VERSION ""

NS_ :

BS_:

BU_: ECM

BO_ 2566832128 SERV: 8 Vector__XXX
 SG_ SPN_0911 : 0|8@1+ (1,0) [0|255] "" Vector__XXX

BO_ 2565800175 HEFSR: 8 Vector__XXX
 SG_ FuelShutoffForHybrid : 0|2@1+ (1,0) [0|3] "unitless" Vector__XXX

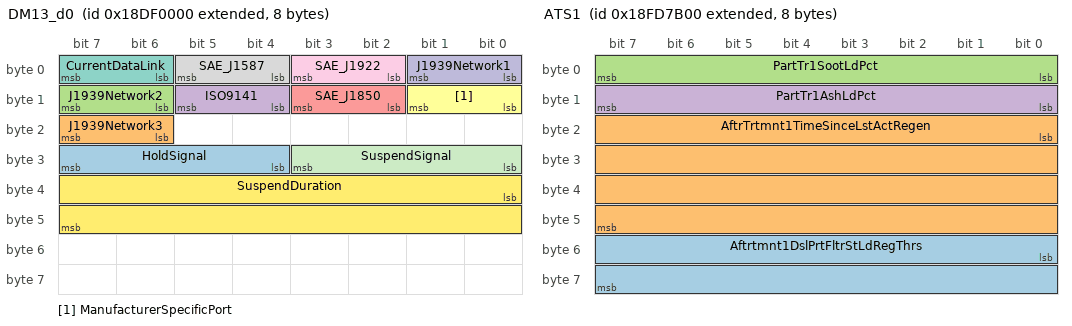
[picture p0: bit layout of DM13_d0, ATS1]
BO_ 2564751360 DM13_d0: 8 Vector__XXX
 SG_ HoldSignal : 28|4@1+ (1,0) [0|15] "" Vector__XXX
 SG_ J1939Network3 : 22|2@1+ (1,0) [0|3] "" Vector__XXX
 SG_ J1939Network2 : 14|2@1+ (1,0) [0|3] "" Vector__XXX
 SG_ ISO9141 : 12|2@1+ (1,0) [0|3] "" Vector__XXX
 SG_ SAE_J1850 : 10|2@1+ (1,0) [0|3] "" Vector__XXX
 SG_ ManufacturerSpecificPort : 8|2@1+ (1,0) [0|3] "" Vector__XXX
 SG_ CurrentDataLink : 6|2@1+ (1,0) [0|3] "" Vector__XXX
 SG_ SAE_J1587 : 4|2@1+ (1,0) [0|3] "" Vector__XXX
 SG_ SAE_J1922 : 2|2@1+ (1,0) [0|3] "" Vector__XXX
 SG_ J1939Network1 : 0|2@1+ (1,0) [0|3] "" Vector__XXX
 SG_ SuspendSignal : 24|4@1+ (1,0) [0|15] "" Vector__XXX
 SG_ SuspendDuration : 32|16@1+ (1,0) [0|64255] "seconds" Vector__XXX

BO_ 2566748416 ATI1: 32 Vector__XXX
 SG_ Aft1TripActiveRegenManRequests : 224|32@1+ (1,0) [0|4211081215] "Counts" Vector__XXX
 SG_ Aftertreatment1TripActiveRegens : 96|32@1+ (1,0) [0|4211081215] "Counts" Vector__XXX
 SG_ Aftertreatment1TripRegenTime : 32|32@1+ (1,0) [0|4211081215] "s" Vector__XXX
 SG_ Aftertreatment1TripFuelUsed : 0|32@1+ (0.5,0) [0|2105540607.5] "L" Vector__XXX

BO_ 2566748928 ATS1: 8 Vector__XXX
 SG_ Aftrtmnt1DslPrtFltrStLdRegThrs : 48|16@1+ (0.0025,0) [0|163.8375] "%" Vector__XXX
 SG_ AftrTrtmnt1TimeSinceLstActRegen : 16|32@1+ (1,0) [0|4211081215] "s" Vector__XXX
 SG_ PartTr1SootLdPct : 0|8@1+ (1,0) [0|250] "%" Vector__XXX
 SG_ PartTr1AshLdPct : 8|8@1+ (1,0) [0|250] "%" Vector__XXX

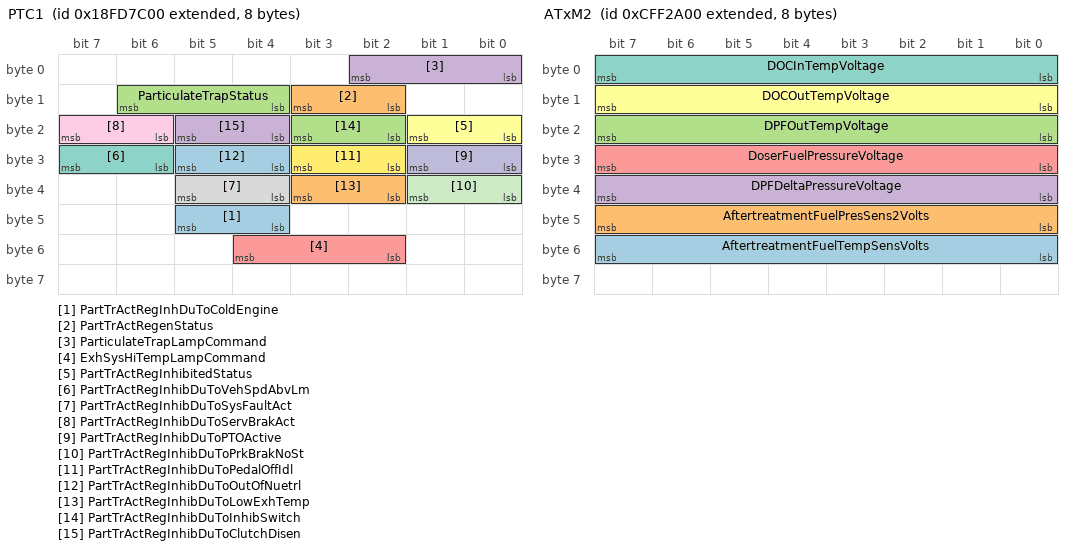
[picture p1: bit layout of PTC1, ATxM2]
BO_ 2566749184 PTC1: 8 Vector__XXX
 SG_ PartTrActRegInhDuToColdEngine : 44|2@1+ (1,0) [0|3] "" Vector__XXX
 SG_ PartTrActRegenStatus : 10|2@1+ (1,0) [0|3] "" Vector__XXX
 SG_ ParticulateTrapStatus : 12|3@1+ (1,0) [0|7] "" Vector__XXX
 SG_ ParticulateTrapLampCommand : 0|3@1+ (1,0) [0|7] "" Vector__XXX
 SG_ ExhSysHiTempLampCommand : 50|3@1+ (1,0) [0|7] "" Vector__XXX
 SG_ PartTrActRegInhibitedStatus : 16|2@1+ (1,0) [0|3] "" Vector__XXX
 SG_ PartTrActRegInhibDuToVehSpdAbvLm : 30|2@1+ (1,0) [0|3] "" Vector__XXX
 SG_ PartTrActRegInhibDuToSysFaultAct : 36|2@1+ (1,0) [0|3] "" Vector__XXX
 SG_ PartTrActRegInhibDuToServBrakAct : 22|2@1+ (1,0) [0|3] "" Vector__XXX
 SG_ PartTrActRegInhibDuToPTOActive : 24|2@1+ (1,0) [0|3] "" Vector__XXX
 SG_ PartTrActRegInhibDuToPrkBrakNoSt : 32|2@1+ (1,0) [0|3] "" Vector__XXX
 SG_ PartTrActRegInhibDuToPedalOffIdl : 26|2@1+ (1,0) [0|3] "" Vector__XXX
 SG_ PartTrActRegInhibDuToOutOfNuetrl : 28|2@1+ (1,0) [0|3] "" Vector__XXX
 SG_ PartTrActRegInhibDuToLowExhTemp : 34|2@1+ (1,0) [0|3] "" Vector__XXX
 SG_ PartTrActRegInhibDuToInhibSwitch : 18|2@1+ (1,0) [0|3] "" Vector__XXX
 SG_ PartTrActRegInhibDuToClutchDisen : 20|2@1+ (1,0) [0|3] "" Vector__XXX

BO_ 2565406464 ACKM_dall: 8 Vector__XXX
 SG_ AddressBusy m3 : 32|8@1+ (1,0) [0|255] "" Vector__XXX
 SG_ ParameterGroupNumber : 40|24@1+ (1,0) [0|16777215] "" Vector__XXX
 SG_ GroupFunctionValue : 8|8@1+ (1,0) [0|255] "" Vector__XXX
 SG_ ControlByte M : 0|8@1+ (1,0) [0|255] "" Vector__XXX
 SG_ AddressAccessDenied m2 : 32|8@1+ (1,0) [0|255] "" Vector__XXX
 SG_ AddressNegativeAcknowledgement m1 : 32|8@1+ (1,0) [0|255] "" Vector__XXX
 SG_ AddressAcknowledged m0 : 32|8@1+ (1,0) [0|255] "" Vector__XXX

BO_ 2365532672 ATxM2: 8 Vector__XXX
 SG_ AftertreatmentFuelTempSensVolts : 48|8@1+ (0.02,0) [0|5] "Volts" Vector__XXX
 SG_ AftertreatmentFuelPresSens2Volts : 40|8@1+ (0.02,0) [0|5] "Volts" Vector__XXX
 SG_ DPFOutTempVoltage : 16|8@1+ (0.02,0) [0|5] "Volts" Vector__XXX
 SG_ DPFDeltaPressureVoltage : 32|8@1+ (0.02,0) [0|5] "Volts" Vector__XXX
 SG_ DoserFuelPressureVoltage : 24|8@1+ (0.02,0) [0|5] "Volts" Vector__XXX
 SG_ DOCOutTempVoltage : 8|8@1+ (0.02,0) [0|5] "Volts" Vector__XXX
 SG_ DOCInTempVoltage : 0|8@1+ (0.02,0) [0|5] "Volts" Vector__XXX

BO_ 2566842624 LFC_s0: 8 Vector__XXX
 SG_ EngTotalFuelUsed : 32|32@1+ (0.5,0) [0|2105540607.5] "L" Vector__XXX
 SG_ EngTripFuel : 0|32@1+ (0.5,0) [0|2105540607.5] "L" Vector__XXX

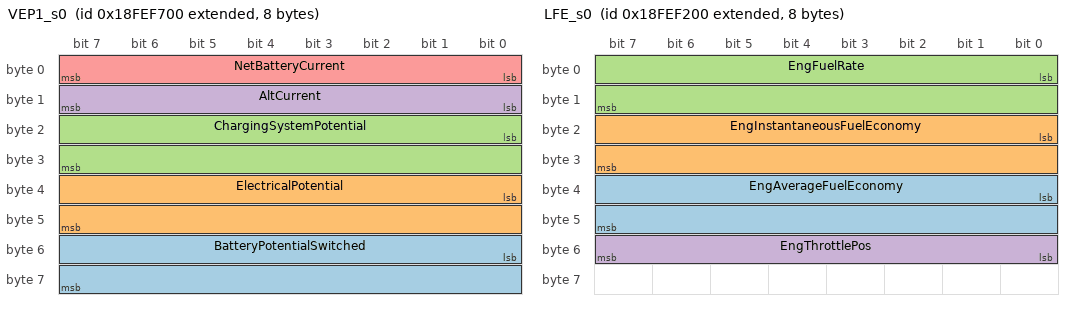
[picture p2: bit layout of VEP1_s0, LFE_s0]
BO_ 2566846208 VEP1_s0: 8 Vector__XXX
 SG_ BatteryPotentialSwitched : 48|16@1+ (0.05,0) [0|3212.75] "V" Vector__XXX
 SG_ ElectricalPotential : 32|16@1+ (0.05,0) [0|3212.75] "V" Vector__XXX
 SG_ ChargingSystemPotential : 16|16@1+ (0.05,0) [0|3212.75] "V" Vector__XXX
 SG_ AltCurrent : 8|8@1+ (1,0) [0|250] "A" Vector__XXX
 SG_ NetBatteryCurrent : 0|8@1+ (1,-125) [-125|125] "A" Vector__XXX

BO_ 2566844928 LFE_s0: 8 Vector__XXX
 SG_ EngAverageFuelEconomy : 32|16@1+ (0.001953125,0) [0|125.5] "km/L" Vector__XXX
 SG_ EngInstantaneousFuelEconomy : 16|16@1+ (0.001953125,0) [0|125.5] "km/L" Vector__XXX
 SG_ EngFuelRate : 0|16@1+ (0.05,0) [0|3212.75] "L/h" Vector__XXX
 SG_ EngThrottlePos : 48|8@1+ (0.4,0) [0|100] "%" Vector__XXX

BO_ 2566834688 DM1_s0: 22 Vector__XXX
 SG_ SPN5 : 144|16@1+ (1,0) [0|65536] "" Vector__XXX
 SG_ SPN4 : 112|16@1+ (1,0) [0|65536] "" Vector__XXX
 SG_ SPN3 : 80|16@1+ (1,0) [0|65536] "" Vector__XXX
 SG_ SPN2 : 48|16@1+ (1,0) [0|65536] "" Vector__XXX
 SG_ FailureModeIdentifier5 : 160|5@1+ (1,0) [0|0] "" Vector__XXX
 SG_ FailureModeIdentifier4 : 128|5@1+ (1,0) [0|0] "" Vector__XXX
 SG_ FailureModeIdentifier3 : 96|5@1+ (1,0) [0|0] "" Vector__XXX
 SG_ FlashRedStopLamp : 12|2@1+ (1,0) [0|3] "" Vector__XXX
 SG_ FlashProtectLamp : 8|2@1+ (1,0) [0|3] "" Vector__XXX
 SG_ FlashMalfuncIndicatorLamp : 14|2@1+ (1,0) [0|3] "" Vector__XXX
 SG_ FlashAmberWarningLamp : 10|2@1+ (1,0) [0|3] "" Vector__XXX
 SG_ MalfunctionIndicatorLampStatus : 6|2@1+ (1,0) [0|3] "" Vector__XXX
 SG_ AmberWarningLampStatus : 2|2@1+ (1,0) [0|3] "" Vector__XXX
 SG_ OccurenceCount1 : 40|7@1+ (1,0) [0|126] "" Vector__XXX
 SG_ SPNConversionMethod1 : 47|1@1+ (1,0) [0|1] "" Vector__XXX
 SG_ FailureModeIdentifier1 : 32|5@1+ (1,0) [0|0] "" Vector__XXX
 SG_ SPN1 : 16|16@1+ (1,0) [0|65536] "" Vector__XXX
 SG_ RedStopLampStatus : 4|2@1+ (1,0) [0|3] "" Vector__XXX
 SG_ ProtectLampStatus : 0|2@1+ (1,0) [0|3] "" Vector__XXX
 SG_ FailureModeIdentifier2 : 64|5@1+ (1,0) [0|0] "" Vector__XXX
 SG_ SPNConversionMethod5 : 175|1@1+ (1,0) [0|1] "" Vector__XXX
 SG_ SPNConversionMethod4 : 143|1@1+ (1,0) [0|1] "" Vector__XXX
 SG_ SPNConversionMethod3 : 111|1@1+ (1,0) [0|1] "" Vector__XXX
 SG_ SPNConversionMethod2 : 79|1@1+ (1,0) [0|1] "" Vector__XXX
 SG_ OccurenceCount5 : 168|7@1+ (1,0) [0|126] "" Vector__XXX
 SG_ OccurenceCount4 : 136|7@1+ (1,0) [0|126] "" Vector__XXX
 SG_ OccurenceCount3 : 104|7@1+ (1,0) [0|126] "" Vector__XXX
 SG_ OccurenceCount2 : 72|7@1+ (1,0) [0|126] "" Vector__XXX
 SG_ SPN5High : 165|3@1+ (1,0) [0|7] "" Vector__XXX
 SG_ SPN4High : 133|3@1+ (1,0) [0|7] "" Vector__XXX
 SG_ SPN3High : 101|3@1+ (1,0) [0|7] "" Vector__XXX
 SG_ SPN2High : 69|3@1+ (1,0) [0|7] "" Vector__XXX
 SG_ SPN1High : 37|3@1+ (1,0) [0|7] "" Vector__XXX

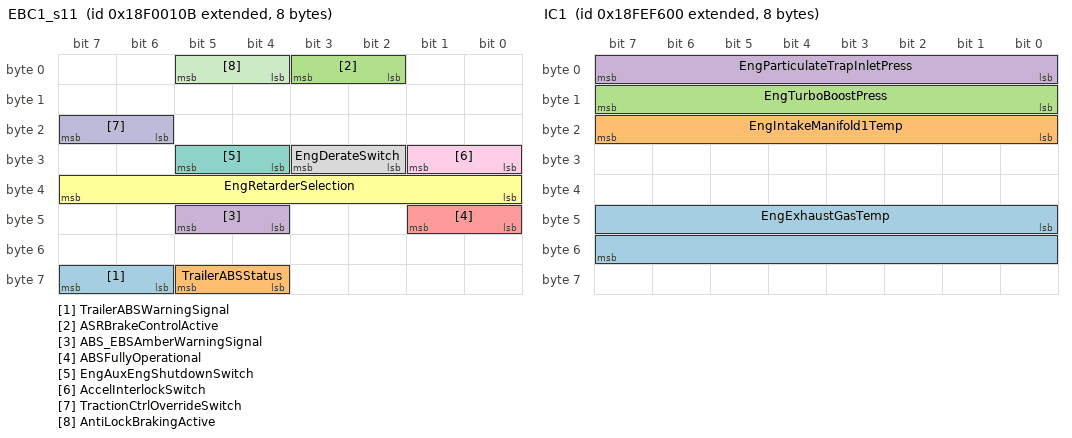
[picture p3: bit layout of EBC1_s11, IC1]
BO_ 2565865739 EBC1_s11: 8 Vector__XXX
 SG_ TrailerABSWarningSignal : 62|2@1+ (1,0) [0|3] "" Vector__XXX
 SG_ TrailerABSStatus : 60|2@1+ (1,0) [0|3] "" Vector__XXX
 SG_ ASRBrakeControlActive : 2|2@1+ (1,0) [0|3] "" Vector__XXX
 SG_ ABS_EBSAmberWarningSignal : 44|2@1+ (1,0) [0|3] "" Vector__XXX
 SG_ ABSFullyOperational : 40|2@1+ (1,0) [0|3] "" Vector__XXX
 SG_ EngRetarderSelection : 32|8@1+ (0.4,0) [0|100] "%" Vector__XXX
 SG_ EngAuxEngShutdownSwitch : 28|2@1+ (1,0) [0|3] "" Vector__XXX
 SG_ EngDerateSwitch : 26|2@1+ (1,0) [0|3] "" Vector__XXX
 SG_ AccelInterlockSwitch : 24|2@1+ (1,0) [0|3] "" Vector__XXX
 SG_ TractionCtrlOverrideSwitch : 22|2@1+ (1,0) [0|3] "" Vector__XXX
 SG_ AntiLockBrakingActive : 4|2@1+ (1,0) [0|3] "" Vector__XXX

BO_ 2565668608 TPCM_s0: 8 Vector__XXX
 SG_ TotalNumberOfPacketsEoMA m19 : 24|8@1+ (1,0) [0|255] "" Vector__XXX
 SG_ TotalMessageSizeEoMA m19 : 8|16@1+ (1,0) [0|64255] "counts" Vector__XXX
 SG_ TotalMessageSizeBAM m32 : 8|16@1+ (1,0) [0|64255] "counts" Vector__XXX
 SG_ TotalNumberOfPacketsBAM m32 : 24|8@1+ (1,0) [0|255] "" Vector__XXX
 SG_ ConnectionAbortReason m255 : 8|8@1+ (1,0) [0|255] "" Vector__XXX
 SG_ NextPacketNumberToBeSent m17 : 16|8@1+ (1,0) [0|255] "" Vector__XXX
 SG_ NumberOfPacketsThatCanBeSent m17 : 8|8@1+ (1,0) [0|255] "" Vector__XXX
 SG_ PGNumber : 40|24@1+ (1,0) [0|16777200] "" Vector__XXX
 SG_ MaximumNumberOfPackets m16 : 32|8@1+ (1,0) [0|255] "" Vector__XXX
 SG_ TotalNumberOfPackets m16 : 24|8@1+ (1,0) [0|255] "" Vector__XXX
 SG_ TotalMessageSize m16 : 8|16@1+ (1,0) [0|64255] "counts" Vector__XXX
 SG_ ControlByte M : 0|8@1+ (1,0) [0|255] "" Vector__XXX

BO_ 2565472279 RQST_d0: 3 Vector__XXX
 SG_ ParameterGroupNumber : 0|24@1+ (1,0) [0|16777215] "" Vector__XXX

BO_ 2566839296 IO: 8 Vector__XXX
 SG_ EngTotalIdleHours : 32|32@1+ (0.05,0) [0|210554060.75] "hr" Vector__XXX
 SG_ EngTotalIdleFuelUsed : 0|32@1+ (0.5,0) [0|2105540607.5] "L" Vector__XXX

BO_ 2566845952 IC1: 8 Vector__XXX
 SG_ EngExhaustGasTemp : 40|16@1+ (0.03125,-273) [-273|1735] "°C" Vector__XXX
 SG_ EngIntakeManifold1Temp : 16|8@1+ (1,-40) [-40|210] "°C" Vector__XXX
 SG_ EngTurboBoostPress : 8|8@1+ (2,0) [0|500] "kPa" Vector__XXX
 SG_ EngParticulateTrapInletPress : 0|8@1+ (0.5,0) [0|125] "kPa" Vector__XXX

BO_ 2565867774 HPG: 8 Vector__XXX
 SG_ FireApparatusPumpEngagement : 20|2@1+ (1,0) [0|3] "" Vector__XXX
 SG_ EngHydPressGovernorSwitch : 18|2@1+ (1,0) [0|3] "" Vector__XXX

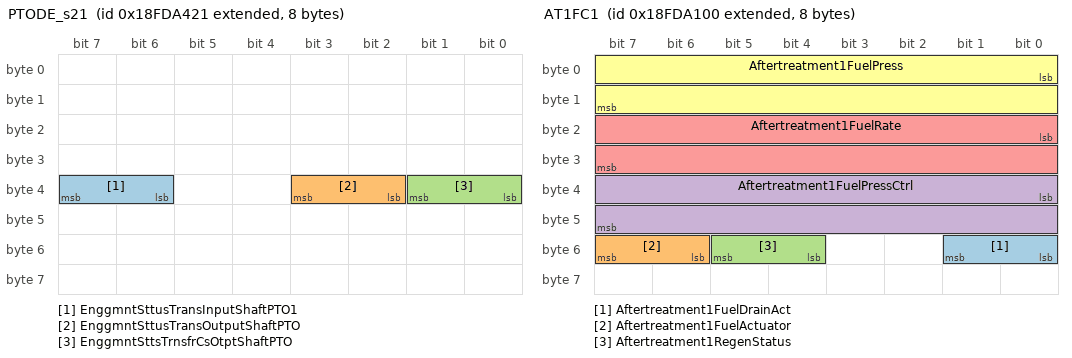
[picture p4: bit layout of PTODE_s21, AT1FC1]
BO_ 2566759457 PTODE_s21: 8 Vector__XXX
 SG_ EnggmntSttusTransInputShaftPTO1 : 38|2@1+ (1,0) [0|3] "" Vector__XXX
 SG_ EnggmntSttusTransOutputShaftPTO : 34|2@1+ (1,0) [0|3] "" Vector__XXX
 SG_ EnggmntSttsTrnsfrCsOtptShaftPTO : 32|2@1+ (1,0) [0|3] "" Vector__XXX

BO_ 2566758656 AT1FC1: 8 Vector__XXX
 SG_ Aftertreatment1FuelDrainAct : 48|2@1+ (1,0) [0|3] "none" Vector__XXX
 SG_ Aftertreatment1FuelActuator : 54|2@1+ (1,0) [0|3] "" Vector__XXX
 SG_ Aftertreatment1RegenStatus : 52|2@1+ (1,0) [0|3] "" Vector__XXX
 SG_ Aftertreatment1FuelPressCtrl : 32|16@1+ (0.0025,0) [0|160.6375] "%" Vector__XXX
 SG_ Aftertreatment1FuelRate : 16|16@1+ (0.05,0) [0|3212.75] "L/h" Vector__XXX
 SG_ Aftertreatment1FuelPress : 0|16@1+ (0.1,0) [0|6425.5] "kPa" Vector__XXX

BO_ 2566756352 AHI1: 32 Vector__XXX
 SG_ Aftertreatment1AvgTimeBetRegn : 256|32@1+ (1,0) [0|4211081215] "s" Vector__XXX
 SG_ AftrTrtmnt1TtlActvRgnInhRqsts : 192|32@1+ (1,0) [0|4211081215] "s" Vector__XXX
 SG_ AftrTrtmnt1TtlActvRgnMnlRqsts : 224|32@1+ (1,0) [0|4211081215] "s" Vector__XXX
 SG_ Aftertreatment1TotalNumActRegens : 96|32@1+ (1,0) [0|4294967295] "counts" Vector__XXX
 SG_ Aftertreatment1TotalRegenTime : 32|32@1+ (1,0) [0|4211081215] "s" Vector__XXX
 SG_ Aftertreatment1TotalDisabledTime : 64|32@1+ (1,0) [0|4211081215] "s" Vector__XXX
 SG_ Aftertreatment1TotalFuelUsed : 0|32@1+ (0.5,0) [0|2105540607.5] "L" Vector__XXX

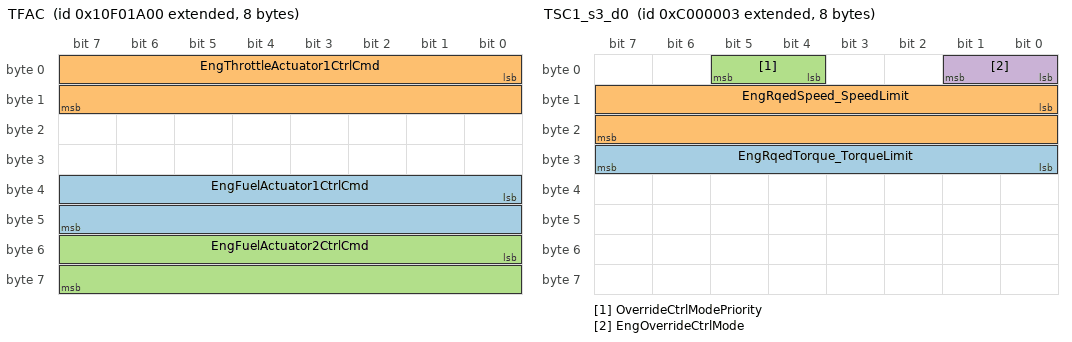
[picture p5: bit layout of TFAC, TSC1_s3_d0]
BO_ 2431654400 TFAC: 8 Vector__XXX
 SG_ EngFuelActuator1CtrlCmd : 32|16@1+ (0.0025,0) [0|160.6375] "%" Vector__XXX
 SG_ EngThrottleActuator1CtrlCmd : 0|16@1+ (0.0025,0) [0|160.6375] "%" Vector__XXX
 SG_ EngFuelActuator2CtrlCmd : 48|16@1+ (0.0025,0) [0|160.6375] "%" Vector__XXX

BO_ 2566764544 DM26: 8 Vector__XXX
 SG_ PMFilterMonComplete : 58|1@1+ (1,0) [0|1] "" Vector__XXX
 SG_ NOxCnvrtctlystMonComplete : 59|1@1+ (1,0) [0|1] "" Vector__XXX
 SG_ NHMCCnvrtctlystMonComplete : 60|1@1+ (1,0) [0|1] "" Vector__XXX
 SG_ BstPressCtrlSystemMoncomplete : 57|1@1+ (1,0) [0|1] "" Vector__XXX
 SG_ NHMCCnvrtctlystMonEnabled : 44|1@1+ (1,0) [0|1] "" Vector__XXX
 SG_ NOxCnvrtctlystMonEnabled : 43|1@1+ (1,0) [0|1] "" Vector__XXX
 SG_ PMFilterMonEnabled : 42|1@1+ (1,0) [0|1] "" Vector__XXX
 SG_ BstPressCtrlSystemMonEnabled : 41|1@1+ (1,0) [0|1] "" Vector__XXX
 SG_ MisfireMonitoringComplete : 28|1@1+ (1,0) [0|0] "" Vector__XXX
 SG_ MisfireMonitoringEnabled : 24|1@1+ (1,0) [0|0] "" Vector__XXX
 SG_ FuelSystemMonitoringEnabled : 25|1@1+ (1,0) [0|1] "" Vector__XXX
 SG_ ComprehensiveComptMonComplete : 30|1@1+ (1,0) [0|0] "" Vector__XXX
 SG_ ComprehensiveCompMonEnabled : 26|1@1+ (1,0) [0|1] "" Vector__XXX
 SG_ SecondAirSystemMonComplete : 51|1@1+ (1,0) [0|1] "" Vector__XXX
 SG_ SecondAirSystemMonEnabled : 35|1@1+ (1,0) [0|1] "" Vector__XXX
 SG_ OxygenSensorMonComplete : 53|1@1+ (1,0) [0|1] "" Vector__XXX
 SG_ OxygenSensorMonEnabled : 37|1@1+ (1,0) [0|1] "" Vector__XXX
 SG_ OxygenSensorHeaterMonComplete : 54|1@1+ (1,0) [0|1] "" Vector__XXX
 SG_ OxygenSensorHeaterMonEnabled : 38|1@1+ (1,0) [0|1] "" Vector__XXX
 SG_ HeatedCatalystMonComplete : 49|1@1+ (1,0) [0|0] "" Vector__XXX
 SG_ HeatedCatalystMonEnabled : 33|1@1+ (1,0) [0|0] "" Vector__XXX
 SG_ EvaporativeSystemMonComplete : 50|1@1+ (1,0) [0|1] "" Vector__XXX
 SG_ EvaporativeSystemMonEnabled : 34|1@1+ (1,0) [0|1] "" Vector__XXX
 SG_ EGRSystemMonitoringComplete : 55|1@1+ (1,0) [0|1] "" Vector__XXX
 SG_ EGRSystemMonitoringEnabled : 39|1@1+ (1,0) [0|1] "" Vector__XXX
 SG_ ColdStartAidSystemMonComplete : 56|1@1+ (1,0) [0|1] "" Vector__XXX
 SG_ ColdStartAidSystemMonEnabled : 40|1@1+ (1,0) [0|1] "" Vector__XXX
 SG_ CatalystMonComplete : 48|1@1+ (1,0) [0|1] "" Vector__XXX
 SG_ CatalystMonEnabled : 32|1@1+ (1,0) [0|1] "" Vector__XXX
 SG_ ACSystemRefrigerantMonComplete : 52|1@1+ (1,0) [0|1] "" Vector__XXX
 SG_ ACSystemRefrigerantMonEnabled : 36|1@1+ (1,0) [0|1] "" Vector__XXX
 SG_ FuelSystemMonitoringComplete : 29|1@1+ (1,0) [0|1] "" Vector__XXX
 SG_ NumOfWarmUpsSinceDTCsCleared : 16|8@1+ (1,0) [0|250] "" Vector__XXX
 SG_ TimeSinceEngineStart : 0|16@1+ (1,0) [0|64255] "seconds" Vector__XXX

BO_ 2566843392 VI: 18 Vector__XXX
 SG_ VI_Delimiter : 136|8@1+ (1,0) [0|0] "ASCII" Vector__XXX
 SG_ VIN_B17 : 128|8@1+ (1,0) [0|0] "ASCII" Vector__XXX
 SG_ VIN_B09_B016 : 64|64@1+ (1,0) [0|0] "ASCII" Vector__XXX
 SG_ VIN_B01_B08 : 0|64@1+ (1,0) [0|0] "ASCII" Vector__XXX

BO_ 2566842112 VH: 8 Vector__XXX
 SG_ TotalPowerTakeoffHours : 32|32@1+ (0.05,0) [0|210554060.75] "hr" Vector__XXX
 SG_ TotalVehicleHours : 0|32@1+ (0.05,0) [0|210554060.75] "hr" Vector__XXX

BO_ 2566832384 VDHR: 8 Vector__XXX
 SG_ HighResolutionTripDistance : 32|32@1+ (0.005,0) [0|21474836.475] "km" Vector__XXX
 SG_ HghRslutionTotalVehicleDistance : 0|32@1+ (0.005,0) [0|21055406] "km" Vector__XXX

BO_ 2348810243 TSC1_s3_d0: 8 Vector__XXX
 SG_ EngRqedTorque_TorqueLimit : 24|8@1+ (1,-125) [-125|125] "%" Vector__XXX
 SG_ EngRqedSpeed_SpeedLimit : 8|16@1+ (0.125,0) [0|8031.875] "rpm" Vector__XXX
 SG_ OverrideCtrlModePriority : 4|2@1+ (1,0) [0|3] "" Vector__XXX
 SG_ EngOverrideCtrlMode : 0|2@1+ (1,0) [0|3] "" Vector__XXX

BO_ 2633939712 TFI: 16 Vector__XXX
 SG_ TripFanOnTime : 0|32@1+ (0.05,0) [0|210554060.75] "hr" Vector__XXX

BO_ 2566821376 TCW: 8 Vector__XXX
 SG_ EngTurbo2WastegateDrive : 8|8@1+ (0.4,0) [0|100] "%" Vector__XXX
 SG_ EngTurbo1WastegateDrive : 0|8@1+ (0.4,0) [0|100] "%" Vector__XXX

BO_ 2566822400 TCI2: 8 Vector__XXX
 SG_ EngTurbo2CompressorInletTemp : 16|16@1+ (0.03125,-273) [-273|1735] "°C" Vector__XXX

BO_ 2566802179 TCFG2: 8 Vector__XXX
 SG_ TransTorqueLimit : 0|16@1+ (1,0) [0|64255] "Nm" Vector__XXX

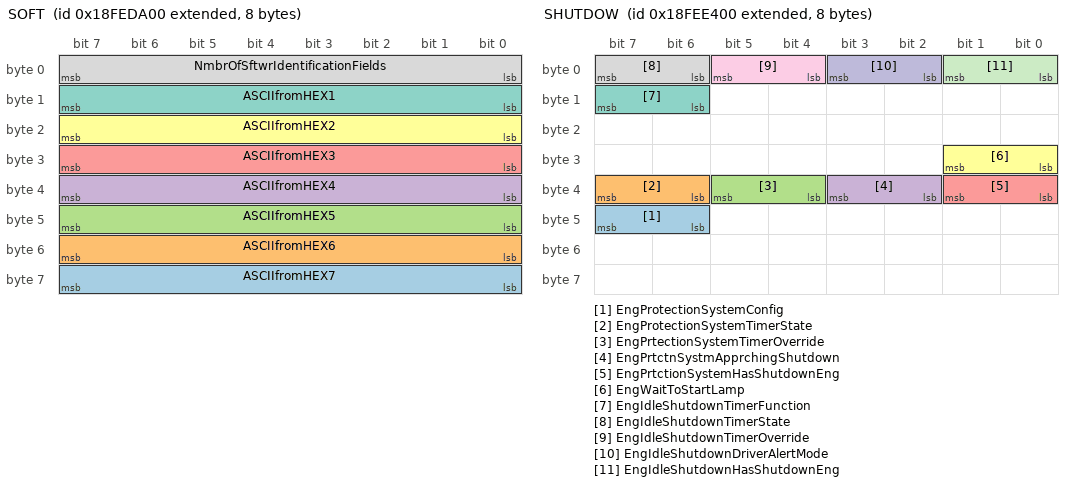
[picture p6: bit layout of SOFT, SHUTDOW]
BO_ 2566838784 SOFT: 8 Vector__XXX
 SG_ ASCIIfromHEX7 : 56|8@1+ (1,0) [0|0] "ASCII" Vector__XXX
 SG_ ASCIIfromHEX6 : 48|8@1+ (1,0) [0|0] "ASCII" Vector__XXX
 SG_ ASCIIfromHEX5 : 40|8@1+ (1,0) [0|0] "ASCII" Vector__XXX
 SG_ ASCIIfromHEX4 : 32|8@1+ (1,0) [0|0] "ASCII" Vector__XXX
 SG_ ASCIIfromHEX3 : 24|8@1+ (1,0) [0|0] "ASCII" Vector__XXX
 SG_ ASCIIfromHEX2 : 16|8@1+ (1,0) [0|0] "ASCII" Vector__XXX
 SG_ ASCIIfromHEX1 : 8|8@1+ (1,0) [0|0] "ASCII" Vector__XXX
 SG_ NmbrOfSftwrIdentificationFields : 0|8@1+ (1,0) [0|250] "steps" Vector__XXX

BO_ 2566841344 SHUTDOW: 8 Vector__XXX
 SG_ EngProtectionSystemConfig : 46|2@1+ (1,0) [0|3] "" Vector__XXX
 SG_ EngProtectionSystemTimerState : 38|2@1+ (1,0) [0|3] "" Vector__XXX
 SG_ EngPrtectionSystemTimerOverride : 36|2@1+ (1,0) [0|3] "" Vector__XXX
 SG_ EngPrtctnSystmApprchingShutdown : 34|2@1+ (1,0) [0|3] "" Vector__XXX
 SG_ EngPrtctionSystemHasShutdownEng : 32|2@1+ (1,0) [0|3] "" Vector__XXX
 SG_ EngWaitToStartLamp : 24|2@1+ (1,0) [0|3] "" Vector__XXX
 SG_ EngIdleShutdownTimerFunction : 14|2@1+ (1,0) [0|3] "" Vector__XXX
 SG_ EngIdleShutdownTimerState : 6|2@1+ (1,0) [0|3] "" Vector__XXX
 SG_ EngIdleShutdownTimerOverride : 4|2@1+ (1,0) [0|3] "" Vector__XXX
 SG_ EngIdleShutdownDriverAlertMode : 2|2@1+ (1,0) [0|3] "" Vector__XXX
 SG_ EngIdleShutdownHasShutdownEng : 0|2@1+ (1,0) [0|3] "" Vector__XXX

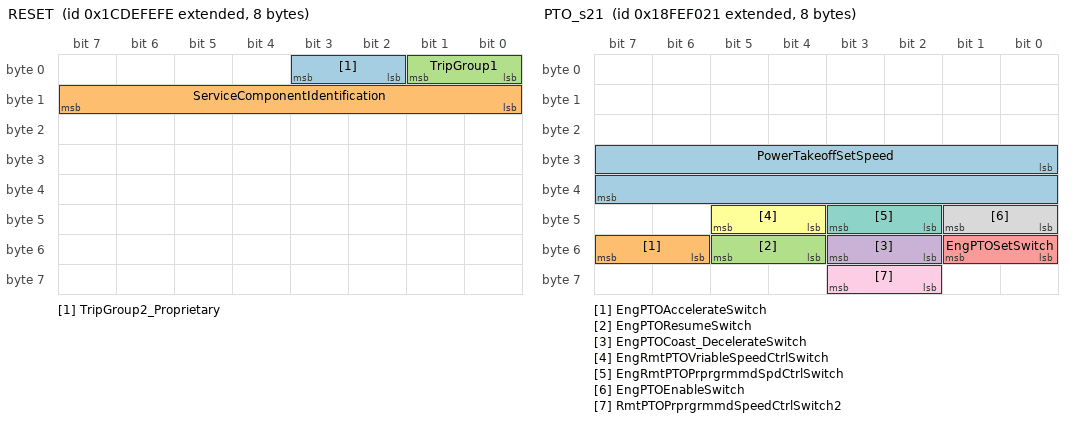
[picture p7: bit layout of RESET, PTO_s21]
BO_ 2631859966 RESET: 8 Vector__XXX
 SG_ TripGroup2_Proprietary : 2|2@1+ (1,0) [0|3] "" Vector__XXX
 SG_ ServiceComponentIdentification : 8|8@1+ (1,0) [0|250] "ID" Vector__XXX
 SG_ TripGroup1 : 0|2@1+ (1,0) [0|3] "" Vector__XXX

BO_ 2566840591 RC: 19 Vector__XXX
 SG_ PercentTorqueAtPeakTorquePoint5 : 144|8@1+ (1,-125) [-125|125] "%" Vector__XXX
 SG_ ReferenceRetarderTorque : 128|16@1+ (1,0) [0|64255] "Nm" Vector__XXX
 SG_ RetarderSpeedAtPeakTorquePoint5 : 112|16@1+ (0.125,0) [0|8031.875] "rpm" Vector__XXX
 SG_ PercentTorqueAtPoint4 : 104|8@1+ (1,-125) [-125|125] "%" Vector__XXX
 SG_ RetarderSpeedAtPoint4 : 88|16@1+ (0.125,0) [0|8031.875] "rpm" Vector__XXX
 SG_ PercentTorqueAtPoint3 : 80|8@1+ (1,-125) [-125|125] "%" Vector__XXX
 SG_ RetarderSpeedAtPoint3 : 64|16@1+ (0.125,0) [0|8031.875] "rpm" Vector__XXX
 SG_ PercentTorqueAtMaxSpeedPoint2 : 56|8@1+ (1,-125) [-125|125] "%" Vector__XXX
 SG_ MaxRetarderSpeedPoint2 : 40|16@1+ (0.125,0) [0|8031.875] "rpm" Vector__XXX
 SG_ PercentTorqueAtIdlePoint1 : 32|8@1+ (1,-125) [-125|125] "%" Vector__XXX
 SG_ RetarderSpeedAtIdlePoint1 : 16|16@1+ (0.125,0) [0|8031.875] "rpm" Vector__XXX
 SG_ RetarderLocation : 4|4@1+ (1,0) [0|15] "" Vector__XXX
 SG_ RetarderType : 0|4@1+ (1,0) [0|15] "" Vector__XXX

BO_ 2566844449 PTO_s21: 8 Vector__XXX
 SG_ PowerTakeoffSetSpeed : 24|16@1+ (0.125,0) [0|8031.875] "rpm" Vector__XXX
 SG_ EngPTOAccelerateSwitch : 54|2@1+ (1,0) [0|3] "" Vector__XXX
 SG_ EngPTOResumeSwitch : 52|2@1+ (1,0) [0|3] "" Vector__XXX
 SG_ EngPTOCoast_DecelerateSwitch : 50|2@1+ (1,0) [0|3] "" Vector__XXX
 SG_ EngPTOSetSwitch : 48|2@1+ (1,0) [0|3] "" Vector__XXX
 SG_ EngRmtPTOVriableSpeedCtrlSwitch : 44|2@1+ (1,0) [0|3] "" Vector__XXX
 SG_ EngRmtPTOPrprgrmmdSpdCtrlSwitch : 42|2@1+ (1,0) [0|3] "" Vector__XXX
 SG_ EngPTOEnableSwitch : 40|2@1+ (1,0) [0|3] "" Vector__XXX
 SG_ RmtPTOPrprgrmmdSpeedCtrlSwitch2 : 58|2@1+ (1,0) [0|3] "" Vector__XXX

BO_ 2633937664 LFI: 8 Vector__XXX
 SG_ TripAverageFuelRate : 32|16@1+ (0.05,0) [0|3212.75] "L/h" Vector__XXX
 SG_ TotalEngPTOFuelUsed : 0|32@1+ (0.5,0) [0|2105540607.5] "L" Vector__XXX

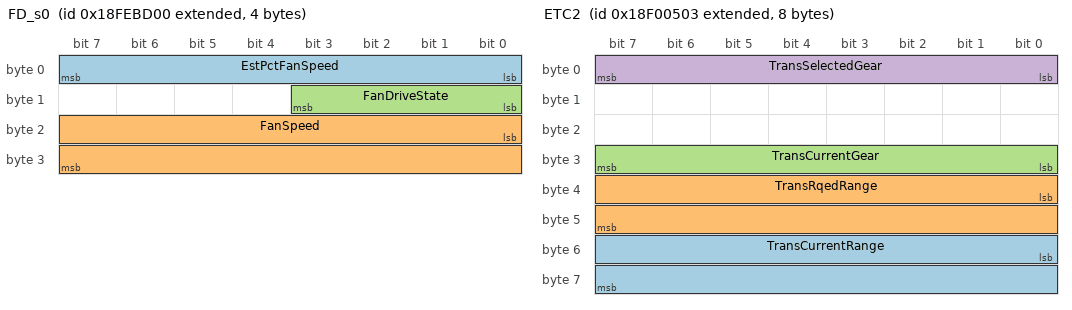
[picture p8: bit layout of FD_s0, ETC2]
BO_ 2566831360 FD_s0: 4 Vector__XXX
 SG_ EstPctFanSpeed : 0|8@1+ (0.4,0) [0|100] "%" Vector__XXX
 SG_ FanSpeed : 16|16@1+ (0.125,0) [0|8031.875] "rpm" Vector__XXX
 SG_ FanDriveState : 8|4@1+ (1,0) [0|15] "" Vector__XXX

BO_ 2565866755 ETC2: 8 Vector__XXX
 SG_ TransCurrentRange : 48|16@1+ (1,0) [0|255] "" Vector__XXX
 SG_ TransRqedRange : 32|16@1+ (1,0) [0|255] "" Vector__XXX
 SG_ TransCurrentGear : 24|8@1+ (1,-125) [-125|125] "" Vector__XXX
 SG_ TransSelectedGear : 0|8@1+ (1,-125) [-125|125] "" Vector__XXX

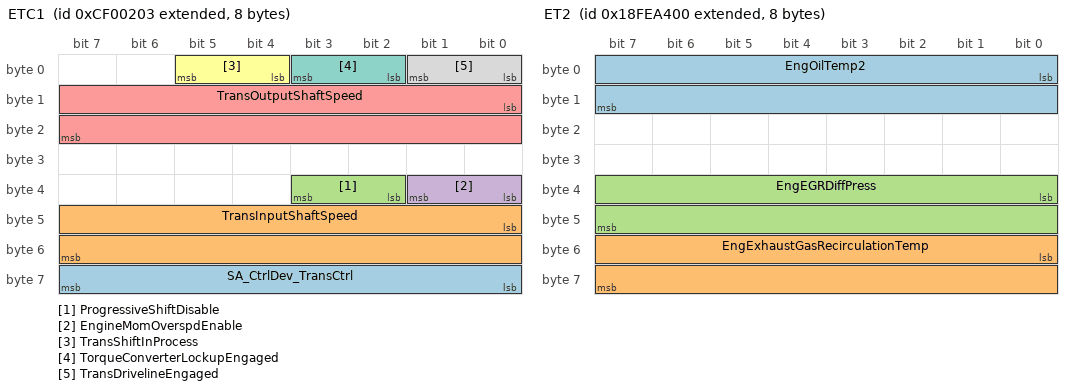
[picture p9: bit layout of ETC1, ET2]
BO_ 2364539395 ETC1: 8 Vector__XXX
 SG_ SA_CtrlDev_TransCtrl : 56|8@1+ (1,0) [0|255] "" Vector__XXX
 SG_ TransInputShaftSpeed : 40|16@1+ (0.125,0) [0|8031.875] "rpm" Vector__XXX
 SG_ ProgressiveShiftDisable : 34|2@1+ (1,0) [0|3] "" Vector__XXX
 SG_ EngineMomOverspdEnable : 32|2@1+ (1,0) [0|3] "" Vector__XXX
 SG_ TransOutputShaftSpeed : 8|16@1+ (0.125,0) [0|8031.875] "rpm" Vector__XXX
 SG_ TransShiftInProcess : 4|2@1+ (1,0) [0|3] "" Vector__XXX
 SG_ TorqueConverterLockupEngaged : 2|2@1+ (1,0) [0|3] "" Vector__XXX
 SG_ TransDrivelineEngaged : 0|2@1+ (1,0) [0|3] "" Vector__XXX

BO_ 2566809856 ET3: 8 Vector__XXX
 SG_ EngChargeAirCoolerOutletTemp : 48|16@1+ (0.03125,-273) [-273|1735] "°C" Vector__XXX
 SG_ EngIntakeManifold1AirTemp : 0|16@1+ (0.03125,-273) [-273|1735] "°C" Vector__XXX

BO_ 2566824960 ET2: 8 Vector__XXX
 SG_ EngOilTemp2 : 0|16@1+ (0.03125,-273) [-273|1735] "°C" Vector__XXX
 SG_ EngExhaustGasRecirculationTemp : 48|16@1+ (0.03125,-273) [-273|1735] "°C" Vector__XXX
 SG_ EngEGRDiffPress : 32|16@1+ (0.0078125,-250) [-250|251.99] "kPa" Vector__XXX

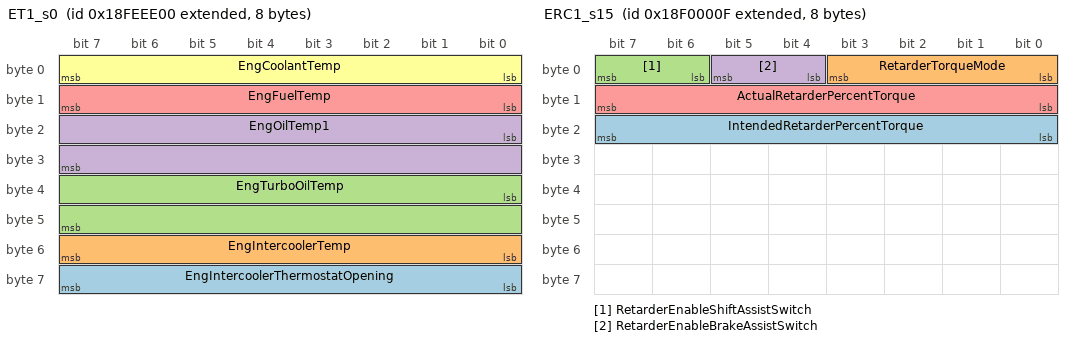
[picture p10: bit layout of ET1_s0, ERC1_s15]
BO_ 2566843904 ET1_s0: 8 Vector__XXX
 SG_ EngIntercoolerThermostatOpening : 56|8@1+ (0.4,0) [0|100] "%" Vector__XXX
 SG_ EngIntercoolerTemp : 48|8@1+ (1,-40) [-40|210] "°C" Vector__XXX
 SG_ EngTurboOilTemp : 32|16@1+ (0.03125,-273) [-273|1735] "°C" Vector__XXX
 SG_ EngOilTemp1 : 16|16@1+ (0.03125,-273) [-273|1735] "°C" Vector__XXX
 SG_ EngFuelTemp : 8|8@1+ (1,-40) [-40|210] "°C" Vector__XXX
 SG_ EngCoolantTemp : 0|8@1+ (1,-40) [-40|210] "°C" Vector__XXX

BO_ 2565865487 ERC1_s15: 8 Vector__XXX
 SG_ IntendedRetarderPercentTorque : 16|8@1- (1,-125) [-125|125] "" Vector__XXX
 SG_ RetarderTorqueMode : 0|4@1- (1,0) [0|15] "" Vector__XXX
 SG_ RetarderEnableShiftAssistSwitch : 6|2@1+ (1,0) [0|3] "" Vector__XXX
 SG_ RetarderEnableBrakeAssistSwitch : 4|2@1+ (1,0) [0|3] "" Vector__XXX
 SG_ ActualRetarderPercentTorque : 8|8@1+ (1,-125) [-125|125] "%" Vector__XXX

BO_ 2633937152 EH: 8 Vector__XXX
 SG_ TotalECURunTime : 32|32@1+ (0.05,0) [0|210554060.75] "hr" Vector__XXX
 SG_ TotalECUDistance : 0|32@1+ (0.125,0) [0|526385151.9] "km" Vector__XXX

BO_ 2364541440 EGF1: 8 Vector__XXX
 SG_ EngInletAirMassFlowRate : 16|16@1+ (0.05,0) [0|3212.75] "kg/h" Vector__XXX
 SG_ EngExhstGsRcrcltionMassFlowRate : 0|16@1+ (0.05,0) [0|3212.75] "kg/h" Vector__XXX

BO_ 2566839040 EFL_P2: 8 Vector__XXX
 SG_ EngInjectorMeteringRail1Press : 16|16@1+ (0.00390625,0) [0|251] "MPa" Vector__XXX

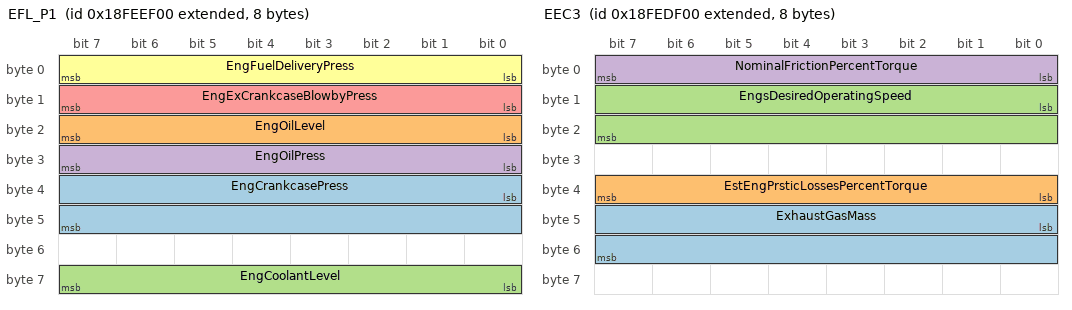
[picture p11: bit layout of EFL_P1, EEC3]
BO_ 2566844160 EFL_P1: 8 Vector__XXX
 SG_ EngCrankcasePress : 32|16@1+ (0.0078125,-250) [-250|261.9921875] "kPa" Vector__XXX
 SG_ EngOilLevel : 16|8@1+ (0.4,0) [0|102] "%" Vector__XXX
 SG_ EngCoolantLevel : 56|8@1+ (0.4,0) [0|100] "%" Vector__XXX
 SG_ EngOilPress : 24|8@1+ (4,0) [0|1000] "kPa" Vector__XXX
 SG_ EngExCrankcaseBlowbyPress : 8|8@1+ (0.05,0) [0|12.5] "kPa" Vector__XXX
 SG_ EngFuelDeliveryPress : 0|8@1+ (4,0) [0|1000] "kPa" Vector__XXX

BO_ 2566771968 EEC5: 8 Vector__XXX
 SG_ EngFuelControlStatus : 50|2@1+ (1,0) [0|3] "" Vector__XXX
 SG_ EngExhstGsRcirculationValveCtrl : 32|16@1+ (0.0025,0) [0|160.6375] "%" Vector__XXX

BO_ 2566840064 EEC3: 8 Vector__XXX
 SG_ ExhaustGasMass : 40|16@1+ (0.2,0) [0|13107] "kg/hr" Vector__XXX
 SG_ EstEngPrsticLossesPercentTorque : 32|8@1+ (1,-125) [-125|125] "%" Vector__XXX
 SG_ EngsDesiredOperatingSpeed : 8|16@1+ (0.125,0) [0|8031.875] "rpm" Vector__XXX
 SG_ NominalFrictionPercentTorque : 0|8@1+ (1,-125) [-125|125] "%" Vector__XXX

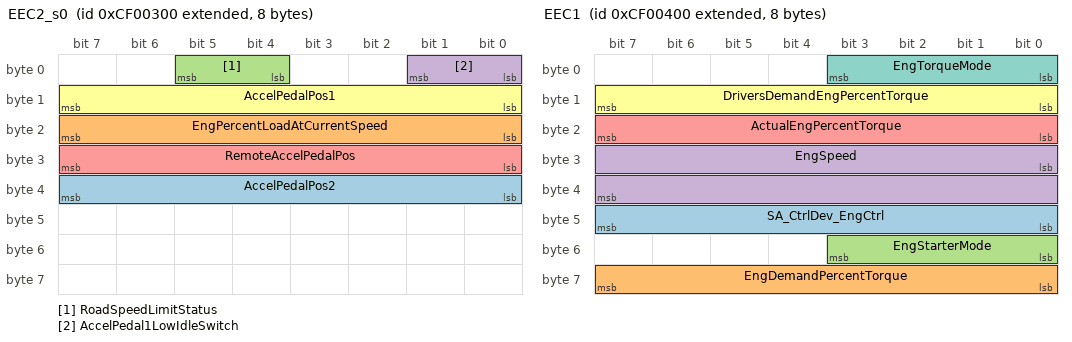
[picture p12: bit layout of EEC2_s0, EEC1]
BO_ 2364539648 EEC2_s0: 8 Vector__XXX
 SG_ AccelPedalPos2 : 32|8@1+ (0.4,0) [0|100] "%" Vector__XXX
 SG_ EngPercentLoadAtCurrentSpeed : 16|8@1+ (1,0) [0|250] "%" Vector__XXX
 SG_ RoadSpeedLimitStatus : 4|2@1+ (1,0) [0|3] "" Vector__XXX
 SG_ AccelPedal1LowIdleSwitch : 0|2@1+ (1,0) [0|3] "" Vector__XXX
 SG_ RemoteAccelPedalPos : 24|8@1+ (0.4,0) [0|100] "%" Vector__XXX
 SG_ AccelPedalPos1 : 8|8@1+ (0.4,0) [0|100] "%" Vector__XXX

BO_ 2364539904 EEC1: 8 Vector__XXX
 SG_ SA_CtrlDev_EngCtrl : 40|8@1+ (1,0) [0|255] "" Vector__XXX
 SG_ EngDemandPercentTorque : 56|8@1+ (1,-125) [-125|125] "%" Vector__XXX
 SG_ EngStarterMode : 48|4@1+ (1,0) [0|15] "" Vector__XXX
 SG_ EngSpeed : 24|16@1+ (0.125,0) [0|8031.875] "rpm" Vector__XXX
 SG_ ActualEngPercentTorque : 16|8@1+ (1,-125) [-125|125] "%" Vector__XXX
 SG_ DriversDemandEngPercentTorque : 8|8@1+ (1,-125) [-125|125] "%" Vector__XXX
 SG_ EngTorqueMode : 0|4@1+ (1,0) [0|15] "" Vector__XXX

CM_ BO_ 2566832128 "Service Information";
CM_ BO_ 2564751360 "Stop start broadcast";
CM_ SG_ 2564751360 HoldSignal "Indicator to all nodes that the communication ports that have been acted upon by the 'Stop start broadcast'
PGN are remaining in the modified state.";
CM_ SG_ 2564751360 J1939Network3 "Identifies the action to be performed on the SAE J1939 Network #3.";
CM_ SG_ 2564751360 J1939Network2 "Identifies the action to be performed on the SAE J1939 Network #2.";
CM_ SG_ 2564751360 ISO9141 "Identifies the action to be performed on the ISO9141 communications port.";
CM_ SG_ 2564751360 SAE_J1850 "Identifies the action to be performed on the SAE J1850 communications port.";
CM_ SG_ 2564751360 ManufacturerSpecificPort "Identifies the action to be performed on 'Other, manufacturer specific port' communications port.";
CM_ SG_ 2564751360 CurrentDataLink "Identifies the action to be performed on the communications port that this parameter was received.";
CM_ SG_ 2564751360 SAE_J1587 "Identifies the action to be performed on the SAE J1587 communications port.";
CM_ SG_ 2564751360 SAE_J1922 "Identifies the action to be performed on the SAE J1922 communications port.";
CM_ SG_ 2564751360 J1939Network1 "Identifies the action to be performed on the SAE J1939 Network #1, Primary vehicle communications port.";
CM_ SG_ 2566748416 Aft1TripActiveRegenManRequests "Total number of Aftertreatment device 1 active regeneration manual requests by the operator during the current trip period.";
CM_ SG_ 2566748416 Aftertreatment1TripRegenTime "Total amount of fuel used by aftertreatment device 1 during the current trip period.";
CM_ SG_ 2566748416 Aftertreatment1TripFuelUsed "Total amount of fuel used by aftertreatment device 1 during the current trip period.";
CM_ SG_ 2566748928 Aftrtmnt1DslPrtFltrStLdRegThrs "the value that will first cause DPF regeneration in aftertreatment 1";
CM_ SG_ 2566748928 AftrTrtmnt1TimeSinceLstActRegen "Newly added the message in the ver1";
CM_ SG_ 2566748928 PartTr1SootLdPct "corrected the db  version1 spn 3720";
CM_ SG_ 2566748928 PartTr1AshLdPct "corrected the db  version1 spn 3719";
CM_ SG_ 2566749184 PartTrActRegenStatus "corrected the db  version1 spn 3700";
CM_ SG_ 2566749184 ParticulateTrapStatus "corrected the db  version1 spn 3701";
CM_ SG_ 2566749184 ParticulateTrapLampCommand "corrected the db  version1 from 0* to  spn 3697";
CM_ SG_ 2566749184 ExhSysHiTempLampCommand "corrected the db  version1 from 0* to  spn 3698";
CM_ SG_ 2566749184 PartTrActRegInhibitedStatus "corrected the db  version1 from 0* to  spn 3702";
CM_ SG_ 2566749184 PartTrActRegInhibDuToVehSpdAbvLm "corrected the db  version1 from 0* to  spn 3709";
CM_ SG_ 2566749184 PartTrActRegInhibDuToSysFaultAct "corrected the db  version1 from 0* to  spn 3712";
CM_ SG_ 2566749184 PartTrActRegInhibDuToServBrakAct "corrected the db  version1 from 0* to  spn 3705";
CM_ SG_ 2566749184 PartTrActRegInhibDuToPTOActive "corrected the db  version1 from 0* to  spn 3706";
CM_ SG_ 2566749184 PartTrActRegInhibDuToPrkBrakNoSt "corrected the db  version1 from 0* to  spn 3710";
CM_ SG_ 2566749184 PartTrActRegInhibDuToPedalOffIdl "corrected the db  version1 from 0* to  spn 3707";
CM_ SG_ 2566749184 PartTrActRegInhibDuToOutOfNuetrl "corrected the db  version1 from 0* to  spn 3708";
CM_ SG_ 2566749184 PartTrActRegInhibDuToLowExhTemp "corrected the db  version1 from 0* to  spn 3711";
CM_ SG_ 2566749184 PartTrActRegInhibDuToInhibSwitch "corrected the db  version1 spn 3703";
CM_ SG_ 2566749184 PartTrActRegInhibDuToClutchDisen "corrected the db  version1 spn 3704";
CM_ BO_ 2565406464 "Acknowledgment Message";
CM_ SG_ 2565406464 ParameterGroupNumber "PGN which is requested by Request2 message";
CM_ SG_ 2565406464 GroupFunctionValue "Indicates the acknowledgement response.Indicates the acknowledgement response.Negative Acknowledgement Group Function valuePositive Acknowledgement Group Function value";
CM_ SG_ 2365532672 AftertreatmentFuelTempSensVolts "Aftertreatment Fuel Temperature Sensor Voltage

15-Aug-2008: SPN needs to be defined
AftertreatmentFuelTempSensVolts	0	FF2A	520199

";
CM_ SG_ 2365532672 AftertreatmentFuelPresSens2Volts "Aftertreatment Fuel Pressure 2 Sensor Voltage

15-Aug-2008: SPN needs to be defined
AftertreatmentFuelPresSens2Volts	0	FF2A	520198
";
CM_ SG_ 2365532672 DPFOutTempVoltage "corrected the spn from 0 to spn 8404 in ver1 db
DPFOutTempVoltage	8404	FF2A	520195
";
CM_ SG_ 2365532672 DPFDeltaPressureVoltage "corrected the spn from 0 to spn 8406  in ver1 db
DPFDeltaPressureVoltage	8406	FF2A	520197
";
CM_ SG_ 2365532672 DoserFuelPressureVoltage "corrected the spn from 0 to spn 8405 in ver1 db
DoserFuelPressureVoltage	8405	FF2A	520196
";
CM_ SG_ 2365532672 DOCOutTempVoltage "corrected the spn from 0 to spn 8403 in ver1 db
DOCOutTempVoltage	8403	FF2A	520194
";
CM_ SG_ 2365532672 DOCInTempVoltage "corrected the spn from 0 to 8402 in db version 1
DOCInTempVoltage	8402	FF2A	520193
";
CM_ BO_ 2566842624 "Fuel Consumption (Liquid)";
CM_ SG_ 2566842624 EngTotalFuelUsed "Accumulated amount of fuel used during vehicle operation.";
CM_ SG_ 2566842624 EngTripFuel "Fuel consumed during all or part of a journey.";
CM_ BO_ 2566846208 "Vehicle Electrical Power #1";
CM_ SG_ 2566846208 BatteryPotentialSwitched "Electrical potential measured at the input of the electronic control unit supplied through a switching device.";
CM_ SG_ 2566846208 ElectricalPotential "Measured electrical potential of the battery.";
CM_ SG_ 2566846208 ChargingSystemPotential "Electrical potential measured at the charging system output.";
CM_ SG_ 2566846208 AltCurrent "Measure of electrical current flow from the alternator.";
CM_ SG_ 2566846208 NetBatteryCurrent "Net flow of electrical current into/out of the battery or batteries.";
CM_ BO_ 2566844928 "Fuel Economy (Liquid)";
CM_ SG_ 2566844928 EngAverageFuelEconomy "Average of instantaneous fuel economy for that segment of vehicle operation of interest.";
CM_ SG_ 2566844928 EngInstantaneousFuelEconomy "Current fuel economy at current vehicle velocity.";
CM_ SG_ 2566844928 EngFuelRate "Amount of fuel consumed by engine per unit of time.";
CM_ SG_ 2566844928 EngThrottlePos "The position of the valve used to regulate the supply of a fluid, usually air or fuel/air mixture, to an engine.";
CM_ BO_ 2566834688 "Active diagnostic trouble codes";
CM_ SG_ 2566834688 SPN5 "SPN #5 (Conversion Version 4)";
CM_ SG_ 2566834688 SPN4 "SPN #4 (Conversion Version 4)";
CM_ SG_ 2566834688 SPN3 "SPN #3 (Conversion Version 4)";
CM_ SG_ 2566834688 SPN2 "SPN #2 (Conversion Version 4)";
CM_ SG_ 2566834688 FailureModeIdentifier5 "The FMI defines the type of failure detected in the subsystem identified by an SPN.";
CM_ SG_ 2566834688 FailureModeIdentifier4 "The FMI defines the type of failure detected in the subsystem identified by an SPN.";
CM_ SG_ 2566834688 FailureModeIdentifier3 "The FMI defines the type of failure detected in the subsystem identified by an SPN.";
CM_ SG_ 2566834688 FlashRedStopLamp "This parameter provides the capability to flash the RSL (SPN 3039).";
CM_ SG_ 2566834688 FlashProtectLamp "This parameter provides the capability to flash the engine protect lamp (SPN 3041).";
CM_ SG_ 2566834688 FlashMalfuncIndicatorLamp "This parameter provides the capability to flash the MIL (SPN 3038).";
CM_ SG_ 2566834688 FlashAmberWarningLamp "This parameter provides the capability to flash the AWL (SPN 3040). ";
CM_ SG_ 2566834688 MalfunctionIndicatorLampStatus "A lamp used to relay only emissions-related trouble code information.";
CM_ SG_ 2566834688 AmberWarningLampStatus "This lamp is used to relay trouble code information that is reporting a problem with the vehicle system but the vehicle need
not be immediately stopped.";
CM_ SG_ 2566834688 OccurenceCount1 "The 7 bit occurence count field contains the number of times a fault has gone from active to previously active.";
CM_ SG_ 2566834688 FailureModeIdentifier1 "The FMI defines the type of failure detected in the subsystem identified by an SPN.";
CM_ SG_ 2566834688 SPN1 "SPN #1 (Conversion Version 4)";
CM_ SG_ 2566834688 RedStopLampStatus "This lamp is uesed to relay trouble code information that is of a severe enought condition that it warrants stopping the vehicle.";
CM_ SG_ 2566834688 ProtectLampStatus "This lamp is used to relay trouble code informatio that is reporting a problem with a vehicle system that is most
probably not electronic subsystem related.";
CM_ SG_ 2566834688 FailureModeIdentifier2 "The FMI defines the type of failure detected in the subsystem identified by an SPN.";
CM_ SG_ 2566834688 OccurenceCount5 "The 7 bit occurence count field contains the number of times a fault has gone from active to previously active.";
CM_ SG_ 2566834688 OccurenceCount4 "The 7 bit occurence count field contains the number of times a fault has gone from active to previously active.";
CM_ SG_ 2566834688 OccurenceCount3 "The 7 bit occurence count field contains the number of times a fault has gone from active to previously active.";
CM_ SG_ 2566834688 OccurenceCount2 "The 7 bit occurence count field contains the number of times a fault has gone from active to previously active.";
CM_ SG_ 2566834688 SPN5High "SPN #5 (Conversion Version 4)";
CM_ SG_ 2566834688 SPN4High "SPN #4 (Conversion Version 4)";
CM_ SG_ 2566834688 SPN3High "SPN #3 (Conversion Version 4)";
CM_ SG_ 2566834688 SPN2High "SPN #2 (Conversion Version 4)";
CM_ SG_ 2566834688 SPN1High "SPN #1 (Conversion Version 4)";
CM_ BO_ 2565865739 "Electronic Brake Controller 1";
CM_ SG_ 2565865739 TrailerABSWarningSignal "This parameter commands the tractor-mounted trailer ABS optical warning signal.";
CM_ SG_ 2565865739 TrailerABSStatus "State signal which indicates that ABS in the trailer is actively controlling the brakes.";
CM_ SG_ 2565865739 ASRBrakeControlActive "State signal which indicates that ASR brake control is active. Active means that ASR actually controls wheel brake pressure at one or more wheels of the driven
axle(s).";
CM_ SG_ 2565865739 ABS_EBSAmberWarningSignal "This parameter commands the ABS/EBS amber/yellow optical warning signal.";
CM_ SG_ 2565865739 EngAuxEngShutdownSwitch "Switch signal which requests that all engine fueling stop.";
CM_ SG_ 2565865739 EngDerateSwitch "Switch signal used to activate the torque limiting feature of the engine.";
CM_ SG_ 2565865739 AccelInterlockSwitch "Switch signal used to disable the accelerator and remote accelerator inputs, causing the engine to return to idle.";
CM_ SG_ 2565865739 TractionCtrlOverrideSwitch "Switch signal which indicates the position of the traction control override switch.";
CM_ SG_ 2565865739 AntiLockBrakingActive "State signal which indicates that the ABS is active.";
CM_ BO_ 2565668608 "Transport Protocol - Connection Management";
CM_ SG_ 2565668608 TotalNumberOfPacketsEoMA "Total number of packets for BAM message.Total number of packets received for RTS/CTS message.Total number of packets for RTS/CTS message.";
CM_ SG_ 2565668608 TotalMessageSizeEoMA "Total message size (in bytes) for BAM message.Total message size (in bytes) for RTS/CTS message.Total message size (in bytes) for RTS/CTS message.";
CM_ SG_ 2565668608 TotalMessageSizeBAM "Total message size (in bytes) for BAM message.Total message size (in bytes) for RTS/CTS message.Total message size (in bytes) for RTS/CTS message.";
CM_ SG_ 2565668608 TotalNumberOfPacketsBAM "Total number of packets for BAM message.Total number of packets received for RTS/CTS message.Total number of packets for RTS/CTS message.";
CM_ SG_ 2565668608 ConnectionAbortReason "Reason for connection abort message.";
CM_ SG_ 2565668608 NextPacketNumberToBeSent "Next Packet Number to be sent (TP.CM_CTS)";
CM_ SG_ 2565668608 NumberOfPacketsThatCanBeSent "Number of Packets that can be sent (TP.CM_CTS)";
CM_ SG_ 2565668608 MaximumNumberOfPackets "Maximum number of packets for RTS/CTS message.";
CM_ SG_ 2565668608 TotalNumberOfPackets "Total number of packets for BAM message.Total number of packets received for RTS/CTS message.Total number of packets for RTS/CTS message.";
CM_ SG_ 2565668608 TotalMessageSize "Total message size (in bytes) for BAM message.Total message size (in bytes) for RTS/CTS message.Total message size (in bytes) for RTS/CTS message.";
CM_ BO_ 2565472279 "Request";
CM_ SG_ 2565472279 ParameterGroupNumber "PGN which is requested by RQST
changed the spn from 2547 to 2540 in db vers2
";
CM_ BO_ 2566839296 "Idle Operation";
CM_ SG_ 2566839296 EngTotalIdleHours "Accumulated time of operation of the engine while under idle conditions.";
CM_ SG_ 2566839296 EngTotalIdleFuelUsed "Accumulated amount of fuel used during vehicle operation while under idle conditions.";
CM_ BO_ 2566845952 "Inlet/Exhaust Conditions 1";
CM_ SG_ 2566845952 EngExhaustGasTemp "Temperature of combustion byproducts leaving the engine.";
CM_ SG_ 2566845952 EngIntakeManifold1Temp "Temperature of pre-combustion air found in intake manifold of engine air supply system.";
CM_ SG_ 2566845952 EngTurboBoostPress "Gage pressure of air measured downstream on the compressor discharge side of the turbocharger.";
CM_ SG_ 2566845952 EngParticulateTrapInletPress "Exhaust back pressure as a result of particle accumulation on filter media placed in the exhaust stream.";
CM_ BO_ 2565867774 "Hydraulic Pressure Governor Info";
CM_ BO_ 2566759457 "PTO Drive Engagement";
CM_ SG_ 2566759457 EnggmntSttusTransInputShaftPTO1 "Reports if this specific PTO drive is engaged.";
CM_ SG_ 2566759457 EnggmntSttusTransOutputShaftPTO "Reports if this specific PTO drive is engaged.";
CM_ SG_ 2566759457 EnggmntSttsTrnsfrCsOtptShaftPTO "Reports if this specific PTO drive is engaged.";
CM_ BO_ 2566758656 "After Treatment Fuel Control #1";
CM_ SG_ 2566758656 Aftertreatment1FuelDrainAct "Added newly to the db ver1";
CM_ SG_ 2566758656 Aftertreatment1FuelPressCtrl "Position that the controller is commanding the aftertreatment #1 fuel pressure control to maintain.";
CM_ SG_ 2566758656 Aftertreatment1FuelPress "Pressure of the fuel for Aftertreatment #1.";
CM_ BO_ 2566756352 "After Treatment Historical Information #1
corrected the consistency/overlapping of the signals in the db version5";
CM_ SG_ 2566756352 Aftertreatment1AvgTimeBetRegn "Average time between active regenerations";
CM_ SG_ 2566756352 AftrTrtmnt1TtlActvRgnInhRqsts "Newly added the message in the ver1
Aftertreatment ` total number of Active rengeneration Inhibit Requests.";
CM_ SG_ 2566756352 AftrTrtmnt1TtlActvRgnMnlRqsts "Newly added the message in the ver1";
CM_ SG_ 2566756352 Aftertreatment1TotalNumActRegens "Total number of active regenerations by after treatment device 1 over the lifetime of the device.
";
CM_ SG_ 2566756352 Aftertreatment1TotalRegenTime "Total amount of time that after treatment device 1 has been regenerating over the lifetime of the device.";
CM_ SG_ 2566756352 Aftertreatment1TotalDisabledTime "Total amount of time that after treatment 1 regeneration has been manually disabled.";
CM_ SG_ 2566756352 Aftertreatment1TotalFuelUsed "Total amount of fuel used by after treatment device 1 over the lifetime of the device.";
CM_ BO_ 2431654400 "Engine Throttle / Fuel Actuator Control Command";
CM_ SG_ 2431654400 EngFuelActuator1CtrlCmd "Engine Fuel Actuator 1 Control Command

Note: On I783, this should be mapped to the MEU output.

";
CM_ SG_ 2431654400 EngFuelActuator2CtrlCmd "Engine Fuel Actuator 2 Control Command

Note: On I783, this should be mapped to the PCV output.
";
CM_ BO_ 2566764544 "Diagnostic readiness 3";
CM_ SG_ 2566764544 PMFilterMonComplete "Newly added bit to the spn 3305
";
CM_ SG_ 2566764544 NOxCnvrtctlystMonComplete "Newly added bit to the spn 3305
";
CM_ SG_ 2566764544 NHMCCnvrtctlystMonComplete "Newly added bit to the spn 3305
";
CM_ SG_ 2566764544 BstPressCtrlSystemMoncomplete "Newly added bit to the spn 3305
";
CM_ SG_ 2566764544 NHMCCnvrtctlystMonEnabled "Newly added bit to the spn 3304 
";
CM_ SG_ 2566764544 NOxCnvrtctlystMonEnabled "Newly added bit to the spn 3304 
";
CM_ SG_ 2566764544 PMFilterMonEnabled "Newly added bit to the spn 3304 
";
CM_ SG_ 2566764544 BstPressCtrlSystemMonEnabled "Newly added bit to the spn 3304 
";
CM_ SG_ 2566764544 MisfireMonitoringComplete "corrected the spn from 3152 to 3303";
CM_ SG_ 2566764544 MisfireMonitoringEnabled "corrected the spn from 3152 to 3303";
CM_ SG_ 2566764544 FuelSystemMonitoringEnabled "corrected the spn from 3152 to 3303";
CM_ SG_ 2566764544 ComprehensiveComptMonComplete "corrected the spn from 3152 to 3303";
CM_ SG_ 2566764544 ComprehensiveCompMonEnabled "corrected the spn from 3152 to 3303";
CM_ SG_ 2566764544 SecondAirSystemMonComplete "corrected the spn from 3154 to 3305";
CM_ SG_ 2566764544 SecondAirSystemMonEnabled "corrected the spn from 3153 to 3304";
CM_ SG_ 2566764544 OxygenSensorMonComplete "corrected the spn from 3154 to 3305";
CM_ SG_ 2566764544 OxygenSensorMonEnabled "corrected the spn from 3154 to 3304";
CM_ SG_ 2566764544 OxygenSensorHeaterMonComplete "corrected the spn from 3154 to 3305";
CM_ SG_ 2566764544 OxygenSensorHeaterMonEnabled "corrected the spn from 3154 to 3304";
CM_ SG_ 2566764544 HeatedCatalystMonComplete "corrected the spn from 3154 to 3305";
CM_ SG_ 2566764544 HeatedCatalystMonEnabled "corrected the spn from 3153 to 3304";
CM_ SG_ 2566764544 EvaporativeSystemMonComplete "corrected the spn from 3154 to 3305";
CM_ SG_ 2566764544 EvaporativeSystemMonEnabled "corrected the spn from 3153 to 3304";
CM_ SG_ 2566764544 EGRSystemMonitoringComplete "corrected the spn from 3154 to 3305";
CM_ SG_ 2566764544 EGRSystemMonitoringEnabled "corrected the spn from 3154 to 3304";
CM_ SG_ 2566764544 ColdStartAidSystemMonComplete "corrected the spn from 3154 to 3305";
CM_ SG_ 2566764544 ColdStartAidSystemMonEnabled "corrected the spn from 3153 to 3304";
CM_ SG_ 2566764544 CatalystMonComplete "corrected the spn from 3154 to 3305";
CM_ SG_ 2566764544 CatalystMonEnabled "corrected the spn from 3153 to 3304";
CM_ SG_ 2566764544 ACSystemRefrigerantMonComplete "corrected the spn from 3154 to 3305";
CM_ SG_ 2566764544 ACSystemRefrigerantMonEnabled "corrected the spn from 3154 to 3304";
CM_ SG_ 2566764544 FuelSystemMonitoringComplete "corrected the spn from 3152 to 3303";
CM_ SG_ 2566764544 NumOfWarmUpsSinceDTCsCleared "corrected the SPN from 3151 to 3302";
CM_ SG_ 2566764544 TimeSinceEngineStart "corrected the spn from 3150 to 3301 version1 database 
";
CM_ BO_ 2566843392 "Vehicle Identification";
CM_ SG_ 2566843392 VI_Delimiter "This represents the field delimiter * in the VI message.";
CM_ SG_ 2566843392 VIN_B17 "VIN is 17 bytes long.  This represents the last byte.";
CM_ SG_ 2566843392 VIN_B09_B016 "VIN is 17 bytes long.  This represents the middle 8 bytes.";
CM_ SG_ 2566843392 VIN_B01_B08 "VIN is 17 bytes long.  This represents the first 8 bytes.";
CM_ BO_ 2566842112 "Vehicle Hours";
CM_ SG_ 2566842112 TotalPowerTakeoffHours "Accumulated time of operation of power takeoff device.";
CM_ SG_ 2566842112 TotalVehicleHours "Accumulated time of operation of vehicle.";
CM_ BO_ 2566832384 "High Resolution Vehicle Distance";
CM_ SG_ 2566832384 HighResolutionTripDistance "Distance traveled during all or part of a journey.";
CM_ SG_ 2566832384 HghRslutionTotalVehicleDistance "Accumulated distance traveled by the vehicle during its operation.";
CM_ BO_ 2348810243 "Torque/Speed Control 1";
CM_ SG_ 2348810243 EngRqedTorque_TorqueLimit "Parameter provided to the engine or retarder in the torque/speed control message for controlling or limiting the output torque.";
CM_ SG_ 2348810243 EngRqedSpeed_SpeedLimit "Parameter provided to the engine from external sources in the torque/speed control message.";
CM_ BO_ 2633939712 "Trip Fan Information";
CM_ SG_ 2633939712 TripFanOnTime "Total time the fan has been on (due to an automatic trigger or manual trigger) since the last trip reset.";
CM_ BO_ 2566821376 "Turbocharger Wastegate";
CM_ SG_ 2566821376 EngTurbo2WastegateDrive "Position of the wastegate drive.";
CM_ SG_ 2566821376 EngTurbo1WastegateDrive "Position of the wastegate drive.";
CM_ BO_ 2566822400 "Turbocharger Information 2";
CM_ SG_ 2566822400 EngTurbo2CompressorInletTemp "Temperature of the air entering the compressor side of the turbocharger.";
CM_ BO_ 2566802179 "Transmission Configuration 2";
CM_ BO_ 2566838784 "Software Identification";
CM_ SG_ 2566838784 NmbrOfSftwrIdentificationFields "Number of software identification designators represented in the software identification parameter group.";
CM_ BO_ 2566841344 "Shutdown";
CM_ SG_ 2566841344 EngProtectionSystemConfig "Parameter which indicates the configuration of the engine shutdown system.";
CM_ SG_ 2566841344 EngProtectionSystemTimerState "Status signal which indicates the current mode of the engine protection system timer system.";
CM_ SG_ 2566841344 EngPrtectionSystemTimerOverride "Status signal which indicates the status of the override feature of the engine protection system timer.";
CM_ SG_ 2566841344 EngPrtctnSystmApprchingShutdown "Status signal which indicates that engine shutdown is imminent.";
CM_ SG_ 2566841344 EngPrtctionSystemHasShutdownEng "Status signal which indicates whether or not the engine protection system has shutdown the engine.";
CM_ SG_ 2566841344 EngIdleShutdownTimerFunction "Parameter which indicates the configuration of the idle shutdown timer system.";
CM_ SG_ 2566841344 EngIdleShutdownTimerState "Status signal which indicates the current mode of operation of the idle shutdown timer system.";
CM_ SG_ 2566841344 EngIdleShutdownTimerOverride "Status signal which indicates the status of the override feature of the idle shutdown timer system.";
CM_ SG_ 2566841344 EngIdleShutdownDriverAlertMode "Status signal which indicates the status of the driver alert mode of the idle shutdown timer system.";
CM_ SG_ 2566841344 EngIdleShutdownHasShutdownEng "Status signal which identifies whether or not the engine has been shutdown by the idle shutdown timer system.";
CM_ BO_ 2631859966 "Reset";
CM_ SG_ 2631859966 TripGroup2_Proprietary "Command signal used to reset proprietary parameters associated with a trip but not defined within J1939-71.
";
CM_ SG_ 2631859966 ServiceComponentIdentification "Identification of component needing service.";
CM_ SG_ 2631859966 TripGroup1 "Command signal used to reset the PGNs and parameters as defined in Table SPN988_A.";
CM_ BO_ 2566840591 "Retarder Configuration";
CM_ SG_ 2566840591 ReferenceRetarderTorque "This parameter is the 100% reference value for all defined indicated retarder torque parameters.";
CM_ SG_ 2566840591 RetarderSpeedAtPoint4 "Retarder speed of point 4 of the engine retarder torque map.";
CM_ SG_ 2566840591 RetarderSpeedAtPoint3 "Retarder speed of point 3 of the engine retarder torque map.";
CM_ SG_ 2566840591 PercentTorqueAtMaxSpeedPoint2 "The torque limit that indicates the available retarder torque which can be provided by the retarder at its maximum speed.";
CM_ SG_ 2566840591 MaxRetarderSpeedPoint2 "Maximum speed of retarder (Please reference PGN 65249).";
CM_ SG_ 2566840591 PercentTorqueAtIdlePoint1 "The torque limit that indicates the available retarder torque which can be provided by the retarder at idle speed.";
CM_ SG_ 2566840591 RetarderType "A vehicle retarder is a supplementary device to the wheel brakes for the driver to better control the vehicle.";
CM_ BO_ 2566844449 "Power Takeoff Information";
CM_ SG_ 2566844449 PowerTakeoffSetSpeed "Rotational Velocity selected by operator for device used to transmit engine power to auxillary equipment.
Newly added to the db version1";
CM_ SG_ 2566844449 EngPTOAccelerateSwitch "Switch signal of the PTO control activator which indicates that the activator is in the position \"accelerate\".";
CM_ SG_ 2566844449 EngPTOResumeSwitch "Switch signal of the PTO control activator which indicates that the activator is in the position \"resume\".";
CM_ SG_ 2566844449 EngPTOCoast_DecelerateSwitch "Switch signal of the PTO control activator which indicates that the activator is in the position \"coast/decelerate\".";
CM_ SG_ 2566844449 EngPTOSetSwitch "Switch signal of the PTO control activator which indicates that the activator is in the position \"set\".";
CM_ SG_ 2566844449 EngRmtPTOVriableSpeedCtrlSwitch "Switch signal which indicates that the remote PTO toggle switch is in the enabled (ON) position.";
CM_ SG_ 2566844449 EngRmtPTOPrprgrmmdSpdCtrlSwitch "Switch signal which indicates that the remote PTO toggle switch is in the enabled (ON) position.";
CM_ SG_ 2566844449 RmtPTOPrprgrmmdSpeedCtrlSwitch2 "Switch signal which indicates that the remote PTO toggle switch #2 is in the enabled (ON) position.";
CM_ BO_ 2633937664 "Fuel Information (Liquid)";
CM_ SG_ 2633937664 TripAverageFuelRate "Average fuel rate, equal to trip fuel divided by trip time while the engine speed is above zero, since the last trip reset.";
CM_ SG_ 2633937664 TotalEngPTOFuelUsed "Total fuel used while the PTO or remote PTO is in the hold state and engine speed is above zero, over the life of the engine.";
CM_ BO_ 2566831360 "Fan Drive

removed the desired fan speed out of the pgn and moved it to ADV
reason: Prop spn being clubbed along the standard pgn/spn's";
CM_ SG_ 2566831360 FanSpeed "The speed of the fan associated with engine coolant system.";
CM_ SG_ 2566831360 FanDriveState "This parameter is used to indicate the current state or mode of operation by the fan drive.";
CM_ BO_ 2565866755 "Electronic Transmission Controller 2";
CM_ SG_ 2565866755 TransCurrentRange "Range currently being commanded by the transmission control system.";
CM_ SG_ 2565866755 TransRqedRange "Range selected by the operator.";
CM_ BO_ 2364539395 "Electronic Transmission Controller 1";
CM_ SG_ 2364539395 SA_CtrlDev_TransCtrl "This parameter identfies the compoent system that will be tested.
Added to the ver1 db";
CM_ SG_ 2364539395 TransInputShaftSpeed "Rotational velocity of the primary shaft transferring power into the transmission. When a torque converter is present, it is the output of the torque converter.";
CM_ SG_ 2364539395 TransOutputShaftSpeed "Calculated speed of the transmission output shaft.";
CM_ SG_ 2364539395 TransShiftInProcess "Indicates that the transmission is in process of shifting from the current gear to the selected gear.";
CM_ SG_ 2364539395 TorqueConverterLockupEngaged "State signal which indicates whether the torque converter lockup is engaged.";
CM_ BO_ 2566809856 "Engine Temperature 3";
CM_ SG_ 2566809856 EngChargeAirCoolerOutletTemp "Temperature of combustion air after it exits from the Charge Air Cooler but before any mixing of Recirculated Exhaust Gas.";
CM_ SG_ 2566809856 EngIntakeManifold1AirTemp "Temperature of pre-combustion air found in intake manifold of engine air supply system.";
CM_ BO_ 2566824960 "Engine Temperature 2";
CM_ SG_ 2566824960 EngOilTemp2 "Temperature of the engine lubricant.";
CM_ BO_ 2566843904 "Engine Temperature 1";
CM_ SG_ 2566843904 EngIntercoolerThermostatOpening "The current position of the thermostat used to regulate the temperature of the engine intercooler.";
CM_ SG_ 2566843904 EngIntercoolerTemp "Temperature of liquid found in the intercooler located after the turbocharger.";
CM_ SG_ 2566843904 EngTurboOilTemp "Temperature of the turbocharger lubricant.";
CM_ SG_ 2566843904 EngOilTemp1 "Temperature of the engine lubricant.";
CM_ SG_ 2566843904 EngFuelTemp "Temperature of fuel entering injectors.";
CM_ SG_ 2566843904 EngCoolantTemp "Temperature of liquid found in engine cooling system.";
CM_ BO_ 2565865487 "Electronic Retarder Controller 1";
CM_ SG_ 2565865487 RetarderTorqueMode "State signal which indicates which retarder torque mode is currently generating,limiting or controlling the torque.
New message added the db ver1";
CM_ SG_ 2565865487 RetarderEnableShiftAssistSwitch "Newly added to the db ver1
";
CM_ SG_ 2565865487 RetarderEnableBrakeAssistSwitch "00 Retarder Brake Assist Disabled
01 Retarder Brake Assist Enabled
10 Error
11 Not Available.";
CM_ SG_ 2565865487 ActualRetarderPercentTorque "Actual braking torque of the retarder as a percent of retarder configuration reference torque SPN 556.";
CM_ BO_ 2633937152 "ECU History";
CM_ SG_ 2633937152 TotalECURunTime "Total time accumulated over the life of the ECU, from ignition switch ON to ignition switch OFF.";
CM_ SG_ 2633937152 TotalECUDistance "Total distance accumulated over the life of the ECU.";
CM_ BO_ 2364541440 "Engine Gas Flow Rate
changed the sa to 0 in the db version1";
CM_ SG_ 2364541440 EngInletAirMassFlowRate "Mass flow rate of fresh air entering the engine air intake, before any EGR mixer, if used.";
CM_ SG_ 2364541440 EngExhstGsRcrcltionMassFlowRate "Flow rate of gas through the EGR system.";
CM_ BO_ 2566839040 "Engine Fluid Level/Pressure 2";
CM_ SG_ 2566839040 EngInjectorMeteringRail1Press "The gage pressure of fuel in the primary, or first, metering rail as delivered from the supply pump to the injector metering inlet.";
CM_ BO_ 2566844160 "Engine Fluid Level/Pressure 1";
CM_ SG_ 2566844160 EngCrankcasePress "Gage pressure inside engine crankcase.";
CM_ SG_ 2566844160 EngOilLevel "Ratio of current volume of engine sump oil to maximum required volume.";
CM_ SG_ 2566844160 EngCoolantLevel "Ratio of volume of liquid found in engine cooling system to total cooling system volume.";
CM_ SG_ 2566844160 EngOilPress "Gage pressure of oil in engine lubrication system as provided by oil pump.";
CM_ SG_ 2566844160 EngExCrankcaseBlowbyPress "Differential crankcase blow-by pressure as measured through a tube with a venturi.";
CM_ SG_ 2566844160 EngFuelDeliveryPress "Gage pressure of fuel in system as delivered from supply pump to the injection pump.";
CM_ BO_ 2566771968 "Electronic Engine Controller 5";
CM_ SG_ 2566771968 EngFuelControlStatus "Indicates whether the Engine Fuel Control System is in open loop or closed loop.";
CM_ SG_ 2566771968 EngExhstGsRcirculationValveCtrl "Desired percentage of maximum Exhaust Gas Recirculation (EGR) valve opening.";
CM_ BO_ 2566840064 "Electronic Engine Controller 3";
CM_ SG_ 2566840064 ExhaustGasMass "Measured/calculated exhaust gas mass upstream of the after-treatment system.";
CM_ SG_ 2566840064 EngsDesiredOperatingSpeed "An indication by the engine of the optimal operating speed of the engine for the current existing conditions.";
CM_ BO_ 2364539648 "Electronic Engine Controller 2";
CM_ SG_ 2364539648 AccelPedalPos2 "ratio of actual pos to max pos of the i/p device
Newly added version1 db
";
CM_ SG_ 2364539648 RoadSpeedLimitStatus "Status (active or not active) of the system used to limit maximum vehicle velocity.";
CM_ SG_ 2364539648 AccelPedal1LowIdleSwitch "Switch signal which indicates the state of the accelerator pedal 1 low idle switch.";
CM_ BO_ 2364539904 "Electronic Engine Controller 1";
CM_ SG_ 2364539904 SA_CtrlDev_EngCtrl "Source Address of Controlling Device for Engine Control";
CM_ SG_ 2364539904 EngStarterMode "There are several phases in a starting action and different reasons why a start cannot take place.";
CM_ SG_ 2364539904 EngSpeed "Actual engine speed which is calculated over a minimum crankshaft angle of 720 degrees divided by the number of cylinders.";
CM_ SG_ 2364539904 ActualEngPercentTorque "The calculated output torque of the engine.";
CM_ SG_ 2364539904 DriversDemandEngPercentTorque "The requested torque output of the engine by the driver.";
CM_ SG_ 2364539904 EngTorqueMode "State signal which indicates which engine torque mode is currently generating, limiting, or controlling the torque.";
BA_DEF_ SG_  "Status" STRING ;
BA_DEF_ SG_  "Variable" STRING ;
BA_DEF_ SG_  "SigType" STRING ;
BA_DEF_ SG_  "SPN" INT 0 524287;
BA_DEF_ SG_  "DDI" INT 0 65535;
BA_DEF_ SG_  "SAEDocument" STRING ;
BA_DEF_ BO_  "GenMsgRequestable" INT 0 1;
BA_DEF_ BO_  "GenMsgSendType" ENUM  "cyclic","reserved","cyclicIfActive","reserved","reserved","reserved","reserved","On Request","noMsgSendType";
BA_DEF_ BO_  "VFrameFormat" ENUM  "StandardCAN","ExtendedCAN","reserved","J1939PG";
BA_DEF_ BO_  "SingleFrame" INT 0 1;
BA_DEF_ BO_  "GenMsgCycleTime" INT 0 3600000;
BA_DEF_ BO_  "SAE_Document" STRING ;
BA_DEF_DEF_  "Status" "";
BA_DEF_DEF_  "Variable" "";
BA_DEF_DEF_  "SigType" "";
BA_DEF_DEF_  "SPN" 0;
BA_DEF_DEF_  "DDI" 0;
BA_DEF_DEF_  "SAEDocument" "";
BA_DEF_DEF_  "GenMsgRequestable" 1;
BA_DEF_DEF_  "GenMsgSendType" "noMsgSendType";
BA_DEF_DEF_  "VFrameFormat" "J1939PG";
BA_DEF_DEF_  "SingleFrame" 1;
BA_DEF_DEF_  "GenMsgCycleTime" 0;
BA_DEF_DEF_  "SAE_Document" "";
BA_ "GenMsgSendType" BO_ 2566832128 7;
BA_ "SAE_Document" BO_ 2564751360 "J1939-73";
BA_ "GenMsgSendType" BO_ 2566748416 7;
BA_ "GenMsgSendType" BO_ 2566748928 7;
BA_ "SAE_Document" BO_ 2565406464 "J1939-21";
BA_ "GenMsgSendType" BO_ 2365532672 7;
BA_ "SAE_Document" BO_ 2566842624 "J1939-71";
BA_ "GenMsgSendType" BO_ 2566842624 7;
BA_ "SAE_Document" BO_ 2566846208 "J1939-71";
BA_ "GenMsgCycleTime" BO_ 2566846208 1000;
BA_ "GenMsgSendType" BO_ 2566846208 0;
BA_ "SAE_Document" BO_ 2566844928 "J1939-71";
BA_ "GenMsgCycleTime" BO_ 2566844928 100;
BA_ "GenMsgSendType" BO_ 2566844928 0;
BA_ "SAE_Document" BO_ 2566834688 "J1939-73";
BA_ "SAE_Document" BO_ 2565865739 "J1939-71";
BA_ "GenMsgCycleTime" BO_ 2565865739 100;
BA_ "GenMsgSendType" BO_ 2565865739 0;
BA_ "SAE_Document" BO_ 2565668608 "J1939-21";
BA_ "SAE_Document" BO_ 2565472279 "J1939-21";
BA_ "GenMsgSendType" BO_ 2566839296 7;
BA_ "SAE_Document" BO_ 2566839296 "J1939-71";
BA_ "GenMsgSendType" BO_ 2566845952 0;
BA_ "GenMsgCycleTime" BO_ 2566845952 500;
BA_ "SAE_Document" BO_ 2566845952 "J1939-71";
BA_ "GenMsgSendType" BO_ 2565867774 0;
BA_ "GenMsgCycleTime" BO_ 2565867774 50;
BA_ "SAE_Document" BO_ 2565867774 "J1939-71";
BA_ "GenMsgSendType" BO_ 2566759457 0;
BA_ "GenMsgCycleTime" BO_ 2566759457 100;
BA_ "SAE_Document" BO_ 2566759457 "J1939-71";
BA_ "GenMsgSendType" BO_ 2566758656 0;
BA_ "GenMsgCycleTime" BO_ 2566758656 500;
BA_ "SAE_Document" BO_ 2566758656 "J1939-71";
BA_ "GenMsgSendType" BO_ 2566756352 7;
BA_ "SAE_Document" BO_ 2566756352 "J1939-71";
BA_ "GenMsgSendType" BO_ 2431654400 0;
BA_ "GenMsgCycleTime" BO_ 2431654400 50;
BA_ "SAE_Document" BO_ 2431654400 "J1939-71";
BA_ "SAE_Document" BO_ 2566764544 "J1939-73";
BA_ "GenMsgSendType" BO_ 2566843392 7;
BA_ "SAE_Document" BO_ 2566843392 "J1939-71";
BA_ "GenMsgSendType" BO_ 2566842112 7;
BA_ "SAE_Document" BO_ 2566842112 "J1939-71";
BA_ "GenMsgSendType" BO_ 2566832384 0;
BA_ "GenMsgCycleTime" BO_ 2566832384 1000;
BA_ "SAE_Document" BO_ 2566832384 "J1939-71";
BA_ "SAE_Document" BO_ 2348810243 "J1939-71";
BA_ "GenMsgSendType" BO_ 2633939712 7;
BA_ "SAE_Document" BO_ 2633939712 "J1939-71";
BA_ "GenMsgSendType" BO_ 2566821376 0;
BA_ "GenMsgCycleTime" BO_ 2566821376 100;
BA_ "SAE_Document" BO_ 2566821376 "J1939-71";
BA_ "GenMsgSendType" BO_ 2566822400 0;
BA_ "GenMsgCycleTime" BO_ 2566822400 1000;
BA_ "SAE_Document" BO_ 2566822400 "J1939-71";
BA_ "GenMsgSendType" BO_ 2566802179 0;
BA_ "SAE_Document" BO_ 2566802179 "J1939-71";
BA_ "GenMsgCycleTime" BO_ 2566802179 5000;
BA_ "GenMsgSendType" BO_ 2566838784 7;
BA_ "SAE_Document" BO_ 2566838784 "J1939-71";
BA_ "GenMsgSendType" BO_ 2566841344 0;
BA_ "GenMsgCycleTime" BO_ 2566841344 1000;
BA_ "SAE_Document" BO_ 2566841344 "J1939-71";
BA_ "SAE_Document" BO_ 2631859966 "J1939-71";
BA_ "SAE_Document" BO_ 2566840591 "J1939-71";
BA_ "GenMsgSendType" BO_ 2566844449 0;
BA_ "GenMsgCycleTime" BO_ 2566844449 100;
BA_ "SAE_Document" BO_ 2566844449 "J1939-71";
BA_ "GenMsgSendType" BO_ 2633937664 7;
BA_ "SAE_Document" BO_ 2633937664 "J1939-71";
BA_ "GenMsgSendType" BO_ 2566831360 0;
BA_ "GenMsgCycleTime" BO_ 2566831360 1000;
BA_ "SAE_Document" BO_ 2566831360 "J1939-71";
BA_ "GenMsgSendType" BO_ 2565866755 0;
BA_ "GenMsgCycleTime" BO_ 2565866755 100;
BA_ "SAE_Document" BO_ 2565866755 "J1939-71";
BA_ "GenMsgSendType" BO_ 2364539395 0;
BA_ "GenMsgCycleTime" BO_ 2364539395 10;
BA_ "SAE_Document" BO_ 2364539395 "J1939-71";
BA_ "GenMsgSendType" BO_ 2566809856 0;
BA_ "GenMsgCycleTime" BO_ 2566809856 1000;
BA_ "SAE_Document" BO_ 2566809856 "J1939-71";
BA_ "GenMsgSendType" BO_ 2566824960 0;
BA_ "GenMsgCycleTime" BO_ 2566824960 1000;
BA_ "SAE_Document" BO_ 2566824960 "J1939-71";
BA_ "GenMsgSendType" BO_ 2566843904 0;
BA_ "GenMsgCycleTime" BO_ 2566843904 1000;
BA_ "SAE_Document" BO_ 2566843904 "J1939-71";
BA_ "GenMsgSendType" BO_ 2565865487 0;
BA_ "GenMsgCycleTime" BO_ 2565865487 100;
BA_ "SAE_Document" BO_ 2565865487 "J1939-71";
BA_ "GenMsgSendType" BO_ 2633937152 7;
BA_ "SAE_Document" BO_ 2633937152 "J1939-71";
BA_ "GenMsgSendType" BO_ 2364541440 0;
BA_ "GenMsgCycleTime" BO_ 2364541440 50;
BA_ "SAE_Document" BO_ 2364541440 "J1939-71";
BA_ "GenMsgSendType" BO_ 2566839040 0;
BA_ "GenMsgCycleTime" BO_ 2566839040 500;
BA_ "SAE_Document" BO_ 2566839040 "J1939-71";
BA_ "GenMsgSendType" BO_ 2566844160 0;
BA_ "GenMsgCycleTime" BO_ 2566844160 500;
BA_ "SAE_Document" BO_ 2566844160 "J1939-71";
BA_ "GenMsgSendType" BO_ 2566771968 7;
BA_ "SAE_Document" BO_ 2566771968 "J1939-71";
BA_ "GenMsgSendType" BO_ 2566840064 0;
BA_ "GenMsgCycleTime" BO_ 2566840064 250;
BA_ "SAE_Document" BO_ 2566840064 "J1939-71";
BA_ "GenMsgSendType" BO_ 2364539648 0;
BA_ "GenMsgCycleTime" BO_ 2364539648 50;
BA_ "SAE_Document" BO_ 2364539648 "J1939-71";
BA_ "GenMsgSendType" BO_ 2364539904 0;
BA_ "GenMsgCycleTime" BO_ 2364539904 100;
BA_ "SAE_Document" BO_ 2364539904 "J1939-71";
BA_ "Status" SG_ 2566832128 SPN_0911 "3.2.0";
BA_ "SPN" SG_ 2566832128 SPN_0911 911;
BA_ "Variable" SG_ 2566832128 SPN_0911 "Com_IdSrvCmpn1_C / Com_IdSrvCmpn2_C";
BA_ "Status" SG_ 2564751360 HoldSignal "2.1.0";
BA_ "SigType" SG_ 2564751360 HoldSignal "DISCRETE";
BA_ "SPN" SG_ 2564751360 HoldSignal 1236;
BA_ "SAEDocument" SG_ 2564751360 HoldSignal "J1939-73";
BA_ "Variable" SG_ 2564751360 HoldSignal "N/A";
BA_ "Status" SG_ 2564751360 J1939Network3 "2.1.0";
BA_ "SigType" SG_ 2564751360 J1939Network3 "DISCRETE";
BA_ "SPN" SG_ 2564751360 J1939Network3 1235;
BA_ "SAEDocument" SG_ 2564751360 J1939Network3 "J1939-73";
BA_ "Variable" SG_ 2564751360 J1939Network3 "N/A";
BA_ "Status" SG_ 2564751360 J1939Network2 "2.1.0";
BA_ "SigType" SG_ 2564751360 J1939Network2 "DISCRETE";
BA_ "SPN" SG_ 2564751360 J1939Network2 1231;
BA_ "SAEDocument" SG_ 2564751360 J1939Network2 "J1939-73";
BA_ "Variable" SG_ 2564751360 J1939Network2 "N/A";
BA_ "Status" SG_ 2564751360 ISO9141 "2.1.0";
BA_ "SigType" SG_ 2564751360 ISO9141 "DISCRETE";
BA_ "SPN" SG_ 2564751360 ISO9141 1232;
BA_ "SAEDocument" SG_ 2564751360 ISO9141 "J1939-73";
BA_ "Variable" SG_ 2564751360 ISO9141 "N/A";
BA_ "Status" SG_ 2564751360 SAE_J1850 "2.1.0";
BA_ "SigType" SG_ 2564751360 SAE_J1850 "DISCRETE";
BA_ "SPN" SG_ 2564751360 SAE_J1850 1233;
BA_ "SAEDocument" SG_ 2564751360 SAE_J1850 "J1939-73";
BA_ "Variable" SG_ 2564751360 SAE_J1850 "N/A";
BA_ "Status" SG_ 2564751360 ManufacturerSpecificPort "2.1.0";
BA_ "SigType" SG_ 2564751360 ManufacturerSpecificPort "DISCRETE";
BA_ "SPN" SG_ 2564751360 ManufacturerSpecificPort 1234;
BA_ "SAEDocument" SG_ 2564751360 ManufacturerSpecificPort "J1939-73";
BA_ "Variable" SG_ 2564751360 ManufacturerSpecificPort "N/A";
BA_ "Status" SG_ 2564751360 CurrentDataLink "2.1.0";
BA_ "SigType" SG_ 2564751360 CurrentDataLink "DISCRETE";
BA_ "SPN" SG_ 2564751360 CurrentDataLink 1230;
BA_ "SAEDocument" SG_ 2564751360 CurrentDataLink "J1939-73";
BA_ "Variable" SG_ 2564751360 CurrentDataLink "N/A";
BA_ "Status" SG_ 2564751360 SAE_J1587 "2.1.0";
BA_ "SigType" SG_ 2564751360 SAE_J1587 "DISCRETE";
BA_ "SPN" SG_ 2564751360 SAE_J1587 608;
BA_ "SAEDocument" SG_ 2564751360 SAE_J1587 "J1939-73";
BA_ "Variable" SG_ 2564751360 SAE_J1587 "N/A";
BA_ "Status" SG_ 2564751360 SAE_J1922 "2.1.0";
BA_ "SigType" SG_ 2564751360 SAE_J1922 "DISCRETE";
BA_ "SPN" SG_ 2564751360 SAE_J1922 622;
BA_ "SAEDocument" SG_ 2564751360 SAE_J1922 "J1939-73";
BA_ "Variable" SG_ 2564751360 SAE_J1922 "N/A";
BA_ "Status" SG_ 2564751360 J1939Network1 "2.1.0";
BA_ "SigType" SG_ 2564751360 J1939Network1 "DISCRETE";
BA_ "SPN" SG_ 2564751360 J1939Network1 639;
BA_ "SAEDocument" SG_ 2564751360 J1939Network1 "J1939-73";
BA_ "Variable" SG_ 2564751360 J1939Network1 "N/A";
BA_ "Status" SG_ 2564751360 SuspendSignal "2.1.0";
BA_ "SPN" SG_ 2564751360 SuspendSignal 2618;
BA_ "SAEDocument" SG_ 2564751360 SuspendSignal "J1939-73";
BA_ "Variable" SG_ 2564751360 SuspendSignal "N/A";
BA_ "Status" SG_ 2564751360 SuspendDuration "2.1.0";
BA_ "SPN" SG_ 2564751360 SuspendDuration 2619;
BA_ "SAEDocument" SG_ 2564751360 SuspendDuration "J1939-73";
BA_ "Variable" SG_ 2564751360 SuspendDuration "N/A";
BA_ "SPN" SG_ 2566748416 Aft1TripActiveRegenManRequests 3740;
BA_ "Variable" SG_ 2566748416 Aftertreatment1TripActiveRegens "PFltRgn_numRgnTrp";
BA_ "Status" SG_ 2566748416 Aftertreatment1TripActiveRegens "2.2.0";
BA_ "SPN" SG_ 2566748416 Aftertreatment1TripActiveRegens 3736;
BA_ "Status" SG_ 2566748416 Aftertreatment1TripRegenTime "2.2.0";
BA_ "Variable" SG_ 2566748416 Aftertreatment1TripRegenTime "PFltRgn_tiRgnTrp";
BA_ "SigType" SG_ 2566748416 Aftertreatment1TripRegenTime "RANGE";
BA_ "SPN" SG_ 2566748416 Aftertreatment1TripRegenTime 3734;
BA_ "SAEDocument" SG_ 2566748416 Aftertreatment1TripRegenTime "J1939-71";
BA_ "Status" SG_ 2566748416 Aftertreatment1TripFuelUsed "2.5.0";
BA_ "SigType" SG_ 2566748416 Aftertreatment1TripFuelUsed "RANGE";
BA_ "SPN" SG_ 2566748416 Aftertreatment1TripFuelUsed 3733;
BA_ "SAEDocument" SG_ 2566748416 Aftertreatment1TripFuelUsed "J1939-71";
BA_ "Variable" SG_ 2566748416 Aftertreatment1TripFuelUsed "HCIPOD_qDosQntTrp";
BA_ "SAEDocument" SG_ 2566748928 Aftrtmnt1DslPrtFltrStLdRegThrs "J1939-71";
BA_ "SPN" SG_ 2566748928 Aftrtmnt1DslPrtFltrStLdRegThrs 5466;
BA_ "Status" SG_ 2566748928 Aftrtmnt1DslPrtFltrStLdRegThrs "3.10.0";
BA_ "Variable" SG_ 2566748928 Aftrtmnt1DslPrtFltrStLdRegThrs "Com_rRgnThresh";
BA_ "Variable" SG_ 2566748928 AftrTrtmnt1TimeSinceLstActRegen "PFltRgn_tiSnceRgn";
BA_ "SigType" SG_ 2566748928 AftrTrtmnt1TimeSinceLstActRegen "RANGE";
BA_ "SPN" SG_ 2566748928 AftrTrtmnt1TimeSinceLstActRegen 3721;
BA_ "SAEDocument" SG_ 2566748928 AftrTrtmnt1TimeSinceLstActRegen "J1939-71";
BA_ "Status" SG_ 2566748928 AftrTrtmnt1TimeSinceLstActRegen "2.1.0";
BA_ "Variable" SG_ 2566748928 PartTr1SootLdPct "Com_rPartTr1Sot";
BA_ "SPN" SG_ 2566748928 PartTr1SootLdPct 3719;
BA_ "Status" SG_ 2566748928 PartTr1SootLdPct "2.1.0";
BA_ "Variable" SG_ 2566748928 PartTr1AshLdPct "Com_rPartTr1Ash";
BA_ "SPN" SG_ 2566748928 PartTr1AshLdPct 3720;
BA_ "Status" SG_ 2566748928 PartTr1AshLdPct "2.1.0";
BA_ "SAEDocument" SG_ 2566749184 PartTrActRegInhDuToColdEngine "J1939-71";
BA_ "SPN" SG_ 2566749184 PartTrActRegInhDuToColdEngine 3716;
BA_ "SigType" SG_ 2566749184 PartTrActRegInhDuToColdEngine "RANGE";
BA_ "Variable" SG_ 2566749184 PartTrActRegInhDuToColdEngine "Com_stEngPOpPTC1";
BA_ "Status" SG_ 2566749184 PartTrActRegInhDuToColdEngine "2.3.0";
BA_ "SPN" SG_ 2566749184 PartTrActRegenStatus 3700;
BA_ "Variable" SG_ 2566749184 PartTrActRegenStatus "Com_stPFltRgnActvPTC1";
BA_ "Status" SG_ 2566749184 PartTrActRegenStatus "2.3.0";
BA_ "Variable" SG_ 2566749184 ParticulateTrapStatus "Com_stDPFPTC1";
BA_ "SPN" SG_ 2566749184 ParticulateTrapStatus 3701;
BA_ "Status" SG_ 2566749184 ParticulateTrapStatus "2.1.0";
BA_ "Variable" SG_ 2566749184 ParticulateTrapLampCommand "Com_stLampPTC1";
BA_ "SPN" SG_ 2566749184 ParticulateTrapLampCommand 3697;
BA_ "Status" SG_ 2566749184 ParticulateTrapLampCommand "2.1.0";
BA_ "SPN" SG_ 2566749184 ExhSysHiTempLampCommand 3698;
BA_ "Variable" SG_ 2566749184 ExhSysHiTempLampCommand "Com_stTEGHiPTC1";
BA_ "Status" SG_ 2566749184 ExhSysHiTempLampCommand "2.3.0";
BA_ "SPN" SG_ 2566749184 PartTrActRegInhibitedStatus 3702;
BA_ "Variable" SG_ 2566749184 PartTrActRegInhibitedStatus "Com_stPFltRgnInhPTC1";
BA_ "Status" SG_ 2566749184 PartTrActRegInhibitedStatus "2.3.0";
BA_ "Variable" SG_ 2566749184 PartTrActRegInhibDuToVehSpdAbvLm "Com_stVehSpdPTC1";
BA_ "SPN" SG_ 2566749184 PartTrActRegInhibDuToVehSpdAbvLm 3709;
BA_ "Status" SG_ 2566749184 PartTrActRegInhibDuToVehSpdAbvLm "2.1.0";
BA_ "Variable" SG_ 2566749184 PartTrActRegInhibDuToSysFaultAct "Com_stSysFaultPTC1";
BA_ "SPN" SG_ 2566749184 PartTrActRegInhibDuToSysFaultAct 3712;
BA_ "Status" SG_ 2566749184 PartTrActRegInhibDuToSysFaultAct "2.1.0";
BA_ "Variable" SG_ 2566749184 PartTrActRegInhibDuToServBrakAct "Com_stSrvBrkPTC1";
BA_ "SPN" SG_ 2566749184 PartTrActRegInhibDuToServBrakAct 3705;
BA_ "Status" SG_ 2566749184 PartTrActRegInhibDuToServBrakAct "2.1.0";
BA_ "Variable" SG_ 2566749184 PartTrActRegInhibDuToPTOActive "Com_stPTOActvPTC1";
BA_ "SPN" SG_ 2566749184 PartTrActRegInhibDuToPTOActive 3706;
BA_ "Status" SG_ 2566749184 PartTrActRegInhibDuToPTOActive "2.1.0";
BA_ "Variable" SG_ 2566749184 PartTrActRegInhibDuToPrkBrakNoSt "Com_stPrkBrkPTC1";
BA_ "SPN" SG_ 2566749184 PartTrActRegInhibDuToPrkBrakNoSt 3710;
BA_ "Status" SG_ 2566749184 PartTrActRegInhibDuToPrkBrakNoSt "2.1.0";
BA_ "Variable" SG_ 2566749184 PartTrActRegInhibDuToPedalOffIdl "Com_stIdlePTC1";
BA_ "SPN" SG_ 2566749184 PartTrActRegInhibDuToPedalOffIdl 3707;
BA_ "Status" SG_ 2566749184 PartTrActRegInhibDuToPedalOffIdl "2.1.0";
BA_ "Variable" SG_ 2566749184 PartTrActRegInhibDuToOutOfNuetrl "Com_stNeutralPTC1";
BA_ "SPN" SG_ 2566749184 PartTrActRegInhibDuToOutOfNuetrl 3708;
BA_ "Status" SG_ 2566749184 PartTrActRegInhibDuToOutOfNuetrl "2.1.0";
BA_ "Variable" SG_ 2566749184 PartTrActRegInhibDuToLowExhTemp "Com_stExhTempPTC1";
BA_ "SPN" SG_ 2566749184 PartTrActRegInhibDuToLowExhTemp 3711;
BA_ "Status" SG_ 2566749184 PartTrActRegInhibDuToLowExhTemp "2.1.0";
BA_ "SPN" SG_ 2566749184 PartTrActRegInhibDuToInhibSwitch 3703;
BA_ "Variable" SG_ 2566749184 PartTrActRegInhibDuToInhibSwitch "Com_stRgnStyIntrPTC1";
BA_ "Status" SG_ 2566749184 PartTrActRegInhibDuToInhibSwitch "2.3.0";
BA_ "Variable" SG_ 2566749184 PartTrActRegInhibDuToClutchDisen "Com_stClthPTC1";
BA_ "SPN" SG_ 2566749184 PartTrActRegInhibDuToClutchDisen 3704;
BA_ "Status" SG_ 2566749184 PartTrActRegInhibDuToClutchDisen "2.1.0";
BA_ "Status" SG_ 2565406464 AddressBusy "Ok";
BA_ "Variable" SG_ 2565406464 AddressBusy "N/A";
BA_ "SPN" SG_ 2565406464 AddressBusy 3293;
BA_ "SAEDocument" SG_ 2565406464 AddressBusy "J1939-21";
BA_ "Status" SG_ 2565406464 ParameterGroupNumber "Ok";
BA_ "Variable" SG_ 2565406464 ParameterGroupNumber "N/A";
BA_ "SigType" SG_ 2565406464 ParameterGroupNumber "RANGE";
BA_ "SPN" SG_ 2565406464 ParameterGroupNumber 2574;
BA_ "SAEDocument" SG_ 2565406464 ParameterGroupNumber "J1939-21";
BA_ "Status" SG_ 2565406464 GroupFunctionValue "Ok";
BA_ "Variable" SG_ 2565406464 GroupFunctionValue "N/A";
BA_ "SigType" SG_ 2565406464 GroupFunctionValue "RANGE";
BA_ "SPN" SG_ 2565406464 GroupFunctionValue 2542;
BA_ "SAEDocument" SG_ 2565406464 GroupFunctionValue "J1939-21";
BA_ "Status" SG_ 2565406464 ControlByte "Ok";
BA_ "Variable" SG_ 2565406464 ControlByte "N/A";
BA_ "SPN" SG_ 2565406464 ControlByte 2556;
BA_ "SAEDocument" SG_ 2565406464 ControlByte "J1939-21";
BA_ "Status" SG_ 2565406464 AddressAccessDenied "Ok";
BA_ "Variable" SG_ 2565406464 AddressAccessDenied "N/A";
BA_ "SPN" SG_ 2565406464 AddressAccessDenied 3292;
BA_ "SAEDocument" SG_ 2565406464 AddressAccessDenied "J1939-21";
BA_ "Status" SG_ 2565406464 AddressNegativeAcknowledgement "Ok";
BA_ "Variable" SG_ 2565406464 AddressNegativeAcknowledgement "N/A";
BA_ "SPN" SG_ 2565406464 AddressNegativeAcknowledgement 3291;
BA_ "SAEDocument" SG_ 2565406464 AddressNegativeAcknowledgement "J1939-21";
BA_ "Status" SG_ 2565406464 AddressAcknowledged "Ok";
BA_ "Variable" SG_ 2565406464 AddressAcknowledged "N/A";
BA_ "SPN" SG_ 2565406464 AddressAcknowledged 3290;
BA_ "SAEDocument" SG_ 2565406464 AddressAcknowledged "J1939-21";
BA_ "Status" SG_ 2365532672 AftertreatmentFuelTempSensVolts "2.2.0";
BA_ "Variable" SG_ 2365532672 AftertreatmentFuelTempSensVolts "DPM_uRawHDVUsT";
BA_ "SPN" SG_ 2365532672 AftertreatmentFuelTempSensVolts 520199;
BA_ "Status" SG_ 2365532672 AftertreatmentFuelPresSens2Volts "2.2.0";
BA_ "Variable" SG_ 2365532672 AftertreatmentFuelPresSens2Volts "DPM_uRawHDVDsP";
BA_ "SPN" SG_ 2365532672 AftertreatmentFuelPresSens2Volts 520198;
BA_ "Variable" SG_ 2365532672 DPFOutTempVoltage "Exh_uRawTPFltDs";
BA_ "Status" SG_ 2365532672 DPFOutTempVoltage "2.2.0";
BA_ "SPN" SG_ 2365532672 DPFOutTempVoltage 520195;
BA_ "Variable" SG_ 2365532672 DPFDeltaPressureVoltage "Exh_uRawPPFltDiff";
BA_ "Status" SG_ 2365532672 DPFDeltaPressureVoltage "2.2.0";
BA_ "SPN" SG_ 2365532672 DPFDeltaPressureVoltage 520197;
BA_ "Variable" SG_ 2365532672 DoserFuelPressureVoltage "DPM_uRawHDVUsP";
BA_ "Status" SG_ 2365532672 DoserFuelPressureVoltage "2.2.0";
BA_ "SPN" SG_ 2365532672 DoserFuelPressureVoltage 520196;
BA_ "Variable" SG_ 2365532672 DOCOutTempVoltage "Exh_uRawTOxiCatDs";
BA_ "Status" SG_ 2365532672 DOCOutTempVoltage "2.2.0";
BA_ "SPN" SG_ 2365532672 DOCOutTempVoltage 520194;
BA_ "Status" SG_ 2365532672 DOCInTempVoltage "2.2.0";
BA_ "Variable" SG_ 2365532672 DOCInTempVoltage "Exh_uRawTOxiCatUs";
BA_ "SPN" SG_ 2365532672 DOCInTempVoltage 520193;
BA_ "SigType" SG_ 2566842624 EngTotalFuelUsed "RANGE";
BA_ "SPN" SG_ 2566842624 EngTotalFuelUsed 250;
BA_ "SAEDocument" SG_ 2566842624 EngTotalFuelUsed "J1939-71";
BA_ "Variable" SG_ 2566842624 EngTotalFuelUsed "Com_volLFCTot";
BA_ "Status" SG_ 2566842624 EngTotalFuelUsed "2.3.0";
BA_ "SigType" SG_ 2566842624 EngTripFuel "RANGE";
BA_ "SPN" SG_ 2566842624 EngTripFuel 182;
BA_ "SAEDocument" SG_ 2566842624 EngTripFuel "J1939-71";
BA_ "Status" SG_ 2566842624 EngTripFuel "3.2.0";
BA_ "Variable" SG_ 2566842624 EngTripFuel "FlSys_volFlConsTot - EEPROM value";
BA_ "Variable" SG_ 2566846208 BatteryPotentialSwitched "BattU_u";
BA_ "SigType" SG_ 2566846208 BatteryPotentialSwitched "RANGE";
BA_ "SPN" SG_ 2566846208 BatteryPotentialSwitched 158;
BA_ "SAEDocument" SG_ 2566846208 BatteryPotentialSwitched "J1939-71";
BA_ "Status" SG_ 2566846208 BatteryPotentialSwitched "2.1.0";
BA_ "SigType" SG_ 2566846208 ElectricalPotential "RANGE";
BA_ "SPN" SG_ 2566846208 ElectricalPotential 168;
BA_ "SAEDocument" SG_ 2566846208 ElectricalPotential "J1939-71";
BA_ "Status" SG_ 2566846208 ElectricalPotential "Not needed";
BA_ "SigType" SG_ 2566846208 ChargingSystemPotential "RANGE";
BA_ "SPN" SG_ 2566846208 ChargingSystemPotential 167;
BA_ "SAEDocument" SG_ 2566846208 ChargingSystemPotential "J1939-71";
BA_ "Status" SG_ 2566846208 ChargingSystemPotential "Not needed";
BA_ "SigType" SG_ 2566846208 AltCurrent "RANGE";
BA_ "SPN" SG_ 2566846208 AltCurrent 115;
BA_ "SAEDocument" SG_ 2566846208 AltCurrent "J1939-71";
BA_ "Status" SG_ 2566846208 AltCurrent "Not needed";
BA_ "SigType" SG_ 2566846208 NetBatteryCurrent "RANGE";
BA_ "SPN" SG_ 2566846208 NetBatteryCurrent 114;
BA_ "SAEDocument" SG_ 2566846208 NetBatteryCurrent "J1939-71";
BA_ "Status" SG_ 2566846208 NetBatteryCurrent "Not needed";
BA_ "SigType" SG_ 2566844928 EngAverageFuelEconomy "RANGE";
BA_ "SPN" SG_ 2566844928 EngAverageFuelEconomy 185;
BA_ "SAEDocument" SG_ 2566844928 EngAverageFuelEconomy "J1939-71";
BA_ "Status" SG_ 2566844928 EngAverageFuelEconomy "Not needed";
BA_ "Variable" SG_ 2566844928 EngInstantaneousFuelEconomy "Com_InstFlEco";
BA_ "SigType" SG_ 2566844928 EngInstantaneousFuelEconomy "RANGE";
BA_ "SPN" SG_ 2566844928 EngInstantaneousFuelEconomy 184;
BA_ "SAEDocument" SG_ 2566844928 EngInstantaneousFuelEconomy "J1939-71";
BA_ "Status" SG_ 2566844928 EngInstantaneousFuelEconomy "2.1.0";
BA_ "Variable" SG_ 2566844928 EngFuelRate "Com_dvolFlCons";
BA_ "SigType" SG_ 2566844928 EngFuelRate "RANGE";
BA_ "SPN" SG_ 2566844928 EngFuelRate 183;
BA_ "SAEDocument" SG_ 2566844928 EngFuelRate "J1939-71";
BA_ "Status" SG_ 2566844928 EngFuelRate "2.1.0";
BA_ "Status" SG_ 2566844928 EngThrottlePos "2.3.0";
BA_ "SigType" SG_ 2566844928 EngThrottlePos "RANGE";
BA_ "SPN" SG_ 2566844928 EngThrottlePos 51;
BA_ "SAEDocument" SG_ 2566844928 EngThrottlePos "J1939-71";
BA_ "Variable" SG_ 2566844928 EngThrottlePos "Com_rSensThrVlv";
BA_ "Status" SG_ 2566834688 SPN5 "2.1.0";
BA_ "SAEDocument" SG_ 2566834688 SPN5 "J1939-73";
BA_ "Variable" SG_ 2566834688 SPN5 "N/A";
BA_ "SPN" SG_ 2566834688 SPN5 1214;
BA_ "Status" SG_ 2566834688 SPN4 "2.1.0";
BA_ "SAEDocument" SG_ 2566834688 SPN4 "J1939-73";
BA_ "Variable" SG_ 2566834688 SPN4 "N/A";
BA_ "SPN" SG_ 2566834688 SPN4 1214;
BA_ "Status" SG_ 2566834688 SPN3 "2.1.0";
BA_ "SAEDocument" SG_ 2566834688 SPN3 "J1939-73";
BA_ "Variable" SG_ 2566834688 SPN3 "N/A";
BA_ "SPN" SG_ 2566834688 SPN3 1214;
BA_ "Status" SG_ 2566834688 SPN2 "2.1.0";
BA_ "SAEDocument" SG_ 2566834688 SPN2 "J1939-73";
BA_ "Variable" SG_ 2566834688 SPN2 "N/A";
BA_ "SPN" SG_ 2566834688 SPN2 1214;
BA_ "Status" SG_ 2566834688 FailureModeIdentifier5 "2.1.0";
BA_ "SAEDocument" SG_ 2566834688 FailureModeIdentifier5 "J1939-73";
BA_ "Variable" SG_ 2566834688 FailureModeIdentifier5 "N/A";
BA_ "SPN" SG_ 2566834688 FailureModeIdentifier5 1215;
BA_ "Status" SG_ 2566834688 FailureModeIdentifier4 "2.1.0";
BA_ "SAEDocument" SG_ 2566834688 FailureModeIdentifier4 "J1939-73";
BA_ "Variable" SG_ 2566834688 FailureModeIdentifier4 "N/A";
BA_ "SPN" SG_ 2566834688 FailureModeIdentifier4 1215;
BA_ "Status" SG_ 2566834688 FailureModeIdentifier3 "2.1.0";
BA_ "SAEDocument" SG_ 2566834688 FailureModeIdentifier3 "J1939-73";
BA_ "Variable" SG_ 2566834688 FailureModeIdentifier3 "N/A";
BA_ "SPN" SG_ 2566834688 FailureModeIdentifier3 1215;
BA_ "Status" SG_ 2566834688 FlashRedStopLamp "2.1.0";
BA_ "SPN" SG_ 2566834688 FlashRedStopLamp 3039;
BA_ "SAEDocument" SG_ 2566834688 FlashRedStopLamp "J1939-73";
BA_ "Variable" SG_ 2566834688 FlashRedStopLamp "N/A";
BA_ "Status" SG_ 2566834688 FlashProtectLamp "2.1.0";
BA_ "SPN" SG_ 2566834688 FlashProtectLamp 3041;
BA_ "SAEDocument" SG_ 2566834688 FlashProtectLamp "J1939-73";
BA_ "Variable" SG_ 2566834688 FlashProtectLamp "N/A";
BA_ "Status" SG_ 2566834688 FlashMalfuncIndicatorLamp "2.1.0";
BA_ "SigType" SG_ 2566834688 FlashMalfuncIndicatorLamp "DISCRETE";
BA_ "SPN" SG_ 2566834688 FlashMalfuncIndicatorLamp 3038;
BA_ "SAEDocument" SG_ 2566834688 FlashMalfuncIndicatorLamp "J1939-73";
BA_ "Variable" SG_ 2566834688 FlashMalfuncIndicatorLamp "N/A";
BA_ "Status" SG_ 2566834688 FlashAmberWarningLamp "2.1.0";
BA_ "SPN" SG_ 2566834688 FlashAmberWarningLamp 3040;
BA_ "SAEDocument" SG_ 2566834688 FlashAmberWarningLamp "J1939-73";
BA_ "Variable" SG_ 2566834688 FlashAmberWarningLamp "N/A";
BA_ "Status" SG_ 2566834688 MalfunctionIndicatorLampStatus "2.1.0";
BA_ "SigType" SG_ 2566834688 MalfunctionIndicatorLampStatus "DISCRETE";
BA_ "SPN" SG_ 2566834688 MalfunctionIndicatorLampStatus 1213;
BA_ "SAEDocument" SG_ 2566834688 MalfunctionIndicatorLampStatus "J1939-73";
BA_ "Variable" SG_ 2566834688 MalfunctionIndicatorLampStatus "N/A";
BA_ "Status" SG_ 2566834688 AmberWarningLampStatus "2.1.0";
BA_ "SigType" SG_ 2566834688 AmberWarningLampStatus "DISCRETE";
BA_ "SPN" SG_ 2566834688 AmberWarningLampStatus 624;
BA_ "SAEDocument" SG_ 2566834688 AmberWarningLampStatus "J1939-73";
BA_ "Variable" SG_ 2566834688 AmberWarningLampStatus "N/A";
BA_ "Status" SG_ 2566834688 OccurenceCount1 "2.1.0";
BA_ "SigType" SG_ 2566834688 OccurenceCount1 "RANGE";
BA_ "SPN" SG_ 2566834688 OccurenceCount1 1216;
BA_ "SAEDocument" SG_ 2566834688 OccurenceCount1 "J1939-73";
BA_ "Variable" SG_ 2566834688 OccurenceCount1 "N/A";
BA_ "Status" SG_ 2566834688 SPNConversionMethod1 "2.1.0";
BA_ "SPN" SG_ 2566834688 SPNConversionMethod1 1706;
BA_ "SAEDocument" SG_ 2566834688 SPNConversionMethod1 "J1939-73";
BA_ "Variable" SG_ 2566834688 SPNConversionMethod1 "N/A";
BA_ "Status" SG_ 2566834688 FailureModeIdentifier1 "2.1.0";
BA_ "SPN" SG_ 2566834688 FailureModeIdentifier1 1215;
BA_ "SAEDocument" SG_ 2566834688 FailureModeIdentifier1 "J1939-73";
BA_ "Variable" SG_ 2566834688 FailureModeIdentifier1 "N/A";
BA_ "Status" SG_ 2566834688 SPN1 "2.1.0";
BA_ "SPN" SG_ 2566834688 SPN1 1214;
BA_ "SAEDocument" SG_ 2566834688 SPN1 "J1939-73";
BA_ "Variable" SG_ 2566834688 SPN1 "N/A";
BA_ "Status" SG_ 2566834688 RedStopLampStatus "2.1.0";
BA_ "SigType" SG_ 2566834688 RedStopLampStatus "DISCRETE";
BA_ "SPN" SG_ 2566834688 RedStopLampStatus 623;
BA_ "SAEDocument" SG_ 2566834688 RedStopLampStatus "J1939-73";
BA_ "Variable" SG_ 2566834688 RedStopLampStatus "N/A";
BA_ "Status" SG_ 2566834688 ProtectLampStatus "2.1.0";
BA_ "SigType" SG_ 2566834688 ProtectLampStatus "DISCRETE";
BA_ "SPN" SG_ 2566834688 ProtectLampStatus 987;
BA_ "SAEDocument" SG_ 2566834688 ProtectLampStatus "J1939-73";
BA_ "Variable" SG_ 2566834688 ProtectLampStatus "N/A";
BA_ "Status" SG_ 2566834688 FailureModeIdentifier2 "2.1.0";
BA_ "SAEDocument" SG_ 2566834688 FailureModeIdentifier2 "J1939-73";
BA_ "Variable" SG_ 2566834688 FailureModeIdentifier2 "N/A";
BA_ "SPN" SG_ 2566834688 FailureModeIdentifier2 1215;
BA_ "Status" SG_ 2566834688 SPNConversionMethod5 "2.1.0";
BA_ "SAEDocument" SG_ 2566834688 SPNConversionMethod5 "J1939-73";
BA_ "Variable" SG_ 2566834688 SPNConversionMethod5 "N/A";
BA_ "SPN" SG_ 2566834688 SPNConversionMethod5 1706;
BA_ "Status" SG_ 2566834688 SPNConversionMethod4 "2.1.0";
BA_ "SAEDocument" SG_ 2566834688 SPNConversionMethod4 "J1939-73";
BA_ "Variable" SG_ 2566834688 SPNConversionMethod4 "N/A";
BA_ "SPN" SG_ 2566834688 SPNConversionMethod4 1706;
BA_ "Status" SG_ 2566834688 SPNConversionMethod3 "2.1.0";
BA_ "SAEDocument" SG_ 2566834688 SPNConversionMethod3 "J1939-73";
BA_ "Variable" SG_ 2566834688 SPNConversionMethod3 "N/A";
BA_ "SPN" SG_ 2566834688 SPNConversionMethod3 1706;
BA_ "Status" SG_ 2566834688 SPNConversionMethod2 "2.1.0";
BA_ "SAEDocument" SG_ 2566834688 SPNConversionMethod2 "J1939-73";
BA_ "Variable" SG_ 2566834688 SPNConversionMethod2 "N/A";
BA_ "SPN" SG_ 2566834688 SPNConversionMethod2 1706;
BA_ "Status" SG_ 2566834688 OccurenceCount5 "2.1.0";
BA_ "SigType" SG_ 2566834688 OccurenceCount5 "RANGE";
BA_ "SAEDocument" SG_ 2566834688 OccurenceCount5 "J1939-73";
BA_ "Variable" SG_ 2566834688 OccurenceCount5 "N/A";
BA_ "SPN" SG_ 2566834688 OccurenceCount5 1216;
BA_ "Status" SG_ 2566834688 OccurenceCount4 "2.1.0";
BA_ "SigType" SG_ 2566834688 OccurenceCount4 "RANGE";
BA_ "SAEDocument" SG_ 2566834688 OccurenceCount4 "J1939-73";
BA_ "Variable" SG_ 2566834688 OccurenceCount4 "N/A";
BA_ "SPN" SG_ 2566834688 OccurenceCount4 1216;
BA_ "Status" SG_ 2566834688 OccurenceCount3 "2.1.0";
BA_ "SigType" SG_ 2566834688 OccurenceCount3 "RANGE";
BA_ "SAEDocument" SG_ 2566834688 OccurenceCount3 "J1939-73";
BA_ "Variable" SG_ 2566834688 OccurenceCount3 "N/A";
BA_ "SPN" SG_ 2566834688 OccurenceCount3 1216;
BA_ "Status" SG_ 2566834688 OccurenceCount2 "2.1.0";
BA_ "SigType" SG_ 2566834688 OccurenceCount2 "RANGE";
BA_ "SAEDocument" SG_ 2566834688 OccurenceCount2 "J1939-73";
BA_ "Variable" SG_ 2566834688 OccurenceCount2 "N/A";
BA_ "SPN" SG_ 2566834688 OccurenceCount2 1216;
BA_ "Status" SG_ 2566834688 SPN5High "2.1.0";
BA_ "SAEDocument" SG_ 2566834688 SPN5High "J1939-73";
BA_ "Variable" SG_ 2566834688 SPN5High "N/A";
BA_ "SPN" SG_ 2566834688 SPN5High 1214;
BA_ "Status" SG_ 2566834688 SPN4High "2.1.0";
BA_ "SAEDocument" SG_ 2566834688 SPN4High "J1939-73";
BA_ "Variable" SG_ 2566834688 SPN4High "N/A";
BA_ "SPN" SG_ 2566834688 SPN4High 1214;
BA_ "Status" SG_ 2566834688 SPN3High "2.1.0";
BA_ "SAEDocument" SG_ 2566834688 SPN3High "J1939-73";
BA_ "Variable" SG_ 2566834688 SPN3High "N/A";
BA_ "SPN" SG_ 2566834688 SPN3High 1214;
BA_ "Status" SG_ 2566834688 SPN2High "2.1.0";
BA_ "SAEDocument" SG_ 2566834688 SPN2High "J1939-73";
BA_ "Variable" SG_ 2566834688 SPN2High "N/A";
BA_ "SPN" SG_ 2566834688 SPN2High 1214;
BA_ "Status" SG_ 2566834688 SPN1High "2.1.0";
BA_ "SPN" SG_ 2566834688 SPN1High 1214;
BA_ "SAEDocument" SG_ 2566834688 SPN1High "J1939-73";
BA_ "Variable" SG_ 2566834688 SPN1High "N/A";
BA_ "SAEDocument" SG_ 2565865739 TrailerABSWarningSignal "J1939-71";
BA_ "SPN" SG_ 2565865739 TrailerABSWarningSignal 1792;
BA_ "SigType" SG_ 2565865739 TrailerABSWarningSignal "DISCRETE";
BA_ "Variable" SG_ 2565865739 TrailerABSWarningSignal "Com_stTrailerABSWrnSig";
BA_ "Status" SG_ 2565865739 TrailerABSWarningSignal "Requested 3.7.0";
BA_ "SAEDocument" SG_ 2565865739 TrailerABSStatus "J1939-71";
BA_ "SPN" SG_ 2565865739 TrailerABSStatus 1836;
BA_ "SigType" SG_ 2565865739 TrailerABSStatus "DISCRETE";
BA_ "Variable" SG_ 2565865739 TrailerABSStatus "Com_stABSTrailer";
BA_ "Status" SG_ 2565865739 TrailerABSStatus "Requested 3.7.0";
BA_ "SAEDocument" SG_ 2565865739 ASRBrakeControlActive "J1939-71";
BA_ "SPN" SG_ 2565865739 ASRBrakeControlActive 562;
BA_ "SigType" SG_ 2565865739 ASRBrakeControlActive "DISCRETE";
BA_ "Variable" SG_ 2565865739 ASRBrakeControlActive "Com_stASRBrkCtl";
BA_ "Status" SG_ 2565865739 ASRBrakeControlActive "Requested 3.7.0";
BA_ "SAEDocument" SG_ 2565865739 ABS_EBSAmberWarningSignal "J1939-71";
BA_ "SPN" SG_ 2565865739 ABS_EBSAmberWarningSignal 1438;
BA_ "SigType" SG_ 2565865739 ABS_EBSAmberWarningSignal "DISCRETE";
BA_ "Variable" SG_ 2565865739 ABS_EBSAmberWarningSignal "Com_stABSWrnSig";
BA_ "Status" SG_ 2565865739 ABS_EBSAmberWarningSignal "Requested 3.7.0";
BA_ "SigType" SG_ 2565865739 ABSFullyOperational "DISCRETE";
BA_ "SPN" SG_ 2565865739 ABSFullyOperational 1243;
BA_ "SAEDocument" SG_ 2565865739 ABSFullyOperational "J1939-71";
BA_ "Status" SG_ 2565865739 ABSFullyOperational "Not needed";
BA_ "SigType" SG_ 2565865739 EngRetarderSelection "RANGE";
BA_ "SPN" SG_ 2565865739 EngRetarderSelection 973;
BA_ "SAEDocument" SG_ 2565865739 EngRetarderSelection "J1939-71";
BA_ "Status" SG_ 2565865739 EngRetarderSelection "Not needed";
BA_ "SigType" SG_ 2565865739 EngAuxEngShutdownSwitch "DISCRETE";
BA_ "SPN" SG_ 2565865739 EngAuxEngShutdownSwitch 970;
BA_ "SAEDocument" SG_ 2565865739 EngAuxEngShutdownSwitch "J1939-71";
BA_ "Variable" SG_ 2565865739 EngAuxEngShutdownSwitch "Com_stEngShOffEBC1";
BA_ "Status" SG_ 2565865739 EngAuxEngShutdownSwitch "Not needed";
BA_ "SigType" SG_ 2565865739 EngDerateSwitch "DISCRETE";
BA_ "SPN" SG_ 2565865739 EngDerateSwitch 971;
BA_ "SAEDocument" SG_ 2565865739 EngDerateSwitch "J1939-71";
BA_ "Status" SG_ 2565865739 EngDerateSwitch "Not needed";
BA_ "SigType" SG_ 2565865739 AccelInterlockSwitch "DISCRETE";
BA_ "SPN" SG_ 2565865739 AccelInterlockSwitch 972;
BA_ "SAEDocument" SG_ 2565865739 AccelInterlockSwitch "J1939-71";
BA_ "Status" SG_ 2565865739 AccelInterlockSwitch "Not needed";
BA_ "SigType" SG_ 2565865739 TractionCtrlOverrideSwitch "DISCRETE";
BA_ "SPN" SG_ 2565865739 TractionCtrlOverrideSwitch 1238;
BA_ "SAEDocument" SG_ 2565865739 TractionCtrlOverrideSwitch "J1939-71";
BA_ "Status" SG_ 2565865739 TractionCtrlOverrideSwitch "Not needed";
BA_ "SigType" SG_ 2565865739 AntiLockBrakingActive "DISCRETE";
BA_ "SPN" SG_ 2565865739 AntiLockBrakingActive 563;
BA_ "SAEDocument" SG_ 2565865739 AntiLockBrakingActive "J1939-71";
BA_ "Status" SG_ 2565865739 AntiLockBrakingActive "2.1.0";
BA_ "Variable" SG_ 2565865739 AntiLockBrakingActive "Com_stABSEngCtl";
BA_ "Status" SG_ 2565668608 TotalNumberOfPacketsEoMA "Ok";
BA_ "Variable" SG_ 2565668608 TotalNumberOfPacketsEoMA "N/A";
BA_ "SigType" SG_ 2565668608 TotalNumberOfPacketsEoMA "RANGE";
BA_ "SPN" SG_ 2565668608 TotalNumberOfPacketsEoMA 2558;
BA_ "SAEDocument" SG_ 2565668608 TotalNumberOfPacketsEoMA "J1939-21";
BA_ "Status" SG_ 2565668608 TotalMessageSizeEoMA "Ok";
BA_ "Variable" SG_ 2565668608 TotalMessageSizeEoMA "N/A";
BA_ "SigType" SG_ 2565668608 TotalMessageSizeEoMA "RANGE";
BA_ "SPN" SG_ 2565668608 TotalMessageSizeEoMA 2557;
BA_ "SAEDocument" SG_ 2565668608 TotalMessageSizeEoMA "J1939-21";
BA_ "Status" SG_ 2565668608 TotalMessageSizeBAM "Ok";
BA_ "Variable" SG_ 2565668608 TotalMessageSizeBAM "N/A";
BA_ "SigType" SG_ 2565668608 TotalMessageSizeBAM "RANGE";
BA_ "SPN" SG_ 2565668608 TotalMessageSizeBAM 2557;
BA_ "SAEDocument" SG_ 2565668608 TotalMessageSizeBAM "J1939-21";
BA_ "Status" SG_ 2565668608 TotalNumberOfPacketsBAM "Ok";
BA_ "Variable" SG_ 2565668608 TotalNumberOfPacketsBAM "N/A";
BA_ "SigType" SG_ 2565668608 TotalNumberOfPacketsBAM "RANGE";
BA_ "SPN" SG_ 2565668608 TotalNumberOfPacketsBAM 2558;
BA_ "SAEDocument" SG_ 2565668608 TotalNumberOfPacketsBAM "J1939-21";
BA_ "Status" SG_ 2565668608 ConnectionAbortReason "Ok";
BA_ "Variable" SG_ 2565668608 ConnectionAbortReason "N/A";
BA_ "SigType" SG_ 2565668608 ConnectionAbortReason "RANGE";
BA_ "SPN" SG_ 2565668608 ConnectionAbortReason 2570;
BA_ "SAEDocument" SG_ 2565668608 ConnectionAbortReason "J1939-21";
BA_ "Status" SG_ 2565668608 NextPacketNumberToBeSent "Ok";
BA_ "Variable" SG_ 2565668608 NextPacketNumberToBeSent "N/A";
BA_ "SigType" SG_ 2565668608 NextPacketNumberToBeSent "RANGE";
BA_ "SPN" SG_ 2565668608 NextPacketNumberToBeSent 2562;
BA_ "SAEDocument" SG_ 2565668608 NextPacketNumberToBeSent "J1939-21";
BA_ "Status" SG_ 2565668608 NumberOfPacketsThatCanBeSent "Ok";
BA_ "Variable" SG_ 2565668608 NumberOfPacketsThatCanBeSent "N/A";
BA_ "SigType" SG_ 2565668608 NumberOfPacketsThatCanBeSent "RANGE";
BA_ "SPN" SG_ 2565668608 NumberOfPacketsThatCanBeSent 2561;
BA_ "SAEDocument" SG_ 2565668608 NumberOfPacketsThatCanBeSent "J1939-21";
BA_ "Status" SG_ 2565668608 PGNumber "Ok";
BA_ "Variable" SG_ 2565668608 PGNumber "N/A";
BA_ "SPN" SG_ 2565668608 PGNumber 2560;
BA_ "SAEDocument" SG_ 2565668608 PGNumber "J1939-21";
BA_ "Status" SG_ 2565668608 MaximumNumberOfPackets "Ok";
BA_ "Variable" SG_ 2565668608 MaximumNumberOfPackets "N/A";
BA_ "SigType" SG_ 2565668608 MaximumNumberOfPackets "RANGE";
BA_ "SPN" SG_ 2565668608 MaximumNumberOfPackets 2559;
BA_ "SAEDocument" SG_ 2565668608 MaximumNumberOfPackets "J1939-21";
BA_ "Status" SG_ 2565668608 TotalNumberOfPackets "Ok";
BA_ "Variable" SG_ 2565668608 TotalNumberOfPackets "N/A";
BA_ "SigType" SG_ 2565668608 TotalNumberOfPackets "RANGE";
BA_ "SPN" SG_ 2565668608 TotalNumberOfPackets 2558;
BA_ "SAEDocument" SG_ 2565668608 TotalNumberOfPackets "J1939-21";
BA_ "Status" SG_ 2565668608 TotalMessageSize "Ok";
BA_ "Variable" SG_ 2565668608 TotalMessageSize "N/A";
BA_ "SigType" SG_ 2565668608 TotalMessageSize "RANGE";
BA_ "SPN" SG_ 2565668608 TotalMessageSize 2557;
BA_ "SAEDocument" SG_ 2565668608 TotalMessageSize "J1939-21";
BA_ "Status" SG_ 2565668608 ControlByte "Ok";
BA_ "Variable" SG_ 2565668608 ControlByte "N/A";
BA_ "SPN" SG_ 2565668608 ControlByte 2556;
BA_ "SAEDocument" SG_ 2565668608 ControlByte "J1939-21";
BA_ "Status" SG_ 2565472279 ParameterGroupNumber "Ok";
BA_ "Variable" SG_ 2565472279 ParameterGroupNumber "N/A";
BA_ "SigType" SG_ 2565472279 ParameterGroupNumber "RANGE";
BA_ "SPN" SG_ 2565472279 ParameterGroupNumber 2540;
BA_ "SAEDocument" SG_ 2565472279 ParameterGroupNumber "J1939-21";
BA_ "Variable" SG_ 2566839296 EngTotalIdleHours "EngDa_ti[0]";
BA_ "SigType" SG_ 2566839296 EngTotalIdleHours "RANGE";
BA_ "SPN" SG_ 2566839296 EngTotalIdleHours 235;
BA_ "SAEDocument" SG_ 2566839296 EngTotalIdleHours "J1939-71";
BA_ "Status" SG_ 2566839296 EngTotalIdleHours "2.1.0";
BA_ "Status" SG_ 2566839296 EngTotalIdleFuelUsed "2.3.0";
BA_ "SigType" SG_ 2566839296 EngTotalIdleFuelUsed "RANGE";
BA_ "SPN" SG_ 2566839296 EngTotalIdleFuelUsed 236;
BA_ "SAEDocument" SG_ 2566839296 EngTotalIdleFuelUsed "J1939-71";
BA_ "Variable" SG_ 2566839296 EngTotalIdleFuelUsed "FlSys_volIdlFlConsTot";
BA_ "Variable" SG_ 2566845952 EngExhaustGasTemp "Exh_tAdapTPFltUs";
BA_ "SigType" SG_ 2566845952 EngExhaustGasTemp "RANGE";
BA_ "SPN" SG_ 2566845952 EngExhaustGasTemp 173;
BA_ "SAEDocument" SG_ 2566845952 EngExhaustGasTemp "J1939-71";
BA_ "Status" SG_ 2566845952 EngExhaustGasTemp "Not needed";
BA_ "Variable" SG_ 2566845952 EngIntakeManifold1Temp "Air_tSensTIntkVUs";
BA_ "SigType" SG_ 2566845952 EngIntakeManifold1Temp "RANGE";
BA_ "SPN" SG_ 2566845952 EngIntakeManifold1Temp 105;
BA_ "SAEDocument" SG_ 2566845952 EngIntakeManifold1Temp "J1939-71";
BA_ "Status" SG_ 2566845952 EngIntakeManifold1Temp "3.4.0";
BA_ "Variable" SG_ 2566845952 EngTurboBoostPress "Com_pEngBP";
BA_ "SigType" SG_ 2566845952 EngTurboBoostPress "RANGE";
BA_ "SPN" SG_ 2566845952 EngTurboBoostPress 102;
BA_ "SAEDocument" SG_ 2566845952 EngTurboBoostPress "J1939-71";
BA_ "Status" SG_ 2566845952 EngTurboBoostPress "2.4.0";
BA_ "Variable" SG_ 2566845952 EngParticulateTrapInletPress "Exh_pPFltUs";
BA_ "SigType" SG_ 2566845952 EngParticulateTrapInletPress "RANGE";
BA_ "SPN" SG_ 2566845952 EngParticulateTrapInletPress 81;
BA_ "SAEDocument" SG_ 2566845952 EngParticulateTrapInletPress "J1939-71";
BA_ "Status" SG_ 2566845952 EngParticulateTrapInletPress "Not needed";
BA_ "Status" SG_ 2565867774 FireApparatusPumpEngagement "3.1.0";
BA_ "Variable" SG_ 2565867774 FireApparatusPumpEngagement "Com_stPmpMode";
BA_ "SigType" SG_ 2565867774 FireApparatusPumpEngagement "DISCRETE";
BA_ "SPN" SG_ 2565867774 FireApparatusPumpEngagement 2599;
BA_ "SAEDocument" SG_ 2565867774 FireApparatusPumpEngagement "J1939-71";
BA_ "SigType" SG_ 2565867774 EngHydPressGovernorSwitch "DISCRETE";
BA_ "SPN" SG_ 2565867774 EngHydPressGovernorSwitch 1764;
BA_ "SAEDocument" SG_ 2565867774 EngHydPressGovernorSwitch "J1939-71";
BA_ "Status" SG_ 2565867774 EngHydPressGovernorSwitch "Not needed";
BA_ "Variable" SG_ 2566759457 EnggmntSttusTransInputShaftPTO1 "Com_stPTOTraIn";
BA_ "Status" SG_ 2566759457 EnggmntSttusTransInputShaftPTO1 "3.1.0";
BA_ "SigType" SG_ 2566759457 EnggmntSttusTransInputShaftPTO1 "DISCRETE";
BA_ "SPN" SG_ 2566759457 EnggmntSttusTransInputShaftPTO1 3460;
BA_ "SAEDocument" SG_ 2566759457 EnggmntSttusTransInputShaftPTO1 "J1939-71";
BA_ "Variable" SG_ 2566759457 EnggmntSttusTransOutputShaftPTO "Com_stPTOTraOut";
BA_ "Status" SG_ 2566759457 EnggmntSttusTransOutputShaftPTO "3.1.0";
BA_ "SigType" SG_ 2566759457 EnggmntSttusTransOutputShaftPTO "DISCRETE";
BA_ "SPN" SG_ 2566759457 EnggmntSttusTransOutputShaftPTO 3462;
BA_ "SAEDocument" SG_ 2566759457 EnggmntSttusTransOutputShaftPTO "J1939-71";
BA_ "Variable" SG_ 2566759457 EnggmntSttsTrnsfrCsOtptShaftPTO "Com_stPTOTrnsfrCaseIn";
BA_ "Status" SG_ 2566759457 EnggmntSttsTrnsfrCsOtptShaftPTO "3.1.0";
BA_ "SigType" SG_ 2566759457 EnggmntSttsTrnsfrCsOtptShaftPTO "DISCRETE";
BA_ "SPN" SG_ 2566759457 EnggmntSttsTrnsfrCsOtptShaftPTO 3463;
BA_ "SAEDocument" SG_ 2566759457 EnggmntSttsTrnsfrCsOtptShaftPTO "J1939-71";
BA_ "SigType" SG_ 2566758656 Aftertreatment1FuelDrainAct "DISCRETE";
BA_ "SPN" SG_ 2566758656 Aftertreatment1FuelDrainAct 4097;
BA_ "SAEDocument" SG_ 2566758656 Aftertreatment1FuelDrainAct "J1939-71";
BA_ "Status" SG_ 2566758656 Aftertreatment1FuelDrainAct "Not needed";
BA_ "Variable" SG_ 2566758656 Aftertreatment1FuelActuator "Com_stFlEnblAT";
BA_ "SigType" SG_ 2566758656 Aftertreatment1FuelActuator "DISCRETE";
BA_ "SPN" SG_ 2566758656 Aftertreatment1FuelActuator 3482;
BA_ "SAEDocument" SG_ 2566758656 Aftertreatment1FuelActuator "J1939-71";
BA_ "Status" SG_ 2566758656 Aftertreatment1FuelActuator "3.1.0";
BA_ "SigType" SG_ 2566758656 Aftertreatment1RegenStatus "DISCRETE";
BA_ "SPN" SG_ 2566758656 Aftertreatment1RegenStatus 3483;
BA_ "SAEDocument" SG_ 2566758656 Aftertreatment1RegenStatus "J1939-71";
BA_ "Variable" SG_ 2566758656 Aftertreatment1RegenStatus "Com_stRgnAT";
BA_ "Status" SG_ 2566758656 Aftertreatment1RegenStatus "2.3.0";
BA_ "Variable" SG_ 2566758656 Aftertreatment1FuelPressCtrl "HCDosVlv_rPs";
BA_ "SigType" SG_ 2566758656 Aftertreatment1FuelPressCtrl "RANGE";
BA_ "SPN" SG_ 2566758656 Aftertreatment1FuelPressCtrl 3479;
BA_ "SAEDocument" SG_ 2566758656 Aftertreatment1FuelPressCtrl "J1939-71";
BA_ "Status" SG_ 2566758656 Aftertreatment1FuelPressCtrl "2.1.0";
BA_ "SigType" SG_ 2566758656 Aftertreatment1FuelRate "RANGE";
BA_ "SPN" SG_ 2566758656 Aftertreatment1FuelRate 3481;
BA_ "SAEDocument" SG_ 2566758656 Aftertreatment1FuelRate "J1939-71";
BA_ "Variable" SG_ 2566758656 Aftertreatment1FuelRate "PFltRgn_dvolFlRgnAct";
BA_ "Status" SG_ 2566758656 Aftertreatment1FuelRate "2.3.0";
BA_ "Variable" SG_ 2566758656 Aftertreatment1FuelPress "DPM_pSensHDVUsP";
BA_ "SigType" SG_ 2566758656 Aftertreatment1FuelPress "RANGE";
BA_ "SPN" SG_ 2566758656 Aftertreatment1FuelPress 3480;
BA_ "SAEDocument" SG_ 2566758656 Aftertreatment1FuelPress "J1939-71";
BA_ "Status" SG_ 2566758656 Aftertreatment1FuelPress "Requested 3.7.0";
BA_ "Status" SG_ 2566756352 Aftertreatment1AvgTimeBetRegn "3.10.0";
BA_ "SigType" SG_ 2566756352 Aftertreatment1AvgTimeBetRegn "RANGE";
BA_ "SPN" SG_ 2566756352 Aftertreatment1AvgTimeBetRegn 5454;
BA_ "SAEDocument" SG_ 2566756352 Aftertreatment1AvgTimeBetRegn "J1939-71";
BA_ "Status" SG_ 2566756352 AftrTrtmnt1TtlActvRgnInhRqsts "2.3.0";
BA_ "SigType" SG_ 2566756352 AftrTrtmnt1TtlActvRgnInhRqsts "RANGE";
BA_ "SPN" SG_ 2566756352 AftrTrtmnt1TtlActvRgnInhRqsts 3727;
BA_ "SAEDocument" SG_ 2566756352 AftrTrtmnt1TtlActvRgnInhRqsts "J1939-71";
BA_ "Variable" SG_ 2566756352 AftrTrtmnt1TtlActvRgnInhRqsts "PFltRgn_numRgnInhExt";
BA_ "Status" SG_ 2566756352 AftrTrtmnt1TtlActvRgnMnlRqsts "2.3.0";
BA_ "SigType" SG_ 2566756352 AftrTrtmnt1TtlActvRgnMnlRqsts "RANGE";
BA_ "SPN" SG_ 2566756352 AftrTrtmnt1TtlActvRgnMnlRqsts 3728;
BA_ "SAEDocument" SG_ 2566756352 AftrTrtmnt1TtlActvRgnMnlRqsts "J1939-71";
BA_ "Variable" SG_ 2566756352 AftrTrtmnt1TtlActvRgnMnlRqsts "PFltRgn_numRgnDemExt";
BA_ "SigType" SG_ 2566756352 Aftertreatment1TotalNumActRegens "RANGE";
BA_ "SPN" SG_ 2566756352 Aftertreatment1TotalNumActRegens 3525;
BA_ "SAEDocument" SG_ 2566756352 Aftertreatment1TotalNumActRegens "J1939-71";
BA_ "Status" SG_ 2566756352 Aftertreatment1TotalNumActRegens "2.3.0";
BA_ "Variable" SG_ 2566756352 Aftertreatment1TotalNumActRegens "PFltRgn_ctRgnSuc";
BA_ "Status" SG_ 2566756352 Aftertreatment1TotalRegenTime "2.3.0";
BA_ "SigType" SG_ 2566756352 Aftertreatment1TotalRegenTime "RANGE";
BA_ "SPN" SG_ 2566756352 Aftertreatment1TotalRegenTime 3523;
BA_ "SAEDocument" SG_ 2566756352 Aftertreatment1TotalRegenTime "J1939-71";
BA_ "Variable" SG_ 2566756352 Aftertreatment1TotalRegenTime "PFltRgn_tiRgnTot";
BA_ "Status" SG_ 2566756352 Aftertreatment1TotalDisabledTime "2.3.0";
BA_ "SigType" SG_ 2566756352 Aftertreatment1TotalDisabledTime "RANGE";
BA_ "SPN" SG_ 2566756352 Aftertreatment1TotalDisabledTime 3524;
BA_ "SAEDocument" SG_ 2566756352 Aftertreatment1TotalDisabledTime "J1939-71";
BA_ "Variable" SG_ 2566756352 Aftertreatment1TotalDisabledTime "PFltRgn_tiRgnInhTot";
BA_ "SigType" SG_ 2566756352 Aftertreatment1TotalFuelUsed "RANGE";
BA_ "SPN" SG_ 2566756352 Aftertreatment1TotalFuelUsed 3522;
BA_ "SAEDocument" SG_ 2566756352 Aftertreatment1TotalFuelUsed "J1939-71";
BA_ "Status" SG_ 2566756352 Aftertreatment1TotalFuelUsed "3.4.6";
BA_ "Variable" SG_ 2566756352 Aftertreatment1TotalFuelUsed "HCIPOD_qDosQntLfTime";
BA_ "Status" SG_ 2431654400 EngFuelActuator1CtrlCmd "2.2.0";
BA_ "Variable" SG_ 2431654400 EngFuelActuator1CtrlCmd "MeUn_rPs";
BA_ "SAEDocument" SG_ 2431654400 EngFuelActuator1CtrlCmd "J1939-71";
BA_ "SPN" SG_ 2431654400 EngFuelActuator1CtrlCmd 633;
BA_ "SigType" SG_ 2431654400 EngFuelActuator1CtrlCmd "RANGE";
BA_ "Status" SG_ 2431654400 EngThrottleActuator1CtrlCmd "2.2.0";
BA_ "Variable" SG_ 2431654400 EngThrottleActuator1CtrlCmd "ThrVlv_rPs";
BA_ "SigType" SG_ 2431654400 EngThrottleActuator1CtrlCmd "RANGE";
BA_ "SPN" SG_ 2431654400 EngThrottleActuator1CtrlCmd 3464;
BA_ "SAEDocument" SG_ 2431654400 EngThrottleActuator1CtrlCmd "J1939-71";
BA_ "Variable" SG_ 2431654400 EngFuelActuator2CtrlCmd "PCV_rPs";
BA_ "Status" SG_ 2431654400 EngFuelActuator2CtrlCmd "2.2.0";
BA_ "SigType" SG_ 2431654400 EngFuelActuator2CtrlCmd "RANGE";
BA_ "SPN" SG_ 2431654400 EngFuelActuator2CtrlCmd 1244;
BA_ "SAEDocument" SG_ 2431654400 EngFuelActuator2CtrlCmd "J1939-71";
BA_ "Status" SG_ 2566764544 PMFilterMonComplete "Ok";
BA_ "SPN" SG_ 2566764544 PMFilterMonComplete 3305;
BA_ "SAEDocument" SG_ 2566764544 PMFilterMonComplete "J1939-73";
BA_ "Variable" SG_ 2566764544 PMFilterMonComplete "N/A";
BA_ "Status" SG_ 2566764544 NOxCnvrtctlystMonComplete "Ok";
BA_ "SPN" SG_ 2566764544 NOxCnvrtctlystMonComplete 3305;
BA_ "SAEDocument" SG_ 2566764544 NOxCnvrtctlystMonComplete "J1939-73";
BA_ "Variable" SG_ 2566764544 NOxCnvrtctlystMonComplete "N/A";
BA_ "Status" SG_ 2566764544 NHMCCnvrtctlystMonComplete "Ok";
BA_ "SPN" SG_ 2566764544 NHMCCnvrtctlystMonComplete 3305;
BA_ "SAEDocument" SG_ 2566764544 NHMCCnvrtctlystMonComplete "J1939-73";
BA_ "Variable" SG_ 2566764544 NHMCCnvrtctlystMonComplete "N/A";
BA_ "Status" SG_ 2566764544 BstPressCtrlSystemMoncomplete "Ok";
BA_ "SPN" SG_ 2566764544 BstPressCtrlSystemMoncomplete 3305;
BA_ "SAEDocument" SG_ 2566764544 BstPressCtrlSystemMoncomplete "J1939-73";
BA_ "Variable" SG_ 2566764544 BstPressCtrlSystemMoncomplete "N/A";
BA_ "Status" SG_ 2566764544 NHMCCnvrtctlystMonEnabled "Ok";
BA_ "SPN" SG_ 2566764544 NHMCCnvrtctlystMonEnabled 3304;
BA_ "SAEDocument" SG_ 2566764544 NHMCCnvrtctlystMonEnabled "J1939-73";
BA_ "Variable" SG_ 2566764544 NHMCCnvrtctlystMonEnabled "N/A";
BA_ "Status" SG_ 2566764544 NOxCnvrtctlystMonEnabled "Ok";
BA_ "SPN" SG_ 2566764544 NOxCnvrtctlystMonEnabled 3304;
BA_ "SAEDocument" SG_ 2566764544 NOxCnvrtctlystMonEnabled "J1939-73";
BA_ "Variable" SG_ 2566764544 NOxCnvrtctlystMonEnabled "N/A";
BA_ "Status" SG_ 2566764544 PMFilterMonEnabled "Ok";
BA_ "SPN" SG_ 2566764544 PMFilterMonEnabled 3304;
BA_ "SAEDocument" SG_ 2566764544 PMFilterMonEnabled "J1939-73";
BA_ "Variable" SG_ 2566764544 PMFilterMonEnabled "N/A";
BA_ "Status" SG_ 2566764544 BstPressCtrlSystemMonEnabled "Ok";
BA_ "SPN" SG_ 2566764544 BstPressCtrlSystemMonEnabled 3304;
BA_ "SAEDocument" SG_ 2566764544 BstPressCtrlSystemMonEnabled "J1939-73";
BA_ "Variable" SG_ 2566764544 BstPressCtrlSystemMonEnabled "N/A";
BA_ "Status" SG_ 2566764544 MisfireMonitoringComplete "Ok";
BA_ "SPN" SG_ 2566764544 MisfireMonitoringComplete 3303;
BA_ "SAEDocument" SG_ 2566764544 MisfireMonitoringComplete "J1939-73";
BA_ "Variable" SG_ 2566764544 MisfireMonitoringComplete "N/A";
BA_ "Status" SG_ 2566764544 MisfireMonitoringEnabled "Ok";
BA_ "SPN" SG_ 2566764544 MisfireMonitoringEnabled 3303;
BA_ "SAEDocument" SG_ 2566764544 MisfireMonitoringEnabled "J1939-73";
BA_ "Variable" SG_ 2566764544 MisfireMonitoringEnabled "N/A";
BA_ "Status" SG_ 2566764544 FuelSystemMonitoringEnabled "Ok";
BA_ "SPN" SG_ 2566764544 FuelSystemMonitoringEnabled 3303;
BA_ "SAEDocument" SG_ 2566764544 FuelSystemMonitoringEnabled "J1939-73";
BA_ "Variable" SG_ 2566764544 FuelSystemMonitoringEnabled "N/A";
BA_ "Status" SG_ 2566764544 ComprehensiveComptMonComplete "Ok";
BA_ "SPN" SG_ 2566764544 ComprehensiveComptMonComplete 3303;
BA_ "SAEDocument" SG_ 2566764544 ComprehensiveComptMonComplete "J1939-73";
BA_ "Variable" SG_ 2566764544 ComprehensiveComptMonComplete "N/A";
BA_ "Status" SG_ 2566764544 ComprehensiveCompMonEnabled "Ok";
BA_ "SPN" SG_ 2566764544 ComprehensiveCompMonEnabled 3303;
BA_ "SAEDocument" SG_ 2566764544 ComprehensiveCompMonEnabled "J1939-73";
BA_ "Variable" SG_ 2566764544 ComprehensiveCompMonEnabled "N/A";
BA_ "Status" SG_ 2566764544 SecondAirSystemMonComplete "Ok";
BA_ "SPN" SG_ 2566764544 SecondAirSystemMonComplete 3305;
BA_ "SAEDocument" SG_ 2566764544 SecondAirSystemMonComplete "J1939-73";
BA_ "Variable" SG_ 2566764544 SecondAirSystemMonComplete "N/A";
BA_ "Status" SG_ 2566764544 SecondAirSystemMonEnabled "Ok";
BA_ "SPN" SG_ 2566764544 SecondAirSystemMonEnabled 3304;
BA_ "SAEDocument" SG_ 2566764544 SecondAirSystemMonEnabled "J1939-73";
BA_ "Variable" SG_ 2566764544 SecondAirSystemMonEnabled "N/A";
BA_ "Status" SG_ 2566764544 OxygenSensorMonComplete "Ok";
BA_ "SPN" SG_ 2566764544 OxygenSensorMonComplete 3305;
BA_ "SAEDocument" SG_ 2566764544 OxygenSensorMonComplete "J1939-73";
BA_ "Variable" SG_ 2566764544 OxygenSensorMonComplete "N/A";
BA_ "Status" SG_ 2566764544 OxygenSensorMonEnabled "Ok";
BA_ "SPN" SG_ 2566764544 OxygenSensorMonEnabled 3304;
BA_ "SAEDocument" SG_ 2566764544 OxygenSensorMonEnabled "J1939-73";
BA_ "Variable" SG_ 2566764544 OxygenSensorMonEnabled "N/A";
BA_ "Status" SG_ 2566764544 OxygenSensorHeaterMonComplete "Ok";
BA_ "SPN" SG_ 2566764544 OxygenSensorHeaterMonComplete 3305;
BA_ "SAEDocument" SG_ 2566764544 OxygenSensorHeaterMonComplete "J1939-73";
BA_ "Variable" SG_ 2566764544 OxygenSensorHeaterMonComplete "N/A";
BA_ "Status" SG_ 2566764544 OxygenSensorHeaterMonEnabled "Ok";
BA_ "SPN" SG_ 2566764544 OxygenSensorHeaterMonEnabled 3304;
BA_ "SAEDocument" SG_ 2566764544 OxygenSensorHeaterMonEnabled "J1939-73";
BA_ "Variable" SG_ 2566764544 OxygenSensorHeaterMonEnabled "N/A";
BA_ "Status" SG_ 2566764544 HeatedCatalystMonComplete "Ok";
BA_ "SPN" SG_ 2566764544 HeatedCatalystMonComplete 3305;
BA_ "SAEDocument" SG_ 2566764544 HeatedCatalystMonComplete "J1939-73";
BA_ "Variable" SG_ 2566764544 HeatedCatalystMonComplete "N/A";
BA_ "Status" SG_ 2566764544 HeatedCatalystMonEnabled "Ok";
BA_ "SPN" SG_ 2566764544 HeatedCatalystMonEnabled 3304;
BA_ "SAEDocument" SG_ 2566764544 HeatedCatalystMonEnabled "J1939-73";
BA_ "Variable" SG_ 2566764544 HeatedCatalystMonEnabled "N/A";
BA_ "Status" SG_ 2566764544 EvaporativeSystemMonComplete "Ok";
BA_ "SPN" SG_ 2566764544 EvaporativeSystemMonComplete 3305;
BA_ "SAEDocument" SG_ 2566764544 EvaporativeSystemMonComplete "J1939-73";
BA_ "Variable" SG_ 2566764544 EvaporativeSystemMonComplete "N/A";
BA_ "Status" SG_ 2566764544 EvaporativeSystemMonEnabled "Ok";
BA_ "SPN" SG_ 2566764544 EvaporativeSystemMonEnabled 3304;
BA_ "SAEDocument" SG_ 2566764544 EvaporativeSystemMonEnabled "J1939-73";
BA_ "Variable" SG_ 2566764544 EvaporativeSystemMonEnabled "N/A";
BA_ "Status" SG_ 2566764544 EGRSystemMonitoringComplete "Ok";
BA_ "SPN" SG_ 2566764544 EGRSystemMonitoringComplete 3305;
BA_ "SAEDocument" SG_ 2566764544 EGRSystemMonitoringComplete "J1939-73";
BA_ "Variable" SG_ 2566764544 EGRSystemMonitoringComplete "N/A";
BA_ "Status" SG_ 2566764544 EGRSystemMonitoringEnabled "Ok";
BA_ "SPN" SG_ 2566764544 EGRSystemMonitoringEnabled 3304;
BA_ "SAEDocument" SG_ 2566764544 EGRSystemMonitoringEnabled "J1939-73";
BA_ "Variable" SG_ 2566764544 EGRSystemMonitoringEnabled "N/A";
BA_ "Status" SG_ 2566764544 ColdStartAidSystemMonComplete "Ok";
BA_ "SPN" SG_ 2566764544 ColdStartAidSystemMonComplete 3305;
BA_ "SAEDocument" SG_ 2566764544 ColdStartAidSystemMonComplete "J1939-73";
BA_ "Variable" SG_ 2566764544 ColdStartAidSystemMonComplete "N/A";
BA_ "Status" SG_ 2566764544 ColdStartAidSystemMonEnabled "Ok";
BA_ "SPN" SG_ 2566764544 ColdStartAidSystemMonEnabled 3304;
BA_ "SAEDocument" SG_ 2566764544 ColdStartAidSystemMonEnabled "J1939-73";
BA_ "Variable" SG_ 2566764544 ColdStartAidSystemMonEnabled "N/A";
BA_ "Status" SG_ 2566764544 CatalystMonComplete "Ok";
BA_ "SPN" SG_ 2566764544 CatalystMonComplete 3305;
BA_ "SAEDocument" SG_ 2566764544 CatalystMonComplete "J1939-73";
BA_ "Variable" SG_ 2566764544 CatalystMonComplete "N/A";
BA_ "Status" SG_ 2566764544 CatalystMonEnabled "Ok";
BA_ "SPN" SG_ 2566764544 CatalystMonEnabled 3304;
BA_ "SAEDocument" SG_ 2566764544 CatalystMonEnabled "J1939-73";
BA_ "Variable" SG_ 2566764544 CatalystMonEnabled "N/A";
BA_ "Status" SG_ 2566764544 ACSystemRefrigerantMonComplete "Ok";
BA_ "SPN" SG_ 2566764544 ACSystemRefrigerantMonComplete 3305;
BA_ "SAEDocument" SG_ 2566764544 ACSystemRefrigerantMonComplete "J1939-73";
BA_ "Variable" SG_ 2566764544 ACSystemRefrigerantMonComplete "N/A";
BA_ "Status" SG_ 2566764544 ACSystemRefrigerantMonEnabled "Ok";
BA_ "SPN" SG_ 2566764544 ACSystemRefrigerantMonEnabled 3304;
BA_ "SAEDocument" SG_ 2566764544 ACSystemRefrigerantMonEnabled "J1939-73";
BA_ "Variable" SG_ 2566764544 ACSystemRefrigerantMonEnabled "N/A";
BA_ "Status" SG_ 2566764544 FuelSystemMonitoringComplete "Ok";
BA_ "SPN" SG_ 2566764544 FuelSystemMonitoringComplete 3303;
BA_ "SAEDocument" SG_ 2566764544 FuelSystemMonitoringComplete "J1939-73";
BA_ "Variable" SG_ 2566764544 FuelSystemMonitoringComplete "N/A";
BA_ "Status" SG_ 2566764544 NumOfWarmUpsSinceDTCsCleared "Ok";
BA_ "SPN" SG_ 2566764544 NumOfWarmUpsSinceDTCsCleared 3302;
BA_ "SAEDocument" SG_ 2566764544 NumOfWarmUpsSinceDTCsCleared "J1939-73";
BA_ "Variable" SG_ 2566764544 NumOfWarmUpsSinceDTCsCleared "N/A";
BA_ "Status" SG_ 2566764544 TimeSinceEngineStart "Ok";
BA_ "SPN" SG_ 2566764544 TimeSinceEngineStart 3301;
BA_ "SAEDocument" SG_ 2566764544 TimeSinceEngineStart "J1939-73";
BA_ "Variable" SG_ 2566764544 TimeSinceEngineStart "N/A";
BA_ "Status" SG_ 2566843392 VI_Delimiter "Ok";
BA_ "Variable" SG_ 2566843392 VI_Delimiter "N/A";
BA_ "SigType" SG_ 2566843392 VI_Delimiter "RANGE";
BA_ "SAEDocument" SG_ 2566843392 VI_Delimiter "J1939_71";
BA_ "SAEDocument" SG_ 2566843392 VIN_B17 "J1939_71";
BA_ "SPN" SG_ 2566843392 VIN_B17 237;
BA_ "SigType" SG_ 2566843392 VIN_B17 "RANGE";
BA_ "Status" SG_ 2566843392 VIN_B17 "Ok";
BA_ "SAEDocument" SG_ 2566843392 VIN_B09_B016 "J1939_71";
BA_ "SPN" SG_ 2566843392 VIN_B09_B016 237;
BA_ "SigType" SG_ 2566843392 VIN_B09_B016 "RANGE";
BA_ "Status" SG_ 2566843392 VIN_B09_B016 "Ok";
BA_ "Status" SG_ 2566843392 VIN_B01_B08 "Ok";
BA_ "SigType" SG_ 2566843392 VIN_B01_B08 "RANGE";
BA_ "SPN" SG_ 2566843392 VIN_B01_B08 237;
BA_ "SAEDocument" SG_ 2566843392 VIN_B01_B08 "J1939_71";
BA_ "Variable" SG_ 2566842112 TotalPowerTakeoffHours "EngDa_ti[1]";
BA_ "SigType" SG_ 2566842112 TotalPowerTakeoffHours "RANGE";
BA_ "SPN" SG_ 2566842112 TotalPowerTakeoffHours 248;
BA_ "SAEDocument" SG_ 2566842112 TotalPowerTakeoffHours "J1939-71";
BA_ "Status" SG_ 2566842112 TotalPowerTakeoffHours "2.1.0";
BA_ "SigType" SG_ 2566842112 TotalVehicleHours "RANGE";
BA_ "SPN" SG_ 2566842112 TotalVehicleHours 246;
BA_ "SAEDocument" SG_ 2566842112 TotalVehicleHours "J1939-71";
BA_ "Status" SG_ 2566842112 TotalVehicleHours "Not needed";
BA_ "Variable" SG_ 2566832384 HighResolutionTripDistance "GlbDa_ITrpDst";
BA_ "Status" SG_ 2566832384 HighResolutionTripDistance "3.2.0";
BA_ "SigType" SG_ 2566832384 HighResolutionTripDistance "RANGE";
BA_ "SPN" SG_ 2566832384 HighResolutionTripDistance 918;
BA_ "SAEDocument" SG_ 2566832384 HighResolutionTripDistance "J1939-71";
BA_ "SigType" SG_ 2566832384 HghRslutionTotalVehicleDistance "RANGE";
BA_ "SPN" SG_ 2566832384 HghRslutionTotalVehicleDistance 917;
BA_ "SAEDocument" SG_ 2566832384 HghRslutionTotalVehicleDistance "J1939-71";
BA_ "Status" SG_ 2566832384 HghRslutionTotalVehicleDistance "3.2.0";
BA_ "Variable" SG_ 2566832384 HghRslutionTotalVehicleDistance "GlbDa_ITotDst";
BA_ "SigType" SG_ 2348810243 EngRqedTorque_TorqueLimit "RANGE";
BA_ "SPN" SG_ 2348810243 EngRqedTorque_TorqueLimit 518;
BA_ "SAEDocument" SG_ 2348810243 EngRqedTorque_TorqueLimit "J1939-71";
BA_ "Status" SG_ 2348810243 EngRqedTorque_TorqueLimit "2.1.0";
BA_ "Variable" SG_ 2348810243 EngRqedTorque_TorqueLimit "Com_dTSC1*Trq";
BA_ "SigType" SG_ 2348810243 EngRqedSpeed_SpeedLimit "RANGE";
BA_ "SPN" SG_ 2348810243 EngRqedSpeed_SpeedLimit 898;
BA_ "SAEDocument" SG_ 2348810243 EngRqedSpeed_SpeedLimit "J1939-71";
BA_ "Status" SG_ 2348810243 EngRqedSpeed_SpeedLimit "2.1.0";
BA_ "Variable" SG_ 2348810243 EngRqedSpeed_SpeedLimit "Com_nTSC1*";
BA_ "SigType" SG_ 2348810243 OverrideCtrlModePriority "DISCRETE";
BA_ "SPN" SG_ 2348810243 OverrideCtrlModePriority 897;
BA_ "SAEDocument" SG_ 2348810243 OverrideCtrlModePriority "J1939-71";
BA_ "Status" SG_ 2348810243 OverrideCtrlModePriority "2.1.0";
BA_ "Variable" SG_ 2348810243 OverrideCtrlModePriority "Com_stTSC1*Prio";
BA_ "SigType" SG_ 2348810243 EngOverrideCtrlMode "DISCRETE";
BA_ "SPN" SG_ 2348810243 EngOverrideCtrlMode 695;
BA_ "SAEDocument" SG_ 2348810243 EngOverrideCtrlMode "J1939-71";
BA_ "Variable" SG_ 2348810243 EngOverrideCtrlMode "Com_stTSC1*Mode";
BA_ "Status" SG_ 2348810243 EngOverrideCtrlMode "2.1.0";
BA_ "Variable" SG_ 2633939712 TripFanOnTime "EngDa_tiFanOnTrip";
BA_ "Status" SG_ 2633939712 TripFanOnTime "3.2.0";
BA_ "SigType" SG_ 2633939712 TripFanOnTime "RANGE";
BA_ "SPN" SG_ 2633939712 TripFanOnTime 994;
BA_ "SAEDocument" SG_ 2633939712 TripFanOnTime "J1939-71";
BA_ "SigType" SG_ 2566821376 EngTurbo2WastegateDrive "RANGE";
BA_ "SPN" SG_ 2566821376 EngTurbo2WastegateDrive 1189;
BA_ "SAEDocument" SG_ 2566821376 EngTurbo2WastegateDrive "J1939-71";
BA_ "Status" SG_ 2566821376 EngTurbo2WastegateDrive "3.4.6";
BA_ "Variable" SG_ 2566821376 EngTurbo2WastegateDrive "TrbCh_rPs";
BA_ "SigType" SG_ 2566821376 EngTurbo1WastegateDrive "RANGE";
BA_ "SPN" SG_ 2566821376 EngTurbo1WastegateDrive 1188;
BA_ "SAEDocument" SG_ 2566821376 EngTurbo1WastegateDrive "J1939-71";
BA_ "Status" SG_ 2566821376 EngTurbo1WastegateDrive "3.4.6";
BA_ "Variable" SG_ 2566821376 EngTurbo1WastegateDrive "TrbnByVlvLP_rPs";
BA_ "Status" SG_ 2566822400 EngTurbo2CompressorInletTemp "2.4.0";
BA_ "SigType" SG_ 2566822400 EngTurbo2CompressorInletTemp "RANGE";
BA_ "SPN" SG_ 2566822400 EngTurbo2CompressorInletTemp 1173;
BA_ "SAEDocument" SG_ 2566822400 EngTurbo2CompressorInletTemp "J1939-71";
BA_ "Variable" SG_ 2566822400 EngTurbo2CompressorInletTemp "Air_tSensCACDsTLP";
BA_ "Variable" SG_ 2566802179 TransTorqueLimit "Com_trqLimTrans";
BA_ "Status" SG_ 2566802179 TransTorqueLimit "3.4.0";
BA_ "SigType" SG_ 2566802179 TransTorqueLimit "RANGE";
BA_ "SPN" SG_ 2566802179 TransTorqueLimit 1845;
BA_ "SAEDocument" SG_ 2566802179 TransTorqueLimit "J1939-71";
BA_ "Variable" SG_ 2566838784 ASCIIfromHEX7 "Frm_SOFT_CA";
BA_ "Status" SG_ 2566838784 ASCIIfromHEX7 "2.1.0";
BA_ "SPN" SG_ 2566838784 ASCIIfromHEX7 234;
BA_ "Variable" SG_ 2566838784 ASCIIfromHEX6 "Frm_SOFT_CA";
BA_ "Status" SG_ 2566838784 ASCIIfromHEX6 "2.1.0";
BA_ "SPN" SG_ 2566838784 ASCIIfromHEX6 234;
BA_ "Variable" SG_ 2566838784 ASCIIfromHEX5 "Frm_SOFT_CA";
BA_ "Status" SG_ 2566838784 ASCIIfromHEX5 "2.1.0";
BA_ "SPN" SG_ 2566838784 ASCIIfromHEX5 234;
BA_ "Variable" SG_ 2566838784 ASCIIfromHEX4 "Frm_SOFT_CA";
BA_ "Status" SG_ 2566838784 ASCIIfromHEX4 "2.1.0";
BA_ "SPN" SG_ 2566838784 ASCIIfromHEX4 234;
BA_ "Variable" SG_ 2566838784 ASCIIfromHEX3 "Frm_SOFT_CA";
BA_ "Status" SG_ 2566838784 ASCIIfromHEX3 "2.1.0";
BA_ "SPN" SG_ 2566838784 ASCIIfromHEX3 234;
BA_ "Variable" SG_ 2566838784 ASCIIfromHEX2 "Frm_SOFT_CA";
BA_ "Status" SG_ 2566838784 ASCIIfromHEX2 "2.1.0";
BA_ "SPN" SG_ 2566838784 ASCIIfromHEX2 234;
BA_ "Variable" SG_ 2566838784 ASCIIfromHEX1 "Frm_SOFT_CA";
BA_ "Status" SG_ 2566838784 ASCIIfromHEX1 "2.1.0";
BA_ "SPN" SG_ 2566838784 ASCIIfromHEX1 234;
BA_ "SigType" SG_ 2566838784 NmbrOfSftwrIdentificationFields "RANGE";
BA_ "SPN" SG_ 2566838784 NmbrOfSftwrIdentificationFields 965;
BA_ "SAEDocument" SG_ 2566838784 NmbrOfSftwrIdentificationFields "J1939-71";
BA_ "Status" SG_ 2566838784 NmbrOfSftwrIdentificationFields "2.1.0";
BA_ "Variable" SG_ 2566838784 NmbrOfSftwrIdentificationFields "N/A";
BA_ "SigType" SG_ 2566841344 EngProtectionSystemConfig "DISCRETE";
BA_ "SPN" SG_ 2566841344 EngProtectionSystemConfig 1111;
BA_ "SAEDocument" SG_ 2566841344 EngProtectionSystemConfig "J1939-71";
BA_ "Status" SG_ 2566841344 EngProtectionSystemConfig "3.4.6";
BA_ "Variable" SG_ 2566841344 EngProtectionSystemConfig "Com_stSupMonProt";
BA_ "SigType" SG_ 2566841344 EngProtectionSystemTimerState "DISCRETE";
BA_ "SPN" SG_ 2566841344 EngProtectionSystemTimerState 1107;
BA_ "SAEDocument" SG_ 2566841344 EngProtectionSystemTimerState "J1939-71";
BA_ "Status" SG_ 2566841344 EngProtectionSystemTimerState "3.4.6";
BA_ "Variable" SG_ 2566841344 EngProtectionSystemTimerState "Com_stShOffTmrSt";
BA_ "SigType" SG_ 2566841344 EngPrtectionSystemTimerOverride "DISCRETE";
BA_ "SPN" SG_ 2566841344 EngPrtectionSystemTimerOverride 1108;
BA_ "SAEDocument" SG_ 2566841344 EngPrtectionSystemTimerOverride "J1939-71";
BA_ "Status" SG_ 2566841344 EngPrtectionSystemTimerOverride "3.4.6";
BA_ "Variable" SG_ 2566841344 EngPrtectionSystemTimerOverride "Com_stShOffTmrOvrd";
BA_ "SigType" SG_ 2566841344 EngPrtctnSystmApprchingShutdown "DISCRETE";
BA_ "SPN" SG_ 2566841344 EngPrtctnSystmApprchingShutdown 1109;
BA_ "SAEDocument" SG_ 2566841344 EngPrtctnSystmApprchingShutdown "J1939-71";
BA_ "Status" SG_ 2566841344 EngPrtctnSystmApprchingShutdown "3.4.6";
BA_ "Variable" SG_ 2566841344 EngPrtctnSystmApprchingShutdown "Com_stShOffApproch";
BA_ "Variable" SG_ 2566841344 EngPrtctionSystemHasShutdownEng "Com_stShutDwn";
BA_ "SigType" SG_ 2566841344 EngPrtctionSystemHasShutdownEng "DISCRETE";
BA_ "SPN" SG_ 2566841344 EngPrtctionSystemHasShutdownEng 1110;
BA_ "SAEDocument" SG_ 2566841344 EngPrtctionSystemHasShutdownEng "J1939-71";
BA_ "Status" SG_ 2566841344 EngPrtctionSystemHasShutdownEng "2.1.0";
BA_ "Variable" SG_ 2566841344 EngWaitToStartLamp "GlwLmp_stPs";
BA_ "SigType" SG_ 2566841344 EngWaitToStartLamp "DISCRETE";
BA_ "SPN" SG_ 2566841344 EngWaitToStartLamp 1081;
BA_ "SAEDocument" SG_ 2566841344 EngWaitToStartLamp "J1939-71";
BA_ "Status" SG_ 2566841344 EngWaitToStartLamp "Requested 3.7.0";
BA_ "SigType" SG_ 2566841344 EngIdleShutdownTimerFunction "DISCRETE";
BA_ "SPN" SG_ 2566841344 EngIdleShutdownTimerFunction 591;
BA_ "SAEDocument" SG_ 2566841344 EngIdleShutdownTimerFunction "J1939-71";
BA_ "Status" SG_ 2566841344 EngIdleShutdownTimerFunction "3.2.0";
BA_ "Variable" SG_ 2566841344 EngIdleShutdownTimerFunction "CoEng_swtIdlShDwnMode_C";
BA_ "SigType" SG_ 2566841344 EngIdleShutdownTimerState "DISCRETE";
BA_ "SPN" SG_ 2566841344 EngIdleShutdownTimerState 590;
BA_ "SAEDocument" SG_ 2566841344 EngIdleShutdownTimerState "J1939-71";
BA_ "Variable" SG_ 2566841344 EngIdleShutdownTimerState "Com_stIdleShTi";
BA_ "Status" SG_ 2566841344 EngIdleShutdownTimerState "2.4.0";
BA_ "SigType" SG_ 2566841344 EngIdleShutdownTimerOverride "DISCRETE";
BA_ "SPN" SG_ 2566841344 EngIdleShutdownTimerOverride 592;
BA_ "SAEDocument" SG_ 2566841344 EngIdleShutdownTimerOverride "J1939-71";
BA_ "Status" SG_ 2566841344 EngIdleShutdownTimerOverride "3.2.0";
BA_ "Variable" SG_ 2566841344 EngIdleShutdownTimerOverride "CoEng_stStopIdlShDwnDesRaw bit 10";
BA_ "SigType" SG_ 2566841344 EngIdleShutdownDriverAlertMode "DISCRETE";
BA_ "SPN" SG_ 2566841344 EngIdleShutdownDriverAlertMode 594;
BA_ "SAEDocument" SG_ 2566841344 EngIdleShutdownDriverAlertMode "J1939-71";
BA_ "Variable" SG_ 2566841344 EngIdleShutdownDriverAlertMode "Com_stDrvAlMode";
BA_ "Status" SG_ 2566841344 EngIdleShutdownDriverAlertMode "2.4.0";
BA_ "SigType" SG_ 2566841344 EngIdleShutdownHasShutdownEng "DISCRETE";
BA_ "SPN" SG_ 2566841344 EngIdleShutdownHasShutdownEng 593;
BA_ "SAEDocument" SG_ 2566841344 EngIdleShutdownHasShutdownEng "J1939-71";
BA_ "Variable" SG_ 2566841344 EngIdleShutdownHasShutdownEng "Com_stIdleShDwn";
BA_ "Status" SG_ 2566841344 EngIdleShutdownHasShutdownEng "2.4.0";
BA_ "Variable" SG_ 2631859966 TripGroup2_Proprietary "Com_stTripGrp2Rst";
BA_ "Status" SG_ 2631859966 TripGroup2_Proprietary "3.2.0";
BA_ "SigType" SG_ 2631859966 TripGroup2_Proprietary "DISCRETE";
BA_ "SPN" SG_ 2631859966 TripGroup2_Proprietary 989;
BA_ "SAEDocument" SG_ 2631859966 TripGroup2_Proprietary "J1939-71";
BA_ "SigType" SG_ 2631859966 ServiceComponentIdentification "RANGE";
BA_ "SPN" SG_ 2631859966 ServiceComponentIdentification 1584;
BA_ "SAEDocument" SG_ 2631859966 ServiceComponentIdentification "J1939-71";
BA_ "Status" SG_ 2631859966 ServiceComponentIdentification "Not needed";
BA_ "Variable" SG_ 2631859966 TripGroup1 "Com_stTripGrpRst";
BA_ "Status" SG_ 2631859966 TripGroup1 "3.1.0";
BA_ "SigType" SG_ 2631859966 TripGroup1 "DISCRETE";
BA_ "SPN" SG_ 2631859966 TripGroup1 988;
BA_ "SAEDocument" SG_ 2631859966 TripGroup1 "J1939-71";
BA_ "SigType" SG_ 2566840591 PercentTorqueAtPeakTorquePoint5 "RANGE";
BA_ "SPN" SG_ 2566840591 PercentTorqueAtPeakTorquePoint5 555;
BA_ "SAEDocument" SG_ 2566840591 PercentTorqueAtPeakTorquePoint5 "J1939-71";
BA_ "Variable" SG_ 2566840591 PercentTorqueAtPeakTorquePoint5 "EngBrk_trqCfgPnt5";
BA_ "Status" SG_ 2566840591 PercentTorqueAtPeakTorquePoint5 "2.1.0";
BA_ "SigType" SG_ 2566840591 ReferenceRetarderTorque "RANGE";
BA_ "SPN" SG_ 2566840591 ReferenceRetarderTorque 556;
BA_ "SAEDocument" SG_ 2566840591 ReferenceRetarderTorque "J1939-71";
BA_ "Variable" SG_ 2566840591 ReferenceRetarderTorque "Frm_trqMin_C";
BA_ "Status" SG_ 2566840591 ReferenceRetarderTorque "2.1.0";
BA_ "SigType" SG_ 2566840591 RetarderSpeedAtPeakTorquePoint5 "RANGE";
BA_ "SPN" SG_ 2566840591 RetarderSpeedAtPeakTorquePoint5 547;
BA_ "SAEDocument" SG_ 2566840591 RetarderSpeedAtPeakTorquePoint5 "J1939-71";
BA_ "Variable" SG_ 2566840591 RetarderSpeedAtPeakTorquePoint5 "EngBrk_nCfgPnt5";
BA_ "Status" SG_ 2566840591 RetarderSpeedAtPeakTorquePoint5 "2.1.0";
BA_ "SigType" SG_ 2566840591 PercentTorqueAtPoint4 "RANGE";
BA_ "SPN" SG_ 2566840591 PercentTorqueAtPoint4 554;
BA_ "SAEDocument" SG_ 2566840591 PercentTorqueAtPoint4 "J1939-71";
BA_ "Variable" SG_ 2566840591 PercentTorqueAtPoint4 "EngBrk_trqCfgPnt4";
BA_ "Status" SG_ 2566840591 PercentTorqueAtPoint4 "2.1.0";
BA_ "SigType" SG_ 2566840591 RetarderSpeedAtPoint4 "RANGE";
BA_ "SPN" SG_ 2566840591 RetarderSpeedAtPoint4 550;
BA_ "SAEDocument" SG_ 2566840591 RetarderSpeedAtPoint4 "J1939-71";
BA_ "Variable" SG_ 2566840591 RetarderSpeedAtPoint4 "EngBrk_nCfgPnt4";
BA_ "Status" SG_ 2566840591 RetarderSpeedAtPoint4 "2.1.0";
BA_ "SigType" SG_ 2566840591 PercentTorqueAtPoint3 "RANGE";
BA_ "SPN" SG_ 2566840591 PercentTorqueAtPoint3 553;
BA_ "SAEDocument" SG_ 2566840591 PercentTorqueAtPoint3 "J1939-71";
BA_ "Variable" SG_ 2566840591 PercentTorqueAtPoint3 "EngBrk_trqCfgPnt3";
BA_ "Status" SG_ 2566840591 PercentTorqueAtPoint3 "2.1.0";
BA_ "SigType" SG_ 2566840591 RetarderSpeedAtPoint3 "RANGE";
BA_ "SPN" SG_ 2566840591 RetarderSpeedAtPoint3 549;
BA_ "SAEDocument" SG_ 2566840591 RetarderSpeedAtPoint3 "J1939-71";
BA_ "Variable" SG_ 2566840591 RetarderSpeedAtPoint3 "EngBrk_nCfgPnt3";
BA_ "Status" SG_ 2566840591 RetarderSpeedAtPoint3 "2.1.0";
BA_ "SigType" SG_ 2566840591 PercentTorqueAtMaxSpeedPoint2 "RANGE";
BA_ "SPN" SG_ 2566840591 PercentTorqueAtMaxSpeedPoint2 552;
BA_ "SAEDocument" SG_ 2566840591 PercentTorqueAtMaxSpeedPoint2 "J1939-71";
BA_ "Variable" SG_ 2566840591 PercentTorqueAtMaxSpeedPoint2 "EngBrk_trqCfgPnt2";
BA_ "Status" SG_ 2566840591 PercentTorqueAtMaxSpeedPoint2 "2.1.0";
BA_ "SigType" SG_ 2566840591 MaxRetarderSpeedPoint2 "RANGE";
BA_ "SPN" SG_ 2566840591 MaxRetarderSpeedPoint2 548;
BA_ "SAEDocument" SG_ 2566840591 MaxRetarderSpeedPoint2 "J1939-71";
BA_ "Variable" SG_ 2566840591 MaxRetarderSpeedPoint2 "EngBrk_nCfgPnt2";
BA_ "Status" SG_ 2566840591 MaxRetarderSpeedPoint2 "2.1.0";
BA_ "SigType" SG_ 2566840591 PercentTorqueAtIdlePoint1 "RANGE";
BA_ "SPN" SG_ 2566840591 PercentTorqueAtIdlePoint1 551;
BA_ "SAEDocument" SG_ 2566840591 PercentTorqueAtIdlePoint1 "J1939-71";
BA_ "Variable" SG_ 2566840591 PercentTorqueAtIdlePoint1 "EngBrk_trqCfgPnt1";
BA_ "Status" SG_ 2566840591 PercentTorqueAtIdlePoint1 "2.1.0";
BA_ "SigType" SG_ 2566840591 RetarderSpeedAtIdlePoint1 "RANGE";
BA_ "SPN" SG_ 2566840591 RetarderSpeedAtIdlePoint1 546;
BA_ "SAEDocument" SG_ 2566840591 RetarderSpeedAtIdlePoint1 "J1939-71";
BA_ "Variable" SG_ 2566840591 RetarderSpeedAtIdlePoint1 "EngBrk_nCfgPnt1";
BA_ "Status" SG_ 2566840591 RetarderSpeedAtIdlePoint1 "2.1.0";
BA_ "SigType" SG_ 2566840591 RetarderLocation "DISCRETE";
BA_ "SPN" SG_ 2566840591 RetarderLocation 902;
BA_ "SAEDocument" SG_ 2566840591 RetarderLocation "J1939-71";
BA_ "Variable" SG_ 2566840591 RetarderLocation "Frm_stRetCfgTypeLoc_C";
BA_ "Status" SG_ 2566840591 RetarderLocation "2.1.0";
BA_ "SigType" SG_ 2566840591 RetarderType "DISCRETE";
BA_ "SPN" SG_ 2566840591 RetarderType 901;
BA_ "SAEDocument" SG_ 2566840591 RetarderType "J1939-71";
BA_ "Variable" SG_ 2566840591 RetarderType "Frm_stRetCfgTypeLoc_C";
BA_ "Status" SG_ 2566840591 RetarderType "2.1.0";
BA_ "SAEDocument" SG_ 2566844449 PowerTakeoffSetSpeed "J1939-71";
BA_ "SPN" SG_ 2566844449 PowerTakeoffSetSpeed 187;
BA_ "SigType" SG_ 2566844449 PowerTakeoffSetSpeed "RANGE";
BA_ "Status" SG_ 2566844449 PowerTakeoffSetSpeed "Not needed";
BA_ "Variable" SG_ 2566844449 EngPTOAccelerateSwitch "Com_stPTOAcclSwt";
BA_ "Status" SG_ 2566844449 EngPTOAccelerateSwitch "3.1.0";
BA_ "SigType" SG_ 2566844449 EngPTOAccelerateSwitch "DISCRETE";
BA_ "SPN" SG_ 2566844449 EngPTOAccelerateSwitch 981;
BA_ "SAEDocument" SG_ 2566844449 EngPTOAccelerateSwitch "J1939-71";
BA_ "Variable" SG_ 2566844449 EngPTOResumeSwitch "Com_stPTOResuSwt";
BA_ "Status" SG_ 2566844449 EngPTOResumeSwitch "3.1.0";
BA_ "SigType" SG_ 2566844449 EngPTOResumeSwitch "DISCRETE";
BA_ "SPN" SG_ 2566844449 EngPTOResumeSwitch 982;
BA_ "SAEDocument" SG_ 2566844449 EngPTOResumeSwitch "J1939-71";
BA_ "Variable" SG_ 2566844449 EngPTOCoast_DecelerateSwitch "Com_stPTODeclSwt";
BA_ "Status" SG_ 2566844449 EngPTOCoast_DecelerateSwitch "3.1.0";
BA_ "SigType" SG_ 2566844449 EngPTOCoast_DecelerateSwitch "DISCRETE";
BA_ "SPN" SG_ 2566844449 EngPTOCoast_DecelerateSwitch 983;
BA_ "SAEDocument" SG_ 2566844449 EngPTOCoast_DecelerateSwitch "J1939-71";
BA_ "Variable" SG_ 2566844449 EngPTOSetSwitch "Com_stPTOSetSwt";
BA_ "Status" SG_ 2566844449 EngPTOSetSwitch "3.1.0";
BA_ "SigType" SG_ 2566844449 EngPTOSetSwitch "DISCRETE";
BA_ "SPN" SG_ 2566844449 EngPTOSetSwitch 984;
BA_ "SAEDocument" SG_ 2566844449 EngPTOSetSwitch "J1939-71";
BA_ "Variable" SG_ 2566844449 EngRmtPTOVriableSpeedCtrlSwitch "Com_stPTOVSpdSwt";
BA_ "Status" SG_ 2566844449 EngRmtPTOVriableSpeedCtrlSwitch "3.1.0";
BA_ "SigType" SG_ 2566844449 EngRmtPTOVriableSpeedCtrlSwitch "DISCRETE";
BA_ "SPN" SG_ 2566844449 EngRmtPTOVriableSpeedCtrlSwitch 978;
BA_ "SAEDocument" SG_ 2566844449 EngRmtPTOVriableSpeedCtrlSwitch "J1939-71";
BA_ "Variable" SG_ 2566844449 EngRmtPTOPrprgrmmdSpdCtrlSwitch "Com_stPTOPrePrgSpdSwt";
BA_ "Status" SG_ 2566844449 EngRmtPTOPrprgrmmdSpdCtrlSwitch "3.1.0";
BA_ "SigType" SG_ 2566844449 EngRmtPTOPrprgrmmdSpdCtrlSwitch "DISCRETE";
BA_ "SPN" SG_ 2566844449 EngRmtPTOPrprgrmmdSpdCtrlSwitch 979;
BA_ "SAEDocument" SG_ 2566844449 EngRmtPTOPrprgrmmdSpdCtrlSwitch "J1939-71";
BA_ "Variable" SG_ 2566844449 EngPTOEnableSwitch "Com_stPTOEnaSwt";
BA_ "Status" SG_ 2566844449 EngPTOEnableSwitch "3.1.0";
BA_ "SigType" SG_ 2566844449 EngPTOEnableSwitch "DISCRETE";
BA_ "SPN" SG_ 2566844449 EngPTOEnableSwitch 980;
BA_ "SAEDocument" SG_ 2566844449 EngPTOEnableSwitch "J1939-71";
BA_ "SigType" SG_ 2566844449 RmtPTOPrprgrmmdSpeedCtrlSwitch2 "DISCRETE";
BA_ "SPN" SG_ 2566844449 RmtPTOPrprgrmmdSpeedCtrlSwitch2 3447;
BA_ "SAEDocument" SG_ 2566844449 RmtPTOPrprgrmmdSpeedCtrlSwitch2 "J1939-71";
BA_ "Status" SG_ 2566844449 RmtPTOPrprgrmmdSpeedCtrlSwitch2 "Not needed";
BA_ "SigType" SG_ 2633937664 TripAverageFuelRate "RANGE";
BA_ "SPN" SG_ 2633937664 TripAverageFuelRate 1029;
BA_ "SAEDocument" SG_ 2633937664 TripAverageFuelRate "J1939-71";
BA_ "Status" SG_ 2633937664 TripAverageFuelRate "Not needed";
BA_ "Status" SG_ 2633937664 TotalEngPTOFuelUsed "2.3.0";
BA_ "SigType" SG_ 2633937664 TotalEngPTOFuelUsed "RANGE";
BA_ "SPN" SG_ 2633937664 TotalEngPTOFuelUsed 1028;
BA_ "SAEDocument" SG_ 2633937664 TotalEngPTOFuelUsed "J1939-71";
BA_ "Variable" SG_ 2633937664 TotalEngPTOFuelUsed "FlSys_volPTOFlConsTot";
BA_ "SPN" SG_ 2566831360 EstPctFanSpeed 975;
BA_ "Variable" SG_ 2566831360 EstPctFanSpeed "Com_rFanPrc";
BA_ "Status" SG_ 2566831360 EstPctFanSpeed "2.3.0";
BA_ "SigType" SG_ 2566831360 FanSpeed "RANGE";
BA_ "SPN" SG_ 2566831360 FanSpeed 1639;
BA_ "SAEDocument" SG_ 2566831360 FanSpeed "J1939-71";
BA_ "Variable" SG_ 2566831360 FanSpeed "Fan_n";
BA_ "Status" SG_ 2566831360 FanSpeed "2.3.0";
BA_ "SigType" SG_ 2566831360 FanDriveState "DISCRETE";
BA_ "SPN" SG_ 2566831360 FanDriveState 977;
BA_ "SAEDocument" SG_ 2566831360 FanDriveState "J1939-71";
BA_ "Variable" SG_ 2566831360 FanDriveState "Com_stFanDrv";
BA_ "Status" SG_ 2566831360 FanDriveState "2.3.0";
BA_ "SigType" SG_ 2565866755 TransCurrentRange "RANGE";
BA_ "SPN" SG_ 2565866755 TransCurrentRange 163;
BA_ "SAEDocument" SG_ 2565866755 TransCurrentRange "J1939-71";
BA_ "Status" SG_ 2565866755 TransCurrentRange "Not needed";
BA_ "SigType" SG_ 2565866755 TransRqedRange "RANGE";
BA_ "SPN" SG_ 2565866755 TransRqedRange 162;
BA_ "SAEDocument" SG_ 2565866755 TransRqedRange "J1939-71";
BA_ "Status" SG_ 2565866755 TransRqedRange "Not needed";
BA_ "Variable" SG_ 2565866755 TransCurrentGear "Com_numGear";
BA_ "SigType" SG_ 2565866755 TransCurrentGear "RANGE";
BA_ "SPN" SG_ 2565866755 TransCurrentGear 523;
BA_ "SAEDocument" SG_ 2565866755 TransCurrentGear "J1939-71";
BA_ "Status" SG_ 2565866755 TransCurrentGear "2.1.0";
BA_ "Variable" SG_ 2565866755 TransSelectedGear "Com_numGearTrgt";
BA_ "SigType" SG_ 2565866755 TransSelectedGear "RANGE";
BA_ "SPN" SG_ 2565866755 TransSelectedGear 524;
BA_ "SAEDocument" SG_ 2565866755 TransSelectedGear "J1939-71";
BA_ "Status" SG_ 2565866755 TransSelectedGear "2.1.0";
BA_ "Status" SG_ 2364539395 SA_CtrlDev_TransCtrl "Not needed";
BA_ "SigType" SG_ 2364539395 SA_CtrlDev_TransCtrl "RANGE";
BA_ "SPN" SG_ 2364539395 SA_CtrlDev_TransCtrl 1482;
BA_ "SAEDocument" SG_ 2364539395 SA_CtrlDev_TransCtrl "J1939-73";
BA_ "Status" SG_ 2364539395 TransInputShaftSpeed "Not needed";
BA_ "SigType" SG_ 2364539395 TransInputShaftSpeed "RANGE";
BA_ "SPN" SG_ 2364539395 TransInputShaftSpeed 161;
BA_ "SAEDocument" SG_ 2364539395 TransInputShaftSpeed "J1939-71";
BA_ "Variable" SG_ 2364539395 ProgressiveShiftDisable "Com_stProgShftDsbl";
BA_ "Status" SG_ 2364539395 ProgressiveShiftDisable "3.1.0";
BA_ "SAEDocument" SG_ 2364539395 ProgressiveShiftDisable "J1939-71";
BA_ "SPN" SG_ 2364539395 ProgressiveShiftDisable 607;
BA_ "SAEDocument" SG_ 2364539395 EngineMomOverspdEnable "J1939-71";
BA_ "SPN" SG_ 2364539395 EngineMomOverspdEnable 606;
BA_ "Variable" SG_ 2364539395 EngineMomOverspdEnable "Com_stOvrSpdDem";
BA_ "Status" SG_ 2364539395 EngineMomOverspdEnable "2.1.0";
BA_ "Variable" SG_ 2364539395 TransOutputShaftSpeed "Com_nSpd";
BA_ "SigType" SG_ 2364539395 TransOutputShaftSpeed "RANGE";
BA_ "SPN" SG_ 2364539395 TransOutputShaftSpeed 191;
BA_ "SAEDocument" SG_ 2364539395 TransOutputShaftSpeed "J1939-71";
BA_ "Status" SG_ 2364539395 TransOutputShaftSpeed "2.1.0";
BA_ "Variable" SG_ 2364539395 TransShiftInProcess "Com_bGearShftActv";
BA_ "SigType" SG_ 2364539395 TransShiftInProcess "DISCRETE";
BA_ "SPN" SG_ 2364539395 TransShiftInProcess 574;
BA_ "SAEDocument" SG_ 2364539395 TransShiftInProcess "J1939-71";
BA_ "Status" SG_ 2364539395 TransShiftInProcess "2.1.0";
BA_ "Variable" SG_ 2364539395 TorqueConverterLockupEngaged "Com_stETC1TrqCnvLckUp";
BA_ "SigType" SG_ 2364539395 TorqueConverterLockupEngaged "DISCRETE";
BA_ "SPN" SG_ 2364539395 TorqueConverterLockupEngaged 573;
BA_ "SAEDocument" SG_ 2364539395 TorqueConverterLockupEngaged "J1939-71";
BA_ "Status" SG_ 2364539395 TorqueConverterLockupEngaged "2.1.0";
BA_ "Variable" SG_ 2364539395 TransDrivelineEngaged "Com_stDrvTrnEgd";
BA_ "SigType" SG_ 2364539395 TransDrivelineEngaged "DISCRETE";
BA_ "SPN" SG_ 2364539395 TransDrivelineEngaged 560;
BA_ "SAEDocument" SG_ 2364539395 TransDrivelineEngaged "J1939-71";
BA_ "Status" SG_ 2364539395 TransDrivelineEngaged "2.1.0";
BA_ "Variable" SG_ 2566809856 EngChargeAirCoolerOutletTemp "Air_tSensTCACDs";
BA_ "SigType" SG_ 2566809856 EngChargeAirCoolerOutletTemp "RANGE";
BA_ "SPN" SG_ 2566809856 EngChargeAirCoolerOutletTemp 2630;
BA_ "SAEDocument" SG_ 2566809856 EngChargeAirCoolerOutletTemp "J1939-71";
BA_ "Status" SG_ 2566809856 EngChargeAirCoolerOutletTemp "2.1.0";
BA_ "Variable" SG_ 2566809856 EngIntakeManifold1AirTemp "Air_tSensTIntkVUs";
BA_ "SigType" SG_ 2566809856 EngIntakeManifold1AirTemp "RANGE";
BA_ "SPN" SG_ 2566809856 EngIntakeManifold1AirTemp 1636;
BA_ "SAEDocument" SG_ 2566809856 EngIntakeManifold1AirTemp "J1939-71";
BA_ "Status" SG_ 2566809856 EngIntakeManifold1AirTemp "2.1.0";
BA_ "SAEDocument" SG_ 2566824960 EngOilTemp2 "J1939-71";
BA_ "SPN" SG_ 2566824960 EngOilTemp2 1135;
BA_ "SigType" SG_ 2566824960 EngOilTemp2 "RANGE";
BA_ "Variable" SG_ 2566824960 EngOilTemp2 "OilTSmp_tSens";
BA_ "Status" SG_ 2566824960 EngOilTemp2 "3.4.6";
BA_ "Variable" SG_ 2566824960 EngExhaustGasRecirculationTemp "Air_tSensTEGRClrDs";
BA_ "Status" SG_ 2566824960 EngExhaustGasRecirculationTemp "2.5.0";
BA_ "SigType" SG_ 2566824960 EngExhaustGasRecirculationTemp "RANGE";
BA_ "SPN" SG_ 2566824960 EngExhaustGasRecirculationTemp 412;
BA_ "SAEDocument" SG_ 2566824960 EngExhaustGasRecirculationTemp "J1939-71";
BA_ "SigType" SG_ 2566824960 EngEGRDiffPress "RANGE";
BA_ "SPN" SG_ 2566824960 EngEGRDiffPress 411;
BA_ "SAEDocument" SG_ 2566824960 EngEGRDiffPress "J1939-71";
BA_ "Status" SG_ 2566824960 EngEGRDiffPress "Not needed";
BA_ "SigType" SG_ 2566843904 EngIntercoolerThermostatOpening "RANGE";
BA_ "SPN" SG_ 2566843904 EngIntercoolerThermostatOpening 1134;
BA_ "SAEDocument" SG_ 2566843904 EngIntercoolerThermostatOpening "J1939-71";
BA_ "Status" SG_ 2566843904 EngIntercoolerThermostatOpening "Not needed";
BA_ "SigType" SG_ 2566843904 EngIntercoolerTemp "RANGE";
BA_ "SPN" SG_ 2566843904 EngIntercoolerTemp 52;
BA_ "SAEDocument" SG_ 2566843904 EngIntercoolerTemp "J1939-71";
BA_ "Status" SG_ 2566843904 EngIntercoolerTemp "Not needed";
BA_ "SigType" SG_ 2566843904 EngTurboOilTemp "RANGE";
BA_ "SPN" SG_ 2566843904 EngTurboOilTemp 176;
BA_ "SAEDocument" SG_ 2566843904 EngTurboOilTemp "J1939-71";
BA_ "Status" SG_ 2566843904 EngTurboOilTemp "Not needed";
BA_ "Variable" SG_ 2566843904 EngOilTemp1 "OilT_tSwmp";
BA_ "SigType" SG_ 2566843904 EngOilTemp1 "RANGE";
BA_ "SPN" SG_ 2566843904 EngOilTemp1 175;
BA_ "SAEDocument" SG_ 2566843904 EngOilTemp1 "J1939-71";
BA_ "Status" SG_ 2566843904 EngOilTemp1 "2.1.0";
BA_ "Variable" SG_ 2566843904 EngFuelTemp "FuelT_t";
BA_ "SigType" SG_ 2566843904 EngFuelTemp "RANGE";
BA_ "SPN" SG_ 2566843904 EngFuelTemp 174;
BA_ "SAEDocument" SG_ 2566843904 EngFuelTemp "J1939-71";
BA_ "Status" SG_ 2566843904 EngFuelTemp "2.1.0";
BA_ "Variable" SG_ 2566843904 EngCoolantTemp "CEngDsT_tSens";
BA_ "SigType" SG_ 2566843904 EngCoolantTemp "RANGE";
BA_ "SPN" SG_ 2566843904 EngCoolantTemp 110;
BA_ "SAEDocument" SG_ 2566843904 EngCoolantTemp "J1939-71";
BA_ "Status" SG_ 2566843904 EngCoolantTemp "2.3.0";
BA_ "Variable" SG_ 2565865487 IntendedRetarderPercentTorque "Com_dERC1DesRtdrTrqPrc";
BA_ "SAEDocument" SG_ 2565865487 IntendedRetarderPercentTorque "J1939_71";
BA_ "SPN" SG_ 2565865487 IntendedRetarderPercentTorque 1085;
BA_ "SigType" SG_ 2565865487 IntendedRetarderPercentTorque "RANGE";
BA_ "Status" SG_ 2565865487 IntendedRetarderPercentTorque "Not needed";
BA_ "Variable" SG_ 2565865487 RetarderTorqueMode "Com_stERC1RtdrTrqMode";
BA_ "SigType" SG_ 2565865487 RetarderTorqueMode "DISCREET";
BA_ "SPN" SG_ 2565865487 RetarderTorqueMode 900;
BA_ "SAEDocument" SG_ 2565865487 RetarderTorqueMode "SAE J1939_71";
BA_ "Status" SG_ 2565865487 RetarderTorqueMode "Not needed";
BA_ "SAEDocument" SG_ 2565865487 RetarderEnableShiftAssistSwitch "SAE J1971";
BA_ "SPN" SG_ 2565865487 RetarderEnableShiftAssistSwitch 572;
BA_ "SigType" SG_ 2565865487 RetarderEnableShiftAssistSwitch "DISCREET";
BA_ "Status" SG_ 2565865487 RetarderEnableShiftAssistSwitch "Not needed";
BA_ "SigType" SG_ 2565865487 RetarderEnableBrakeAssistSwitch "DISCREET";
BA_ "SPN" SG_ 2565865487 RetarderEnableBrakeAssistSwitch 571;
BA_ "SAEDocument" SG_ 2565865487 RetarderEnableBrakeAssistSwitch "SAE J1939_71";
BA_ "Variable" SG_ 2565865487 RetarderEnableBrakeAssistSwitch "AccPed_rEngRtdr > 0";
BA_ "Status" SG_ 2565865487 RetarderEnableBrakeAssistSwitch "3.4.0";
BA_ "Variable" SG_ 2565865487 ActualRetarderPercentTorque "Com_dERC1ActRtdrTrqPrc";
BA_ "SigType" SG_ 2565865487 ActualRetarderPercentTorque "RANGE";
BA_ "SPN" SG_ 2565865487 ActualRetarderPercentTorque 520;
BA_ "SAEDocument" SG_ 2565865487 ActualRetarderPercentTorque "J1939-71";
BA_ "Status" SG_ 2565865487 ActualRetarderPercentTorque "3.2.0";
BA_ "Variable" SG_ 2633937152 TotalECURunTime "GlbDa_tiECUOn";
BA_ "SigType" SG_ 2633937152 TotalECURunTime "RANGE";
BA_ "SPN" SG_ 2633937152 TotalECURunTime 1033;
BA_ "SAEDocument" SG_ 2633937152 TotalECURunTime "J1939-71";
BA_ "Status" SG_ 2633937152 TotalECURunTime "2.1.0";
BA_ "Variable" SG_ 2633937152 TotalECUDistance "Com_lTotECUDstEH";
BA_ "Status" SG_ 2633937152 TotalECUDistance "Requested 3.7.0";
BA_ "SigType" SG_ 2633937152 TotalECUDistance "RANGE";
BA_ "SPN" SG_ 2633937152 TotalECUDistance 1032;
BA_ "SAEDocument" SG_ 2633937152 TotalECUDistance "J1939-71";
BA_ "Status" SG_ 2364541440 EngInletAirMassFlowRate "2.4.0";
BA_ "SigType" SG_ 2364541440 EngInletAirMassFlowRate "RANGE";
BA_ "SPN" SG_ 2364541440 EngInletAirMassFlowRate 132;
BA_ "SAEDocument" SG_ 2364541440 EngInletAirMassFlowRate "J1939-71";
BA_ "Variable" SG_ 2364541440 EngInletAirMassFlowRate "AFS_dm";
BA_ "SigType" SG_ 2364541440 EngExhstGsRcrcltionMassFlowRate "RANGE";
BA_ "SPN" SG_ 2364541440 EngExhstGsRcrcltionMassFlowRate 2659;
BA_ "SAEDocument" SG_ 2364541440 EngExhstGsRcrcltionMassFlowRate "J1939-71";
BA_ "Status" SG_ 2364541440 EngExhstGsRcrcltionMassFlowRate "Not needed";
BA_ "Status" SG_ 2566839040 EngInjectorMeteringRail1Press "Requested 3.7.0";
BA_ "Variable" SG_ 2566839040 EngInjectorMeteringRail1Press "RailP_pLin";
BA_ "SigType" SG_ 2566839040 EngInjectorMeteringRail1Press "RANGE";
BA_ "SPN" SG_ 2566839040 EngInjectorMeteringRail1Press 157;
BA_ "SAEDocument" SG_ 2566839040 EngInjectorMeteringRail1Press "J1939-71";
BA_ "SAEDocument" SG_ 2566844160 EngCrankcasePress "J1939-71";
BA_ "SPN" SG_ 2566844160 EngCrankcasePress 101;
BA_ "SigType" SG_ 2566844160 EngCrankcasePress "RANGE";
BA_ "Variable" SG_ 2566844160 EngCrankcasePress "CrCsP_pSens";
BA_ "Status" SG_ 2566844160 EngCrankcasePress "3.5.0";
BA_ "SAEDocument" SG_ 2566844160 EngOilLevel "J1939-71";
BA_ "SPN" SG_ 2566844160 EngOilLevel 98;
BA_ "SigType" SG_ 2566844160 EngOilLevel "RANGE";
BA_ "Variable" SG_ 2566844160 EngOilLevel "OilLvl_rEngOil";
BA_ "Status" SG_ 2566844160 EngOilLevel "3.2.0";
BA_ "Variable" SG_ 2566844160 EngCoolantLevel "ClntLv_stChk";
BA_ "SigType" SG_ 2566844160 EngCoolantLevel "RANGE";
BA_ "SPN" SG_ 2566844160 EngCoolantLevel 111;
BA_ "SAEDocument" SG_ 2566844160 EngCoolantLevel "J1939-71";
BA_ "Status" SG_ 2566844160 EngCoolantLevel "3.5.0";
BA_ "Variable" SG_ 2566844160 EngOilPress "Oil_pSwmp";
BA_ "SigType" SG_ 2566844160 EngOilPress "RANGE";
BA_ "SPN" SG_ 2566844160 EngOilPress 100;
BA_ "SAEDocument" SG_ 2566844160 EngOilPress "J1939-71";
BA_ "Status" SG_ 2566844160 EngOilPress "Requested 3.7.0";
BA_ "SigType" SG_ 2566844160 EngExCrankcaseBlowbyPress "RANGE";
BA_ "SPN" SG_ 2566844160 EngExCrankcaseBlowbyPress 22;
BA_ "SAEDocument" SG_ 2566844160 EngExCrankcaseBlowbyPress "J1939-71";
BA_ "Status" SG_ 2566844160 EngExCrankcaseBlowbyPress "Not needed";
BA_ "Variable" SG_ 2566844160 EngFuelDeliveryPress "Fl_pFuelP";
BA_ "SigType" SG_ 2566844160 EngFuelDeliveryPress "RANGE";
BA_ "SPN" SG_ 2566844160 EngFuelDeliveryPress 94;
BA_ "SAEDocument" SG_ 2566844160 EngFuelDeliveryPress "J1939-71";
BA_ "Status" SG_ 2566844160 EngFuelDeliveryPress "2.1.0";
BA_ "Status" SG_ 2566771968 EngFuelControlStatus "3.4.0";
BA_ "SigType" SG_ 2566771968 EngFuelControlStatus "DISCRETE";
BA_ "SPN" SG_ 2566771968 EngFuelControlStatus 5323;
BA_ "SAEDocument" SG_ 2566771968 EngFuelControlStatus "J1939-71";
BA_ "Variable" SG_ 2566771968 EngFuelControlStatus "Com_swtRailCtlLoop";
BA_ "Variable" SG_ 2566771968 EngExhstGsRcirculationValveCtrl "EGRVlv_rPs";
BA_ "SigType" SG_ 2566771968 EngExhstGsRcirculationValveCtrl "RANGE";
BA_ "SPN" SG_ 2566771968 EngExhstGsRcirculationValveCtrl 2791;
BA_ "SAEDocument" SG_ 2566771968 EngExhstGsRcirculationValveCtrl "J1939-71";
BA_ "Status" SG_ 2566771968 EngExhstGsRcirculationValveCtrl "3.4.6";
BA_ "Variable" SG_ 2566840064 ExhaustGasMass "Com_dmEGMnfDs (ASMod_dmExhMnfDs)";
BA_ "SigType" SG_ 2566840064 ExhaustGasMass "RANGE";
BA_ "SPN" SG_ 2566840064 ExhaustGasMass 3236;
BA_ "SAEDocument" SG_ 2566840064 ExhaustGasMass "J1939-71";
BA_ "Status" SG_ 2566840064 ExhaustGasMass "3.5.0";
BA_ "Variable" SG_ 2566840064 EstEngPrsticLossesPercentTorque "Com_rEstEngLos";
BA_ "SigType" SG_ 2566840064 EstEngPrsticLossesPercentTorque "RANGE";
BA_ "SPN" SG_ 2566840064 EstEngPrsticLossesPercentTorque 2978;
BA_ "SAEDocument" SG_ 2566840064 EstEngPrsticLossesPercentTorque "J1939-71";
BA_ "Status" SG_ 2566840064 EstEngPrsticLossesPercentTorque "2.1.0";
BA_ "Variable" SG_ 2566840064 EngsDesiredOperatingSpeed "Com_nEngDesOpSpd";
BA_ "SigType" SG_ 2566840064 EngsDesiredOperatingSpeed "RANGE";
BA_ "SPN" SG_ 2566840064 EngsDesiredOperatingSpeed 515;
BA_ "SAEDocument" SG_ 2566840064 EngsDesiredOperatingSpeed "J1939-71";
BA_ "Status" SG_ 2566840064 EngsDesiredOperatingSpeed "2.1.0";
BA_ "Variable" SG_ 2566840064 NominalFrictionPercentTorque "Com_rNomFrc";
BA_ "SigType" SG_ 2566840064 NominalFrictionPercentTorque "RANGE";
BA_ "SPN" SG_ 2566840064 NominalFrictionPercentTorque 514;
BA_ "SAEDocument" SG_ 2566840064 NominalFrictionPercentTorque "J1939-71";
BA_ "Status" SG_ 2566840064 NominalFrictionPercentTorque "2.1.0";
BA_ "SigType" SG_ 2364539648 AccelPedalPos2 "RANGE";
BA_ "SPN" SG_ 2364539648 AccelPedalPos2 29;
BA_ "SAEDocument" SG_ 2364539648 AccelPedalPos2 "J1939-71";
BA_ "Status" SG_ 2364539648 AccelPedalPos2 "Not needed";
BA_ "Variable" SG_ 2364539648 EngPercentLoadAtCurrentSpeed "Com_rEngTrqLoad";
BA_ "SigType" SG_ 2364539648 EngPercentLoadAtCurrentSpeed "RANGE";
BA_ "SPN" SG_ 2364539648 EngPercentLoadAtCurrentSpeed 92;
BA_ "SAEDocument" SG_ 2364539648 EngPercentLoadAtCurrentSpeed "J1939-71";
BA_ "Status" SG_ 2364539648 EngPercentLoadAtCurrentSpeed "2.1.0";
BA_ "Variable" SG_ 2364539648 RoadSpeedLimitStatus "Com_stVehSpdLim";
BA_ "SigType" SG_ 2364539648 RoadSpeedLimitStatus "DISCRETE";
BA_ "SPN" SG_ 2364539648 RoadSpeedLimitStatus 1437;
BA_ "SAEDocument" SG_ 2364539648 RoadSpeedLimitStatus "J1939-71";
BA_ "Status" SG_ 2364539648 RoadSpeedLimitStatus "2.1.0";
BA_ "Variable" SG_ 2364539648 AccelPedal1LowIdleSwitch "Com_stLISActv";
BA_ "SigType" SG_ 2364539648 AccelPedal1LowIdleSwitch "DISCRETE";
BA_ "SPN" SG_ 2364539648 AccelPedal1LowIdleSwitch 558;
BA_ "SAEDocument" SG_ 2364539648 AccelPedal1LowIdleSwitch "J1939-71";
BA_ "Status" SG_ 2364539648 AccelPedal1LowIdleSwitch "2.1.0";
BA_ "Variable" SG_ 2364539648 RemoteAccelPedalPos "RmtAPP_r";
BA_ "Status" SG_ 2364539648 RemoteAccelPedalPos "3.4.0";
BA_ "SigType" SG_ 2364539648 RemoteAccelPedalPos "RANGE";
BA_ "SPN" SG_ 2364539648 RemoteAccelPedalPos 974;
BA_ "SAEDocument" SG_ 2364539648 RemoteAccelPedalPos "J1939-71";
BA_ "Variable" SG_ 2364539648 AccelPedalPos1 "APP_r";
BA_ "SigType" SG_ 2364539648 AccelPedalPos1 "RANGE";
BA_ "SPN" SG_ 2364539648 AccelPedalPos1 91;
BA_ "SAEDocument" SG_ 2364539648 AccelPedalPos1 "J1939-71";
BA_ "Status" SG_ 2364539648 AccelPedalPos1 "2.1.0";
BA_ "SAEDocument" SG_ 2364539904 SA_CtrlDev_EngCtrl "J1939-73";
BA_ "SPN" SG_ 2364539904 SA_CtrlDev_EngCtrl 1483;
BA_ "SigType" SG_ 2364539904 SA_CtrlDev_EngCtrl "RANGE";
BA_ "Status" SG_ 2364539904 SA_CtrlDev_EngCtrl "3.4.n";
BA_ "Variable" SG_ 2364539904 EngDemandPercentTorque "Com_rEngDemTrq";
BA_ "SigType" SG_ 2364539904 EngDemandPercentTorque "RANGE";
BA_ "SPN" SG_ 2364539904 EngDemandPercentTorque 2432;
BA_ "SAEDocument" SG_ 2364539904 EngDemandPercentTorque "J1939-71";
BA_ "Status" SG_ 2364539904 EngDemandPercentTorque "2.1.0";
BA_ "Variable" SG_ 2364539904 EngStarterMode "StSys_stCAN";
BA_ "SigType" SG_ 2364539904 EngStarterMode "DISCRETE";
BA_ "SPN" SG_ 2364539904 EngStarterMode 1675;
BA_ "SAEDocument" SG_ 2364539904 EngStarterMode "J1939-71";
BA_ "Status" SG_ 2364539904 EngStarterMode "2.1.0";
BA_ "Variable" SG_ 2364539904 EngSpeed "Epm_nEng";
BA_ "SigType" SG_ 2364539904 EngSpeed "RANGE";
BA_ "SPN" SG_ 2364539904 EngSpeed 190;
BA_ "SAEDocument" SG_ 2364539904 EngSpeed "J1939-71";
BA_ "Status" SG_ 2364539904 EngSpeed "2.1.0";
BA_ "Variable" SG_ 2364539904 ActualEngPercentTorque "Com_rActEngTrq";
BA_ "SigType" SG_ 2364539904 ActualEngPercentTorque "RANGE";
BA_ "SPN" SG_ 2364539904 ActualEngPercentTorque 513;
BA_ "SAEDocument" SG_ 2364539904 ActualEngPercentTorque "J1939-71";
BA_ "Status" SG_ 2364539904 ActualEngPercentTorque "2.1.0";
BA_ "Variable" SG_ 2364539904 DriversDemandEngPercentTorque "Com_dDrvDemTrq";
BA_ "SigType" SG_ 2364539904 DriversDemandEngPercentTorque "RANGE";
BA_ "SPN" SG_ 2364539904 DriversDemandEngPercentTorque 512;
BA_ "SAEDocument" SG_ 2364539904 DriversDemandEngPercentTorque "J1939-71";
BA_ "Status" SG_ 2364539904 DriversDemandEngPercentTorque "2.1.0";
BA_ "Variable" SG_ 2364539904 EngTorqueMode "Com_stEngTrqMode";
BA_ "SigType" SG_ 2364539904 EngTorqueMode "DISCRETE";
BA_ "SPN" SG_ 2364539904 EngTorqueMode 899;
BA_ "SAEDocument" SG_ 2364539904 EngTorqueMode "J1939-71";
BA_ "Status" SG_ 2364539904 EngTorqueMode "2.1.0";
VAL_ 2566832128 SPN_0911 255 "Component ID not available" 254 "Error" 253 "No action to be taken" 252 "Reset all components" 251 "Reserved" 250 "Reserved" 249 "Manufacturer specific" 248 "Manufacturer specific" 247 "Manufacturer specific" 246 "Manufacturer specific" 245 "Manufacturer specific" 244 "Manufacturer specific" 243 "Manufacturer specific" 242 "Manufacturer specific" 241 "Manufacturer specific" 240 "Manufacturer specific" 239 "Not defined" 238 "Not defined" 237 "Not defined" 236 "Not defined" 235 "Not defined" 234 "Not defined" 233 "Not defined" 232 "Not defined" 231 "Not defined" 230 "Not defined" 229 "Not defined" 228 "Not defined" 227 "Not defined" 226 "Not defined" 225 "Not defined" 224 "Not defined" 223 "Not defined" 222 "Not defined" 221 "Not defined" 220 "Not defined" 219 "Not defined" 218 "Not defined" 217 "Not defined" 216 "Not defined" 215 "Not defined" 214 "Not defined" 213 "Not defined" 212 "Not defined" 211 "Not defined" 210 "Not defined" 209 "Not defined" 208 "Not defined" 207 "Not defined" 206 "Not defined" 205 "Not defined" 204 "Not defined" 203 "Not defined" 202 "Not defined" 201 "Not defined" 200 "Not defined" 199 "Not defined" 198 "Not defined" 197 "Not defined" 196 "Not defined" 195 "Not defined" 194 "Not defined" 193 "Not defined" 192 "Not defined" 191 "Not defined" 190 "Not defined" 189 "Not defined" 188 "Not defined" 187 "Not defined" 186 "Not defined" 185 "Not defined" 184 "Not defined" 183 "Not defined" 182 "Not defined" 181 "Not defined" 180 "Not defined" 179 "Not defined" 178 "Not defined" 177 "Not defined" 176 "Not defined" 175 "Not defined" 174 "Not defined" 173 "Not defined" 172 "Not defined" 171 "Not defined" 170 "Not defined" 169 "Not defined" 168 "Not defined" 167 "Not defined" 166 "Not defined" 165 "Not defined" 164 "Not defined" 163 "Not defined" 162 "Not defined" 161 "Not defined" 160 "Not defined" 159 "Not defined" 158 "Not defined" 157 "Not defined" 156 "Not defined" 155 "Not defined" 154 "Not defined" 153 "Not defined" 152 "Not defined" 151 "Not defined" 150 "Not defined" 149 "Not defined" 148 "Not defined" 147 "Not defined" 146 "Not defined" 145 "Not defined" 144 "Not defined" 143 "Not defined" 142 "Not defined" 141 "Not defined" 140 "Not defined" 139 "Not defined" 138 "Not defined" 137 "Not defined" 136 "Not defined" 135 "Not defined" 134 "Not defined" 133 "Not defined" 132 "Not defined" 131 "Not defined" 130 "Not defined" 129 "Not defined" 128 "Not defined" 127 "Not defined" 126 "Not defined" 125 "Not defined" 124 "Not defined" 123 "Not defined" 122 "Not defined" 121 "Not defined" 120 "Not defined" 119 "Not defined" 118 "Not defined" 117 "Not defined" 116 "Not defined" 115 "Not defined" 114 "Not defined" 113 "Not defined" 112 "Not defined" 111 "Not defined" 110 "Not defined" 109 "Not defined" 108 "Not defined" 107 "Not defined" 106 "Not defined" 105 "Not defined" 104 "Not defined" 103 "Not defined" 102 "Not defined" 101 "Not defined" 100 "Not defined" 99 "Not defined" 98 "Not defined" 97 "Not defined" 96 "Not defined" 95 "Not defined" 94 "Not defined" 93 "Not defined" 92 "Not defined" 91 "Not defined" 90 "Not defined" 89 "Not defined" 88 "Not defined" 87 "Not defined" 86 "Not defined" 85 "Not defined" 84 "Not defined" 83 "Not defined" 82 "Not defined" 81 "Not defined" 80 "Not defined" 79 "Not defined" 78 "Not defined" 77 "Not defined" 76 "Not defined" 75 "Not defined" 74 "Not defined" 73 "Not defined" 72 "Not defined" 71 "Not defined" 70 "Not defined" 69 "Not defined" 68 "Not defined" 67 "Not defined" 66 "Not defined" 65 "Not defined" 64 "Not defined" 63 "Driver card #2" 62 "Driver card #1" 61 "Tachograph" 60 "Not defined" 59 "Not defined" 58 "Not defined" 57 "Not defined" 56 "Not defined" 55 "Not defined" 54 "Not defined" 53 "Not defined" 52 "Not defined" 51 "Engine fuel filter" 50 "Engine oil filter" 49 "Engine air filter" 48 "Tires" 47 "Not defined" 46 "Not defined" 45 "Not defined" 44 "Not defined" 43 "Rear axle oil" 42 "Front axle oil" 41 "Not defined" 40 "Intermediate transmission oil" 39 "Trans oil filter transmission #1" 38 "Trans oil transmission #2" 37 "Trans oil transmission #1" 36 "Not defined" 35 "Steering oil" 34 "Not defined" 33 "Engine oil engine #2" 32 "Engine oil engine #1" 31 "Engine coolant filter change" 30 "Engine coolant change" 29 "Not defined" 28 "Not defined" 27 "Not defined" 26 "Not defined" 25 "Not defined" 24 "Not defined" 23 "Not defined" 22 "Not defined" 21 "Check vehicle speed limiter" 20 "Check exhaust gas" 19 "Check trip recorder" 18 "In-between check" 17 "Brake system special check" 16 "Reg. gen. check for entire veh." 15 "Brake lining: general" 14 "Brake lining; right rear axle #3" 13 "Brake lining; left rear axle #3" 12 "Brake lining; right rear axle #2" 11 "Brake lining; left rear axle #2" 10 "Not defined" 9 "Not defined" 8 "Not defined" 7 "Not defined" 6 "Not defined" 5 "Clutch lining" 4 "Brake lining; right rear axle" 3 "Brake lining; left rear axle" 2 "Brake lining; right front axle" 1 "Brake lining; left front axle" 0 "Service check for entire vehicle" ;
VAL_ 2564751360 HoldSignal 15 "Not available" 1 "Devices whose broadcast state ha" 0 "All devices" ;
VAL_ 2564751360 J1939Network3 3 "Don't care" 2 "Reserved" 1 "Start broadcast" 0 "Stop broadcast" ;
VAL_ 2564751360 J1939Network2 3 "Don't care" 2 "Reserved" 1 "Start broadcast" 0 "Stop broadcast" ;
VAL_ 2564751360 ISO9141 3 "Don't care" 2 "Reserved" 1 "Start broadcast" 0 "Stop broadcast" ;
VAL_ 2564751360 SAE_J1850 3 "Don't care" 2 "Reserved" 1 "Start broadcast" 0 "Stop broadcast" ;
VAL_ 2564751360 ManufacturerSpecificPort 3 "Don't care" 2 "Reserved" 1 "Start broadcast" 0 "Stop broadcast" ;
VAL_ 2564751360 CurrentDataLink 3 "Don't care" 2 "Reserved" 1 "Start broadcast" 0 "Stop broadcast" ;
VAL_ 2564751360 SAE_J1587 3 "Don't care" 2 "Reserved" 1 "Start broadcast" 0 "Stop broadcast" ;
VAL_ 2564751360 SAE_J1922 3 "Don't care" 2 "Reserved" 1 "Start broadcast" 0 "Stop broadcast" ;
VAL_ 2564751360 J1939Network1 3 "Don't care" 2 "Reserved" 1 "Start broadcast" 0 "Stop broadcast" ;
VAL_ 2564751360 SuspendSignal 15 "NotAvailable" 14 "ResumingNormalBroadcastPattern" 3 "TemporarySuspensionOfSomeMessage" 2 "TemporarySuspensionOfAllBroadcas" 1 "IndefiniteSuspensionOfSomeMessag" 0 "IndefiniteSuspensionOfAllBroadca" ;
VAL_ 2566749184 PartTrActRegInhDuToColdEngine 3 "not available" 2 "reserved for SAE assignment" 1 "inhibited" 0 "not inhibited" ;
VAL_ 2566749184 PartTrActRegenStatus 3 "not available" 2 "RegenNeeded_AutoRegenImminent" 1 "active" 0 "not active" ;
VAL_ 2566749184 ParticulateTrapStatus 7 "not available" 6 "reserved for SAE assignment" 5 "reserved for SAE assignment" 4 "reserved for SAE assignment" 3 "Regen needed highest level" 2 "Regen needed moderate level" 1 "Regen needed lowest level" 0 "Regeneration not needed" ;
VAL_ 2566749184 ParticulateTrapLampCommand 7 "not available" 6 "reserved for SAE assignment" 5 "reserved for SAE assignment" 4 "On fast blink 1Hz" 3 "reserved for SAE assignment" 2 "reserved for SAE assignment" 1 "On Solid" 0 "Off" ;
VAL_ 2566749184 ExhSysHiTempLampCommand 7 "not available" 6 "reserved for SAE assignment" 5 "reserved for SAE assignment" 4 "On fast blink 1Hz" 3 "reserved for SAE assignment" 2 "reserved for SAE assignment" 1 "On Solid" 0 "Off" ;
VAL_ 2566749184 PartTrActRegInhibitedStatus 3 "not available" 2 "reserved for SAE assignment" 1 "inhibited" 0 "not inhibited" ;
VAL_ 2566749184 PartTrActRegInhibDuToVehSpdAbvLm 3 "not available" 2 "reserved for SAE assignment" 1 "inhibited" 0 "not inhibited" ;
VAL_ 2566749184 PartTrActRegInhibDuToSysFaultAct 3 "not available" 2 "reserved for SAE assignment" 1 "inhibited" 0 "not inhibited" ;
VAL_ 2566749184 PartTrActRegInhibDuToServBrakAct 3 "not available" 2 "reserved for SAE assignment" 1 "inhibited" 0 "not inhibited" ;
VAL_ 2566749184 PartTrActRegInhibDuToPTOActive 3 "not available" 2 "reserved for SAE assignment" 1 "inhibited" 0 "not inhibited" ;
VAL_ 2566749184 PartTrActRegInhibDuToPrkBrakNoSt 3 "not available" 2 "reserved for SAE assignment" 1 "inhibited" 0 "not inhibited" ;
VAL_ 2566749184 PartTrActRegInhibDuToPedalOffIdl 3 "not available" 2 "reserved for SAE assignment" 1 "inhibited" 0 "not inhibited" ;
VAL_ 2566749184 PartTrActRegInhibDuToOutOfNuetrl 3 "not available" 2 "reserved for SAE assignment" 1 "inhibited" 0 "not inhibited" ;
VAL_ 2566749184 PartTrActRegInhibDuToLowExhTemp 3 "not available" 2 "reserved for SAE assignment" 1 "inhibited" 0 "not inhibited" ;
VAL_ 2566749184 PartTrActRegInhibDuToInhibSwitch 3 "not available" 2 "reserved for SAE assignment" 1 "inhibited" 0 "not inhibited" ;
VAL_ 2566749184 PartTrActRegInhibDuToClutchDisen 3 "not available" 2 "reserved for SAE assignment" 1 "inhibited" 0 "not inhibited" ;
VAL_ 2565406464 ControlByte 24 "EAbort" 23 "EEoMACK" 22 "EDPO" 21 "ECTS" 20 "ERTS" 3 "CannotRespond" 2 "AccessDenied" 1 "NACK" 0 "ACK" 255 "Abort" 32 "BAM" 19 "EoMA" 17 "CTS" 16 "RTS" ;
VAL_ 2566834688 FailureModeIdentifier5 31 "Not available" 19 "Received network data in error" 18 "Below normal (moderatels severe)" 17 "Below normal (least severe)" 16 "Above normal (moderately severe)" 15 "Above normal (least severe)" 14 "Special intstructions" 13 "Out of calibration" 12 "Bad intelligent device" 11 "Root cause not known" 10 "Abnormal rate of change" 9 "Abnormal update rate" 8 "Abnormal frequency" 7 "Mechanical system not responding" 6 "Current above normal" 5 "Current below normal" 4 "Voltage below normal" 3 "Voltage above normal" 2 "Data erratic" 1 "Below normal (most severe)" 0 "Above normal (most severe)" ;
VAL_ 2566834688 FailureModeIdentifier4 31 "Not available" 19 "Received network data in error" 18 "Below normal (moderatels severe)" 17 "Below normal (least severe)" 16 "Above normal (moderately severe)" 15 "Above normal (least severe)" 14 "Special intstructions" 13 "Out of calibration" 12 "Bad intelligent device" 11 "Root cause not known" 10 "Abnormal rate of change" 9 "Abnormal update rate" 8 "Abnormal frequency" 7 "Mechanical system not responding" 6 "Current above normal" 5 "Current below normal" 4 "Voltage below normal" 3 "Voltage above normal" 2 "Data erratic" 1 "Below normal (most severe)" 0 "Above normal (most severe)" ;
VAL_ 2566834688 FailureModeIdentifier3 31 "Not available" 19 "Received network data in error" 18 "Below normal (moderatels severe)" 17 "Below normal (least severe)" 16 "Above normal (moderately severe)" 15 "Above normal (least severe)" 14 "Special intstructions" 13 "Out of calibration" 12 "Bad intelligent device" 11 "Root cause not known" 10 "Abnormal rate of change" 9 "Abnormal update rate" 8 "Abnormal frequency" 7 "Mechanical system not responding" 6 "Current above normal" 5 "Current below normal" 4 "Voltage below normal" 3 "Voltage above normal" 2 "Data erratic" 1 "Below normal (most severe)" 0 "Above normal (most severe)" ;
VAL_ 2566834688 FlashRedStopLamp 3 "Unavailable / Do Not Flash" 2 "Reserved" 1 "Fast Flash" 0 "Slow Flash" ;
VAL_ 2566834688 FlashProtectLamp 3 "Unavailable / Do Not Flash" 2 "Reserved" 1 "Fast Flash" 0 "Slow Flash" ;
VAL_ 2566834688 FlashMalfuncIndicatorLamp 3 "Unavailable / Do Not Flash" 2 "Reserved" 1 "Fast Flash" 0 "Slow Flash" ;
VAL_ 2566834688 FlashAmberWarningLamp 3 "Unavailable / Do Not Flash" 2 "Reserved" 1 "Fast Flash" 0 "Slow Flash" ;
VAL_ 2566834688 MalfunctionIndicatorLampStatus 3 "Not available" 2 "Reserved" 1 "Lamp on" 0 "Lamp off" ;
VAL_ 2566834688 AmberWarningLampStatus 3 "Not available" 2 "Reserved" 1 "Lamp on" 0 "Lamp off" ;
VAL_ 2566834688 FailureModeIdentifier1 31 "Not available" 19 "Received network data in error" 18 "Below normal (moderatels severe)" 17 "Below normal (least severe)" 16 "Above normal (moderately severe)" 15 "Above normal (least severe)" 14 "Special intstructions" 13 "Out of calibration" 12 "Bad intelligent device" 11 "Root cause not known" 10 "Abnormal rate of change" 9 "Abnormal update rate" 8 "Abnormal frequency" 7 "Mechanical system not responding" 6 "Current above normal" 5 "Current below normal" 4 "Voltage below normal" 3 "Voltage above normal" 2 "Data erratic" 1 "Below normal (most severe)" 0 "Above normal (most severe)" ;
VAL_ 2566834688 RedStopLampStatus 3 "Not available" 2 "Reserved" 1 "Lamp on" 0 "Lamp off" ;
VAL_ 2566834688 ProtectLampStatus 3 "Not available" 2 "Reserved" 1 "Lamp on" 0 "Lamp off" ;
VAL_ 2566834688 FailureModeIdentifier2 31 "Not available" 19 "Received network data in error" 18 "Below normal (moderatels severe)" 17 "Below normal (least severe)" 16 "Above normal (moderately severe)" 15 "Above normal (least severe)" 14 "Special intstructions" 13 "Out of calibration" 12 "Bad intelligent device" 11 "Root cause not known" 10 "Abnormal rate of change" 9 "Abnormal update rate" 8 "Abnormal frequency" 7 "Mechanical system not responding" 6 "Current above normal" 5 "Current below normal" 4 "Voltage below normal" 3 "Voltage above normal" 2 "Data erratic" 1 "Below normal (most severe)" 0 "Above normal (most severe)" ;
VAL_ 2565865739 TrailerABSWarningSignal 3 "Take no action" 2 "Reserved" 1 "On" 0 "Off" ;
VAL_ 2565865739 TrailerABSStatus 3 "Not Available" 2 "Reserved" 1 "Trailer ABS Active" 0 "Trailer ABS Not Active" ;
VAL_ 2565865739 ASRBrakeControlActive 3 "Not available" 2 "Reserved" 1 "ASR brake control active" 0 "ASR brake control passive" ;
VAL_ 2565865739 ABS_EBSAmberWarningSignal 3 "Take no action" 2 "Reserved" 1 "On" 0 "Off" ;
VAL_ 2565865739 ABSFullyOperational 3 "NotAvailable" 2 "Reserved" 1 "FullyOperational" 0 "NotFullyOperational" ;
VAL_ 2565865739 EngAuxEngShutdownSwitch 3 "NotAvailable" 2 "Error" 1 "On" 0 "Off" ;
VAL_ 2565865739 EngDerateSwitch 3 "NotAvailable" 2 "Error" 1 "On" 0 "Off" ;
VAL_ 2565865739 AccelInterlockSwitch 3 "NotAvailable" 2 "Error" 1 "On" 0 "Off" ;
VAL_ 2565865739 TractionCtrlOverrideSwitch 3 "NotAvailableNotInstalled" 2 "Error" 1 "On" 0 "Off" ;
VAL_ 2565865739 AntiLockBrakingActive 3 "NotAvailable" 2 "Reserved" 1 "ABSActive" 0 "ABSPassiveButInstalled" ;
VAL_ 2565668608 PGNumber 255 "NotAvailable" ;
VAL_ 2565668608 ControlByte 24 "EAbort" 23 "EEoMACK" 22 "EDPO" 21 "ECTS" 20 "ERTS" 3 "CannotRespond" 2 "AccessDenied" 1 "NACK" 0 "ACK" 255 "Abort" 32 "BAM" 19 "EoMA" 17 "CTS" 16 "RTS" ;
VAL_ 2565867774 FireApparatusPumpEngagement 3 "NotAvailableNotInstalled" 2 "Error" 1 "PumpEngaged" 0 "PumpNotEngaged" ;
VAL_ 2565867774 EngHydPressGovernorSwitch 3 "NotAvailable" 2 "ErrorIndicator" 1 "PressModeActive" 0 "PressModeInactive" ;
VAL_ 2566759457 EnggmntSttusTransInputShaftPTO1 3 "NotAvailable" 2 "Error" 1 "DriveIsEngaged" 0 "DriveNotEngaged" ;
VAL_ 2566759457 EnggmntSttusTransOutputShaftPTO 3 "NotAvailable" 2 "Error" 1 "DriveIsEngaged" 0 "DriveNotEngaged" ;
VAL_ 2566759457 EnggmntSttsTrnsfrCsOtptShaftPTO 3 "NotAvailable" 2 "Error" 1 "DriveIsEngaged" 0 "DriveNotEngaged" ;
VAL_ 2566758656 Aftertreatment1FuelDrainAct 11 "notAvailable" 10 "reservedForSAEAssignment" 1 "active" 0 "notActive" ;
VAL_ 2566758656 Aftertreatment1FuelActuator 3 "notAvailable" 2 "reservedForSAEAssignment" 1 "active" 0 "notActive" ;
VAL_ 2566758656 Aftertreatment1RegenStatus 3 "notAvailable" 2 "reservedForSAEAssignment" 1 "active" 0 "notActive" ;
VAL_ 2566764544 PMFilterMonComplete 1 "NOTCompleteForCycle" 0 "Completerforcycle" ;
VAL_ 2566764544 NOxCnvrtctlystMonComplete 1 "NOTCompletethiscycle" 0 "Completethiscycle" ;
VAL_ 2566764544 NHMCCnvrtctlystMonComplete 1 "NOTcompletethiscycle" 0 "Completethiscycle" ;
VAL_ 2566764544 BstPressCtrlSystemMoncomplete 1 "notcompletethismonitorcycle" 0 "Completeforthismonitorcycle" ;
VAL_ 2566764544 NHMCCnvrtctlystMonEnabled 1 "EnabledForCycle" 0 "DisabledForRestOfCycle" ;
VAL_ 2566764544 NOxCnvrtctlystMonEnabled 1 "EnabledForCycle" 0 "DisabledForRestOfCycle" ;
VAL_ 2566764544 PMFilterMonEnabled 1 "EnabledForCycle" 0 "DisabledForRestOfCycle" ;
VAL_ 2566764544 BstPressCtrlSystemMonEnabled 1 "EnabledForCycle" 0 "DisabledForRestOfCycle" ;
VAL_ 2566764544 MisfireMonitoringComplete 1 "EnabledForCycle" 0 "DisabledForRestOfCycle" ;
VAL_ 2566764544 MisfireMonitoringEnabled 1 "EnabledForCycle" 0 "DisabledForRestOfCycle" ;
VAL_ 2566764544 FuelSystemMonitoringEnabled 1 "NotCompleteCycle" 0 "CompleteCycleOrNotSupported" ;
VAL_ 2566764544 ComprehensiveComptMonComplete 1 "NotCompleteCycle" 0 "CompleteCycleOrNotSupported" ;
VAL_ 2566764544 ComprehensiveCompMonEnabled 1 "NotCompleteCycle" 0 "CompleteCycleOrNotSupported" ;
VAL_ 2566764544 SecondAirSystemMonComplete 1 "EnabledForCycle" 0 "DisabledForRestOfCycle" ;
VAL_ 2566764544 SecondAirSystemMonEnabled 1 "EnabledForCycle" 0 "DisabledForRestOfCycle" ;
VAL_ 2566764544 OxygenSensorMonComplete 1 "EnabledForCycle" 0 "DisabledForRestOfCycle" ;
VAL_ 2566764544 OxygenSensorMonEnabled 1 "NotCompleteCycle" 0 "CompleteCycleOrNotSupported" ;
VAL_ 2566764544 OxygenSensorHeaterMonComplete 1 "EnabledForCycle" 0 "DisabledForRestOfCycle" ;
VAL_ 2566764544 OxygenSensorHeaterMonEnabled 1 "NotCompleteCycle" 0 "CompleteCycleOrNotSupported" ;
VAL_ 2566764544 HeatedCatalystMonComplete 1 "EnabledForCycle" 0 "DisabledForRestOfCycle" ;
VAL_ 2566764544 HeatedCatalystMonEnabled 1 "EnabledForCycle" 0 "DisabledForRestOfCycle" ;
VAL_ 2566764544 EvaporativeSystemMonComplete 1 "NotCompleteCycle" 0 "CompleteCycleOrNotSupported" ;
VAL_ 2566764544 EvaporativeSystemMonEnabled 1 "NotCompleteCycle" 0 "CompleteCycleOrNotSupported" ;
VAL_ 2566764544 EGRSystemMonitoringComplete 1 "NotCompleteCycle" 0 "CompleteCycleOrNotSupported" ;
VAL_ 2566764544 EGRSystemMonitoringEnabled 1 "EnabledForCycle" 0 "DisabledForRestOfCycle" ;
VAL_ 2566764544 ColdStartAidSystemMonComplete 1 "EnabledForCycle" 0 "DisabledForRestOfCycle" ;
VAL_ 2566764544 ColdStartAidSystemMonEnabled 1 "EnabledForCycle" 0 "DisabledForRestOfCycle" ;
VAL_ 2566764544 CatalystMonComplete 1 "NotCompleteCycle" 0 "CompleteCycleOrNotSupported" ;
VAL_ 2566764544 CatalystMonEnabled 1 "NotCompleteCycle" 0 "CompleteCycleOrNotSupported" ;
VAL_ 2566764544 ACSystemRefrigerantMonComplete 1 "NotCompleteCycle" 0 "CompleteCycleOrNotSupported" ;
VAL_ 2566764544 ACSystemRefrigerantMonEnabled 1 "NotCompleteCycle" 0 "CompleteCycleOrNotSupported" ;
VAL_ 2566764544 FuelSystemMonitoringComplete 1 "NotCompleteCycle" 0 "CompleteCycleOrNotSupported" ;
VAL_ 2348810243 OverrideCtrlModePriority 3 "LowPriority" 2 "MdmPrrtyUsdFrPwrtrnCtrlOprtnsWh" 1 "HighPriority" 0 "HghstPrrtyUsdFrSttnsThtRqrImmdt" ;
VAL_ 2348810243 EngOverrideCtrlMode 3 "Spd_TrqLmtCtrlLmtSpdAnd_OrTrqBs" 2 "TrqCtrlCntrlTrqTInclddDsrdTrqVl" 1 "SpdCtrlGvrnSpdTInclddDsrdSpdVle" 0 "OvrrdDsbldDsblAnyExstngCtrlCmdd" ;
VAL_ 2566838784 ASCIIfromHEX7 90 "Z" 89 "Y" 88 "X" 87 "W" 86 "V" 85 "U" 84 "T" 83 "S" 82 "R" 81 "Q" 80 "P" 79 "O" 78 "N" 77 "M" 76 "L" 75 "K" 74 "J" 73 "I" 72 "H" 71 "G" 70 "F" 69 "E" 68 "D" 67 "C" 66 "B" 65 "A" 57 "9" 56 "8" 55 "7" 54 "6" 53 "5" 52 "4" 51 "3" 50 "2" 49 "1" 48 "0" ;
VAL_ 2566838784 ASCIIfromHEX6 90 "Z" 89 "Y" 88 "X" 87 "W" 86 "V" 85 "U" 84 "T" 83 "S" 82 "R" 81 "Q" 80 "P" 79 "O" 78 "N" 77 "M" 76 "L" 75 "K" 74 "J" 73 "I" 72 "H" 71 "G" 70 "F" 69 "E" 68 "D" 67 "C" 66 "B" 65 "A" 57 "9" 56 "8" 55 "7" 54 "6" 53 "5" 52 "4" 51 "3" 50 "2" 49 "1" 48 "0" ;
VAL_ 2566838784 ASCIIfromHEX5 90 "Z" 89 "Y" 88 "X" 87 "W" 86 "V" 85 "U" 84 "T" 83 "S" 82 "R" 81 "Q" 80 "P" 79 "O" 78 "N" 77 "M" 76 "L" 75 "K" 74 "J" 73 "I" 72 "H" 71 "G" 70 "F" 69 "E" 68 "D" 67 "C" 66 "B" 65 "A" 57 "9" 56 "8" 55 "7" 54 "6" 53 "5" 52 "4" 51 "3" 50 "2" 49 "1" 48 "0" ;
VAL_ 2566838784 ASCIIfromHEX4 90 "Z" 89 "Y" 88 "X" 87 "W" 86 "V" 85 "U" 84 "T" 83 "S" 82 "R" 81 "Q" 80 "P" 79 "O" 78 "N" 77 "M" 76 "L" 75 "K" 74 "J" 73 "I" 72 "H" 71 "G" 70 "F" 69 "E" 68 "D" 67 "C" 66 "B" 65 "A" 57 "9" 56 "8" 55 "7" 54 "6" 53 "5" 52 "4" 51 "3" 50 "2" 49 "1" 48 "0" ;
VAL_ 2566838784 ASCIIfromHEX3 90 "Z" 89 "Y" 88 "X" 87 "W" 86 "V" 85 "U" 84 "T" 83 "S" 82 "R" 81 "Q" 80 "P" 79 "O" 78 "N" 77 "M" 76 "L" 75 "K" 74 "J" 73 "I" 72 "H" 71 "G" 70 "F" 69 "E" 68 "D" 67 "C" 66 "B" 65 "A" 57 "9" 56 "8" 55 "7" 54 "6" 53 "5" 52 "4" 51 "3" 50 "2" 49 "1" 48 "0" ;
VAL_ 2566838784 ASCIIfromHEX2 90 "Z" 89 "Y" 88 "X" 87 "W" 86 "V" 85 "U" 84 "T" 83 "S" 82 "R" 81 "Q" 80 "P" 79 "O" 78 "N" 77 "M" 76 "L" 75 "K" 74 "J" 73 "I" 72 "H" 71 "G" 70 "F" 69 "E" 68 "D" 67 "C" 66 "B" 65 "A" 57 "9" 56 "8" 55 "7" 54 "6" 53 "5" 52 "4" 51 "3" 50 "2" 49 "1" 48 "0" ;
VAL_ 2566838784 ASCIIfromHEX1 90 "Z" 89 "Y" 88 "X" 87 "W" 86 "V" 85 "U" 84 "T" 83 "S" 82 "R" 81 "Q" 80 "P" 79 "O" 78 "N" 77 "M" 76 "L" 75 "K" 74 "J" 73 "I" 72 "H" 71 "G" 70 "F" 69 "E" 68 "D" 67 "C" 66 "B" 65 "A" 57 "9" 56 "8" 55 "7" 54 "6" 53 "5" 52 "4" 51 "3" 50 "2" 49 "1" 48 "0" ;
VAL_ 2566841344 EngProtectionSystemConfig 3 "NotAvailable" 2 "Error" 1 "EnabledInCalib" 0 "DisabledInCalib" ;
VAL_ 2566841344 EngProtectionSystemTimerState 3 "NotAvailable" 2 "Error" 1 "Active" 0 "Inactive" ;
VAL_ 2566841344 EngPrtectionSystemTimerOverride 3 "NotAvailable" 2 "Error" 1 "Active" 0 "Inactive" ;
VAL_ 2566841344 EngPrtctnSystmApprchingShutdown 3 "NotAvailable" 2 "Error" 1 "Approaching" 0 "NotApproaching" ;
VAL_ 2566841344 EngPrtctionSystemHasShutdownEng 0 "No" ;
VAL_ 2566841344 EngWaitToStartLamp 3 "NotAvailable" 2 "Error" 1 "On" 0 "Off" ;
VAL_ 2566841344 EngIdleShutdownTimerFunction 3 "NotAvailable" 2 "Error" 1 "EnabledInCalib" 0 "DisabledInCalib" ;
VAL_ 2566841344 EngIdleShutdownTimerState 3 "NotAvailable" 2 "Error" 1 "Active" 0 "Inactive" ;
VAL_ 2566841344 EngIdleShutdownTimerOverride 3 "NotAvailable" 2 "Error" 1 "Active" 0 "Inactive" ;
VAL_ 2566841344 EngIdleShutdownDriverAlertMode 3 "NotAvailable" 2 "Error" 1 "Active" 0 "Inactive" ;
VAL_ 2566841344 EngIdleShutdownHasShutdownEng 1 "Yes" 0 "No" ;
VAL_ 2631859966 TripGroup2_Proprietary 2 "Reserved" 3 "NotApplicable" 1 "Reset" 0 "TakeNoAction" ;
VAL_ 2631859966 TripGroup1 2 "Reserved" 3 "NotApplicable" 1 "Reset" 0 "TakeNoAction" ;
VAL_ 2566840591 RetarderLocation 15 "NotAvailable" 14 "Other" 6 "1101NotDefined" 5 "Trailer" 4 "Driveline" 3 "TransOutput" 2 "TransInput" 1 "EngExhaustBrake" 0 "EngCompressionReleaseBrake" ;
VAL_ 2566840591 RetarderType 15 "NotAvailable" 14 "Other" 5 "1101NotDefined" 4 "Exhaust" 3 "CompressionRelease" 2 "CooledFriction" 1 "Hyd" 0 "Electric_Magnetic" ;
VAL_ 2566844449 EngPTOAccelerateSwitch 3 "NotAvailable" 2 "Error" 1 "On" 0 "Off" ;
VAL_ 2566844449 EngPTOResumeSwitch 3 "NotAvailable" 2 "Error" 1 "On" 0 "Off" ;
VAL_ 2566844449 EngPTOCoast_DecelerateSwitch 3 "NotAvailable" 2 "Error" 1 "On" 0 "Off" ;
VAL_ 2566844449 EngPTOSetSwitch 3 "NotAvailable" 2 "Error" 1 "On" 0 "Off" ;
VAL_ 2566844449 EngRmtPTOVriableSpeedCtrlSwitch 3 "NotAvailable" 2 "Error" 1 "On" 0 "Off" ;
VAL_ 2566844449 EngRmtPTOPrprgrmmdSpdCtrlSwitch 3 "NotAvailable" 2 "Error" 1 "On" 0 "Off" ;
VAL_ 2566844449 EngPTOEnableSwitch 3 "NotAvailable" 2 "Error" 1 "On" 0 "Off" ;
VAL_ 2566844449 RmtPTOPrprgrmmdSpeedCtrlSwitch2 3 "NotAvailable" 2 "Error" 1 "On" 0 "Off" ;
VAL_ 2566831360 FanDriveState 15 "NotAvailable" 14 "Other" 13 "EngBrake" 12 "Timer" 11 "A_CSystem" 10 "TransRetarder" 9 "ManualCtrl" 8 "AftertreatmentRegenActive" 7 "DefaultOperation" 6 "ExcessiveHydOilTemp" 5 "ExcessiveTransOilTemp" 4 "ExcessiveEngCoolantTemp" 3 "ExcessiveEngOilTemp" 2 "ExcessiveEngAirTemp" 1 "EngSystemGeneral" 0 "FanOff" ;
VAL_ 2364539395 ProgressiveShiftDisable 3 "Take no action" 2 "Reserved" 1 "Progressive shift is disabled" 0 "Progressive shift not disabled" ;
VAL_ 2364539395 EngineMomOverspdEnable 3 "Take no action" 2 "Reserved" 1 "Moment. eng. overspeed enabled" 0 "Moment. eng. overspeed disabled" ;
VAL_ 2364539395 TransShiftInProcess 3 "NotAvailable" 2 "Error" 1 "ShiftInProcess" 0 "ShiftIsNotInProcess" ;
VAL_ 2364539395 TorqueConverterLockupEngaged 3 "NotAvailable" 2 "Error" 1 "TorqueConverterLockupEngaged" 0 "TorqueConverterLockupDisengaged" ;
VAL_ 2364539395 TransDrivelineEngaged 3 "NotAvailable" 2 "Error" 1 "DrivelineEngaged" 0 "DrivelineDisengaged" ;
VAL_ 2566771968 EngFuelControlStatus 3 "Not available" 2 "Reserved" 1 "Closed loop" 0 "Open loop" ;
VAL_ 2364539648 RoadSpeedLimitStatus 3 "NotAvailable" 2 "Error" 1 "NotActive" 0 "Active" ;
VAL_ 2364539648 AccelPedal1LowIdleSwitch 3 "NotAvailable" 2 "Error" 1 "AccelPedal1InLowIdleCondition" 0 "AcclPedal1NotInLowIdleCondition" ;
VAL_ 2364539904 EngStarterMode 15 "notAvailable" 14 "error" 12 "starterInhibitedReasonUnknown" 9 "1011Reserved" 8 "strtrInhbtdDueToStarterOvertemp" 7 "strtrInhbtdDToActiveImmobilizer" 6 "strtrInhbtdDTDrvlnEnggdOthrTrns" 5 "strtrInhbtdDTEngNtReadyForStart" 4 "strtrInhbtdDToEngAlreadyRunning" 3 "strtFnshdStrtrNtActvAftrHvngBnA" 2 "starterActiveGearEngaged" 1 "starterActiveGearNotEngaged" 0 "startNotRqed" ;
VAL_ 2364539904 EngTorqueMode 15 "Not available" 11 "Remote accelerator" 10 "Braking system" 9 "High speed governor" 8 "Torque limiting" 7 "ABS control" 6 "Transmission control" 5 "ASR control" 4 "Road speed governor" 3 "PTO governor" 2 "Cruise control" 1 "Accelerator pedal/operator selec" 0 "Low idle governor/no request (de" ;
